VERSION ""

NS_ :

BS_:

BU_: ABS vDSU_FD_C vFD_C ECS RCU ICSC ESC RWS TPMS GW_RGW EPB FCU_C SAS EBB CGW_CCU MDPS RWA VPC_C BDC_C SFA

BO_ 2683321087 SFA_Mon_300ms: 24 SFA
 SG_ SFA_History_DTC : 89|24@1+ (1,0) [0|0] "" Vector__XXX
 SG_ SFA_DTC_Status : 113|1@1+ (1,0) [0|1] "" Vector__XXX
 SG_ SFA_DTC : 65|24@1+ (1,0) [0|0] "" Vector__XXX
 SG_ Align_DiffAg : 49|16@1- (0.1,0) [0|0] "Deg" Vector__XXX
 SG_ ECU1_PrvCANSts : 1|1@1+ (1,0) [0|1] "" Vector__XXX
 SG_ SFA_IMCStatus : 0|1@1+ (1,0) [0|1] "" Vector__XXX
 SG_ SFA1_Yawrate : 17|16@1+ (0.005,-163.84) [-163.84|163.83] "Deg/s" Vector__XXX
 SG_ SFA1_OLPStatus : 16|1@1+ (1,0) [0|1] "" Vector__XXX
 SG_ SFA1_OHPStatus : 15|1@1+ (1,0) [0|1] "" Vector__XXX
 SG_ SFA1_MotorCur : 129|16@1- (0.1,0) [-200|200] "A" Vector__XXX
 SG_ SFA1_LatG : 33|16@1+ (0.000127465,-4.17677312) [-4.17677312|4.1765] "g" Vector__XXX
 SG_ SFA1_IGNStatus : 14|1@1+ (1,0) [0|1] "" Vector__XXX
 SG_ SFA1_BatteryVoltage : 2|12@1+ (0.01,0) [0|40.95] "V" Vector__XXX

BO_ 2683325183 RWA_Mon_300ms: 24 RWA
 SG_ RWA_IMCStatus : 0|1@1+ (1,0) [0|1] "" Vector__XXX
 SG_ RWA_History_DTC : 54|24@1+ (1,0) [0|0] "" Vector__XXX
 SG_ RWA_DTC_Status : 78|1@1+ (1,0) [0|1] "" Vector__XXX
 SG_ RWA_DTC : 30|24@1+ (1,0) [0|0] "" Vector__XXX
 SG_ RWA1_IGNStatus : 13|1@1+ (1,0) [0|1] "" Vector__XXX
 SG_ RWA1_BatteryVoltage : 1|12@1+ (0.01,0) [0|41] "V" Vector__XXX
 SG_ RWA1_AbsoulteAng : 14|16@1- (0.1,0) [0|0] "Deg" Vector__XXX

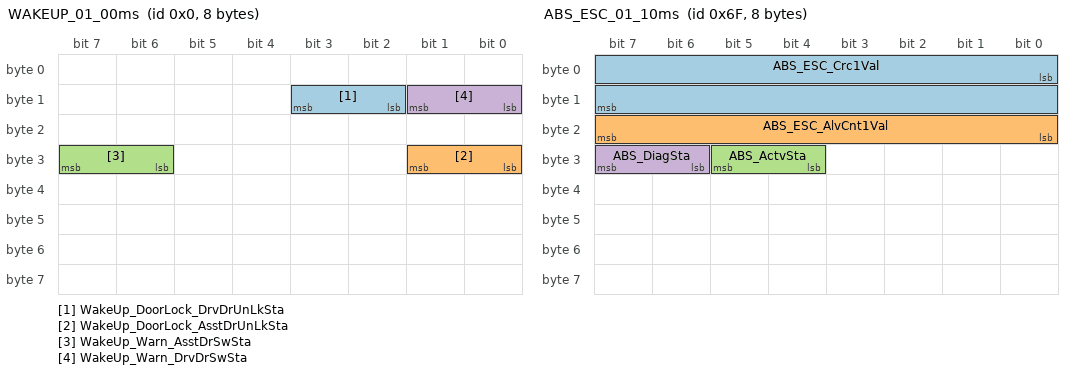
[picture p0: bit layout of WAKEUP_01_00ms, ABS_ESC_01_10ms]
BO_ 0 WAKEUP_01_00ms: 8 CGW_CCU
 SG_ WakeUp_DoorLock_DrvDrUnLkSta : 10|2@1+ (1,0) [0|0] ""  GW_RGW,RWA,SFA
 SG_ WakeUp_DoorLock_AsstDrUnLkSta : 24|2@1+ (1,0) [0|0] ""  GW_RGW,RWA,SFA
 SG_ WakeUp_Warn_AsstDrSwSta : 30|2@1+ (1,0) [0|0] ""  GW_RGW,RWA,SFA
 SG_ WakeUp_Warn_DrvDrSwSta : 8|2@1+ (1,0) [0|0] ""  GW_RGW,RWA,SFA

BO_ 548 ALDC_01_100ms: 32 CGW_CCU
 SG_ ALDC_Crc1Val : 0|16@1+ (1,0) [0|0] ""  RWA,SFA
 SG_ ALDC_AlvCnt1Val : 16|8@1+ (1,0) [0|0] ""  RWA,SFA
 SG_ ALDC_SysOpSta : 28|2@1+ (1,0) [0|0] ""  RWA,SFA
 SG_ ALDC_SysFltSta : 42|2@1+ (1,0) [0|0] ""  RWA,SFA

BO_ 549 CLU_02_100ms: 16 CGW_CCU
 SG_ CLU_Crc2Val : 0|16@1+ (1,0) [0|0] ""  BDC_C,ESC,GW_RGW,ICSC,MDPS,RCU,SFA,VPC_C
 SG_ CLU_DrvngModSwSta : 104|4@1+ (1,0) [0|0] ""  ECS,ESC,GW_RGW,ICSC,MDPS,RCU,SFA,VPC_C
 SG_ CLU_AlvCnt2Val : 16|8@1+ (1,0) [0|0] ""  BDC_C,ESC,GW_RGW,ICSC,MDPS,RCU,SFA,VPC_C

BO_ 517 ICSC_02_100ms: 24 ICSC
 SG_ ICSC_Crc2Val : 0|16@1+ (1,0) [0|0] ""  CGW_CCU,ECS,ESC,GW_RGW,RCU,RWS,SFA,VPC_C
 SG_ ICSC_AlvCnt2Val : 16|8@1+ (1,0) [0|0] ""  CGW_CCU,ECS,ESC,GW_RGW,RCU,RWS,SFA,VPC_C
 SG_ DMIC_MdpsModSta : 56|4@1+ (1,0) [0|0] ""  GW_RGW,MDPS,SFA

BO_ 520 HOD_FD_01_100ms: 16 CGW_CCU
 SG_ HOD_FD_Crc1Val : 0|16@1+ (1,0) [0|0] ""  GW_RGW,SFA
 SG_ HOD_FD_AlvCnt1Val : 16|8@1+ (1,0) [0|0] ""  GW_RGW,SFA
 SG_ HOD_Dir_Status : 80|3@1+ (1,0) [0|0] ""  GW_RGW,SFA
 SG_ HOD_Option : 88|2@1+ (1,0) [0|0] ""  GW_RGW,SFA

BO_ 53 VCU_01_10ms: 32 CGW_CCU
 SG_ VCU_Crc1Val : 0|16@1+ (1,0) [0|0] ""  BDC_C,ESC,MDPS,RWA,RWS,SFA
 SG_ VCU_AlvCnt1Val : 16|8@1+ (1,0) [0|0] ""  BDC_C,ESC,MDPS,RWA,RWS,SFA
 SG_ VCU_EvDrvRdySta : 28|2@1+ (1,0) [0|3] ""  BDC_C,ECS,EPB,ESC,MDPS,RWA,RWS,SFA
 SG_ VCU_GearPosSta : 32|4@1+ (1,0) [0|15] ""  BDC_C,ECS,EPB,ESC,MDPS,RWA,RWS,SFA
 SG_ VCU_AccPedDepVal : 40|8@1+ (0.3921568627,0) [0|100] "%"  ECS,EPB,ESC,MDPS,RWA,RWS,SFA

BO_ 64 TCU_01_10ms: 32 CGW_CCU
 SG_ TCU_Crc1Val : 0|16@1+ (1,0) [0|0] ""  BDC_C,MDPS,RWS,SFA
 SG_ TCU_AlvCnt1Val : 16|8@1+ (1,0) [0|0] ""  BDC_C,MDPS,RWS,SFA
 SG_ TCU_CurrGearSta : 64|4@1+ (1,0) [0|0] ""  MDPS,SFA

BO_ 74 IMU_01_10ms: 32 CGW_CCU
 SG_ IMU_Crc1Val : 0|16@1+ (1,0) [0|0] ""  ECS,ESC,FCU_C,GW_RGW,ICSC,MDPS,RCU,RWS,SFA,VPC_C
 SG_ IMU_AlvCnt1Val : 16|8@1+ (1,0) [0|0] ""  ECS,ESC,FCU_C,GW_RGW,ICSC,MDPS,RCU,RWS,SFA,VPC_C
 SG_ IMU_YawSigSta : 24|4@1+ (1,0) [0|0] ""  ESC,FCU_C,GW_RGW,MDPS,RCU,RWS,SFA,VPC_C
 SG_ IMU_LatAccelSigSta : 28|4@1+ (1,0) [0|0] ""  ECS,ESC,FCU_C,GW_RGW,MDPS,RCU,RWS,SFA,VPC_C
 SG_ IMU_AcuRstSta : 44|4@1+ (1,0) [0|0] ""  ECS,ESC,GW_RGW,MDPS,RCU,SFA
 SG_ IMU_YawRtVal : 64|16@1+ (0.005,-163.84) [0|0] "˚/s"  ESC,FCU_C,GW_RGW,ICSC,MDPS,RCU,RWS,SFA,VPC_C
 SG_ IMU_LatAccelVal : 80|16@1+ (0.000127465,-4.17677312) [0|0] "g"  ECS,ESC,FCU_C,GW_RGW,ICSC,MDPS,RCU,RWS,SFA,VPC_C

BO_ 101 IEB_01_10ms: 32 ESC
 SG_ IEB_BrkActvSta : 56|2@1+ (1,0) [0|0] ""  CGW_CCU,EPB,GW_RGW,MDPS,RCU,SFA

BO_ 96 ESC_01_10ms: 32 ESC
 SG_ ESC_Crc1Val : 0|16@1+ (1,0) [0|0] ""  CGW_CCU,FCU_C,MDPS,RCU,RWS,SFA,VPC_C
 SG_ ESC_CylPrsrVal : 128|12@1+ (0.1,0) [0|0] "Bar"  CGW_CCU,ECS,EPB,ICSC,MDPS,RCU,RWS,SFA,VPC_C
 SG_ ESC_VsmActvSta : 152|2@1+ (1,0) [0|0] ""  CGW_CCU,MDPS,RCU,SFA
 SG_ ESC_VsmDfctvSta : 154|2@1+ (1,0) [0|0] ""  MDPS,RCU,SFA
 SG_ ESC_VsmCtrlModSta : 156|3@1+ (1,0) [0|0] ""  MDPS,RCU,SFA
 SG_ ESC_AlvCnt1Val : 16|8@1+ (1,0) [0|0] ""  CGW_CCU,FCU_C,MDPS,RCU,RWS,SFA,VPC_C
 SG_ ESC_StrTqReq : 160|12@1+ (0.01,-20.48) [0|0] "Nm"  MDPS,RCU,SFA
 SG_ TCS_Sta : 64|4@1+ (1,0) [0|0] ""  CGW_CCU,EPB,FCU_C,ICSC,MDPS,RCU,RWS,SFA,VPC_C
 SG_ ESC_Sta : 72|4@1+ (1,0) [0|0] ""  CGW_CCU,ECS,EPB,FCU_C,ICSC,MDPS,RCU,RWS,SFA,VPC_C

BO_ 111 ABS_ESC_01_10ms: 8 ESC
 SG_ ABS_ESC_Crc1Val : 0|16@1+ (1,0) [0|0] ""  CGW_CCU,FCU_C,MDPS,RCU,RWS,SFA,VPC_C
 SG_ ABS_ESC_AlvCnt1Val : 16|8@1+ (1,0) [0|0] ""  CGW_CCU,FCU_C,MDPS,RCU,RWS,SFA,VPC_C
 SG_ ABS_ActvSta : 28|2@1+ (1,0) [0|0] ""  CGW_CCU,ECS,EPB,FCU_C,ICSC,MDPS,RCU,RWS,SFA,VPC_C
 SG_ ABS_DiagSta : 30|2@1+ (1,0) [0|0] ""  CGW_CCU,EPB,MDPS,RCU,SFA,VPC_C

BO_ 597 LDC_01_100ms: 32 CGW_CCU
 SG_ LDC_Crc1Val : 0|16@1+ (1,0) [0|0] ""  RWA,SFA
 SG_ LDC_AlvCnt1Val : 16|8@1+ (1,0) [0|0] ""  RWA,SFA
 SG_ LDC_SysOpSta : 28|2@1+ (1,0) [0|0] ""  RWA,SFA
 SG_ LDC_SysFltSta : 42|2@1+ (1,0) [0|0] ""  RWA,SFA

BO_ 647 CCU_MCU_01_200ms: 8 CGW_CCU
 SG_ CCU_update_enable : 26|2@1- (1,0) [0|0] ""  ESC,GW_RGW,MDPS,RWA,SFA

BO_ 160 WHL_01_10ms: 24 ABS
 SG_ WHL_Crc1Val : 0|16@1+ (1,0) [0|0] ""  BDC_C,CGW_CCU,FCU_C,MDPS,RCU,RWA,RWS,SFA,VPC_C
 SG_ WHL_SpdRRVal : 112|14@1+ (0.03125,0) [0|0] "km^h"  BDC_C,CGW_CCU,ECS,EPB,FCU_C,MDPS,RCU,RWA,RWS,SFA,TPMS,VPC_C
 SG_ WHL_AlvCnt1Val : 16|8@1+ (1,0) [0|0] ""  BDC_C,CGW_CCU,FCU_C,MDPS,RCU,RWA,RWS,SFA,VPC_C
 SG_ WHL_SpdFLVal : 64|14@1+ (0.03125,0) [0|0] "km^h"  BDC_C,CGW_CCU,ECS,EPB,FCU_C,MDPS,RCU,RWA,RWS,SFA,TPMS,VPC_C,vDSU_FD_C
 SG_ WHL_SpdFRVal : 80|14@1+ (0.03125,0) [0|0] "km^h"  BDC_C,CGW_CCU,ECS,EPB,FCU_C,MDPS,RCU,RWA,RWS,SFA,TPMS,VPC_C
 SG_ WHL_SpdRLVal : 96|14@1+ (0.03125,0) [0|0] "km^h"  BDC_C,CGW_CCU,ECS,EPB,FCU_C,MDPS,RCU,RWA,RWS,SFA,TPMS,VPC_C

BO_ 176 ICSC_01_10ms: 32 VPC_C
 SG_ ICSC_Crc1Val : 0|16@1+ (1,0) [0|0] ""  CGW_CCU,ECS,ESC,GW_RGW,RCU,RWS,SFA
 SG_ ICSC_AlvCnt1Val : 16|8@1+ (1,0) [0|0] ""  CGW_CCU,ECS,ESC,GW_RGW,RCU,RWS,SFA
 SG_ ESA_MdpsStrTqReq : 168|12@1+ (0.01,-20.48) [0|0] ""  ECS,ESC,GW_RGW,MDPS,SFA
 SG_ ESA_MdpsActvSta : 180|2@1+ (1,0) [0|0] ""  ECS,ESC,GW_RGW,MDPS,SFA
 SG_ ESA_MdpsDfctvSta : 182|2@1+ (1,0) [0|0] ""  ECS,ESC,GW_RGW,MDPS,SFA
 SG_ SFO_ActvSta : 232|3@1+ (1,0) [0|0] ""  GW_RGW,SFA

BO_ 745 PDC_FD_15_300ms: 32 CGW_CCU
 SG_ PDC_FD_Crc15Val : 0|16@1+ (1,0) [0|0] ""  ABS,EBB,ECS,EPB,ESC,GW_RGW,ICSC,MDPS,RCU,RWA,RWS,SAS,SFA,TPMS
 SG_ PDC_FD_AlvCnt15Val : 16|8@1+ (1,0) [0|0] ""  ABS,EBB,ECS,EPB,ESC,GW_RGW,ICSC,MDPS,RCU,RWA,RWS,SAS,SFA,TPMS
 SG_ PDC_ResetPreWrngForOthers : 42|2@1+ (1,0) [0|0] ""  ABS,EBB,ECS,EPB,ESC,GW_RGW,ICSC,MDPS,RCU,RWA,RWS,SAS,SFA,TPMS
 SG_ PDC_ResetReqForOthers : 46|2@1+ (1,0) [0|0] ""  ABS,EBB,ECS,EPB,ESC,GW_RGW,ICSC,MDPS,RCU,RWA,RWS,SAS,SFA,TPMS

BO_ 203 ADAS_CMD_35_10ms: 24 CGW_CCU
 SG_ ADAS_CMD_Crc35Val : 0|16@1+ (1,0) [0|0] "0"  FCU_C,GW_RGW,MDPS,SFA
 SG_ ADAS_CMD_AlvCnt35Val : 16|8@1+ (1,0) [0|0] "0"  FCU_C,GW_RGW,MDPS,SFA
 SG_ ADAS_ActvACISta : 24|4@1+ (1,0) [0|0] ""  GW_RGW,MDPS,SFA
 SG_ ADAS_ActvACILvl2Sta : 28|4@1+ (1,0) [0|0] ""  ESC,FCU_C,GW_RGW,MDPS,SFA,VPC_C
 SG_ ADAS_StrAnglReqVal : 32|14@1- (0.1,0) [0|0] "Deg"  GW_RGW,MDPS,SFA
 SG_ ADAS_ACIAnglTqRedcGainVal : 48|8@1+ (0.004,0) [0|0] ""  GW_RGW,MDPS,SFA
 SG_ FCA_ESA_ActvSta : 56|2@1+ (1,0) [0|0] ""  GW_RGW,MDPS,SFA
 SG_ FCA_ESA_TqBstGainVal : 64|8@1+ (0.004,0) [0|0] ""  GW_RGW,MDPS,SFA

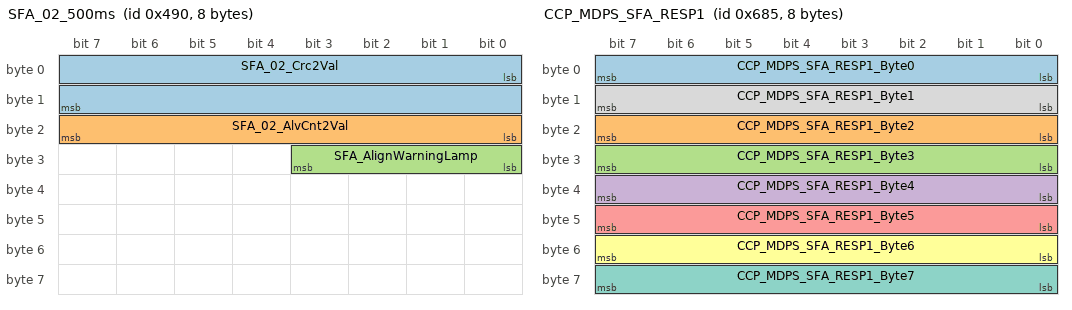
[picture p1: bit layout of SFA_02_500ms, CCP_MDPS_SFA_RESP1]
BO_ 1168 SFA_02_500ms: 8 SFA
 SG_ SFA_02_Crc2Val : 0|16@1+ (1,0) [0|0] "0"  CGW_CCU
 SG_ SFA_02_AlvCnt2Val : 16|8@1+ (1,0) [0|0] "0"  CGW_CCU
 SG_ SFA_AlignWarningLamp : 24|4@1+ (1,0) [0|0] ""  CGW_CCU

BO_ 221 SFA_01_10ms: 32 SFA
 SG_ Rack_Command_Diff : 180|20@1+ (0.001,-524) [0|0] "" Vector__XXX
 SG_ SFA1_RelativeAg : 164|16@1- (0.1,0) [0|0] "Deg" Vector__XXX
 SG_ SFA1_MotorTq : 136|12@1+ (0.1,-204.8) [0|0] "Nm" Vector__XXX
 SG_ SFA1_AbsoluteAg : 148|16@1- (0.1,0) [0|0] "Deg" Vector__XXX
 SG_ SFA_Crc1Val : 0|16@1+ (1,0) [0|0] "0"  CGW_CCU,GW_RGW,RWA,RWS
 SG_ SFA_CenteringStatus : 102|3@1+ (1,0) [0|0] ""  GW_RGW,RWA
 SG_ SbW_CenteringStatus : 105|3@1+ (1,0) [0|0] ""  GW_RGW,RWA
 SG_ SFA_IgnitionStatus : 108|1@1+ (1,0) [0|0] ""  GW_RGW,RWA
 SG_ SFA_OHP_Status : 109|1@1+ (1,0) [0|0] ""  GW_RGW,RWA
 SG_ SFA_SFA1EcuStatus : 110|4@1+ (1,0) [0|0] ""  GW_RGW,RWA
 SG_ SFA_SFA2EcuStatus : 114|4@1+ (1,0) [0|0] ""  GW_RGW,RWA
 SG_ SFA_RWA1EcuStatus : 118|4@1+ (1,0) [0|0] ""  GW_RGW,RWA
 SG_ SFA_RWA2EcuStatus : 122|4@1+ (1,0) [0|0] ""  GW_RGW,RWA
 SG_ SFA_SteerWheelAngSpd : 128|8@1+ (4,0) [0|0] "Deg/s"  GW_RGW,RWA,VPC_C
 SG_ SFA_AlvCnt1Val : 16|8@1+ (1,0) [0|0] "0"  CGW_CCU,GW_RGW,RWA,RWS
 SG_ SFA_SteerWheelTorque : 24|12@1+ (0.02,-40) [0|0] ""  GW_RGW,RWA
 SG_ SFA_SteerWheelAngle : 36|16@1+ (0.02,-655) [0|0] ""  GW_RGW,RWA,VPC_C
 SG_ Reprogram_State_SFA1 : 52|2@1+ (1,0) [0|0] ""  CGW_CCU
 SG_ SFA1_ResetOpSta : 54|2@1+ (1,0) [0|0] "" Vector__XXX
 SG_ SFA_ControlMode : 56|3@1+ (1,0) [0|0] ""  GW_RGW,RWA
 SG_ SFA_EcuRole : 59|2@1+ (1,0) [0|0] ""  GW_RGW,RWA
 SG_ SFA_WarningLamp : 61|3@1+ (1,0) [0|0] ""  GW_RGW,RWA
 SG_ SFA_RackCommand : 64|20@1+ (0.001,-524) [0|0] ""  GW_RGW,RWA
 SG_ SFA_FailoverActvSta : 84|3@1+ (1,0) [0|0] ""  GW_RGW,RWA,RWS,VPC_C
 SG_ SFA_BrakeReqActSta : 87|3@1+ (1,0) [0|0] ""  GW_RGW,RWA
 SG_ SFA_CreepReqActSta : 90|3@1+ (1,0) [0|0] ""  GW_RGW,RWA,VPC_C
 SG_ SbW_EvDrvRdyEnb : 93|3@1+ (1,0) [0|0] ""  GW_RGW,RWA,VPC_C
 SG_ SFA_CluWarningLamp : 96|2@1+ (1,0) [0|0] ""  CGW_CCU,GW_RGW,RWA,RWS
 SG_ SFA_CluWarningSentence : 98|4@1+ (1,0) [0|0] ""  CGW_CCU,GW_RGW,RWA

BO_ 222 RWA_01_10ms: 32 RWA
 SG_ RWA1_RelatIveAg : 176|16@1- (0.1,0) [0|0] "Deg" Vector__XXX
 SG_ RWA1_MotorTorque : 160|12@1+ (0.1,-204.8) [0|0] "Nm" Vector__XXX
 SG_ RWA1_MotorCur : 192|16@1- (0.1,0) [-200|200] "A" Vector__XXX
 SG_ RWA1_AOSAg : 144|16@1- (0.1,0) [0|0] "Deg" Vector__XXX
 SG_ RWA_Crc1Val : 0|16@1+ (1,0) [0|0] "0"  CGW_CCU,ESC,GW_RGW,RWS,SFA
 SG_ RWA_IgnitionStatus : 112|1@1+ (1,0) [0|0] ""  ESC,GW_RGW,SFA
 SG_ RWA_OHP_Status : 113|1@1+ (1,0) [0|0] ""  ESC,GW_RGW,SFA
 SG_ RWA_SFA1EcuStatus : 114|4@1+ (1,0) [0|0] ""  ESC,GW_RGW,SFA
 SG_ RWA_SFA2EcuStatus : 118|4@1+ (1,0) [0|0] ""  ESC,GW_RGW,SFA
 SG_ RWA_RWA1EcuStatus : 122|4@1+ (1,0) [0|0] ""  ESC,GW_RGW,SFA
 SG_ RWA_RWA2EcuStatus : 128|4@1+ (1,0) [0|0] ""  ESC,GW_RGW,SFA
 SG_ RWA_CreepReqActSta : 132|3@1+ (1,0) [0|0] ""  GW_RGW,SFA,VPC_C
 SG_ RWA_PinionAngSpd : 136|8@1+ (4,0) [0|0] "Deg/s"  GW_RGW,SFA
 SG_ RWA_AlvCnt1Val : 16|8@1+ (1,0) [0|0] "0"  CGW_CCU,ESC,GW_RGW,RWS,SFA
 SG_ RWA_RackForce : 24|16@1+ (1,-32767) [0|0] "N"  ESC,GW_RGW,SFA
 SG_ RWA_RackPosition : 40|20@1+ (0.001,-524) [0|0] "mm"  ESC,GW_RGW,SFA
 SG_ Reprogram_State_RWA1 : 60|2@1+ (1,0) [0|0] ""  CGW_CCU
 SG_ RWA1_ResetOpSta : 62|2@1+ (1,0) [0|0] "" Vector__XXX
 SG_ RWA_RackSpeed : 64|20@1+ (0.001,-524) [0|0] "mm/s"  ESC,GW_RGW,SFA
 SG_ RWA_EcuRole : 84|2@1+ (1,0) [0|0] ""  ESC,GW_RGW,SFA
 SG_ RWA_WarningLamp : 86|3@1+ (1,0) [0|0] ""  ESC,GW_RGW,SFA
 SG_ RWA_ControlMode : 89|3@1+ (1,0) [0|0] ""  ESC,GW_RGW,SFA
 SG_ RWA_CenteringStatus : 92|3@1+ (1,0) [0|0] ""  ESC,GW_RGW,SFA
 SG_ RWA_OLP : 95|1@1+ (1,0) [0|0] ""  ESC,GW_RGW,SFA
 SG_ RWA_PinionAngle : 96|16@1- (0.1,0) [0|0] ""  CGW_CCU,ECS,ESC,GW_RGW,RWS,SFA

BO_ 1669 CCP_MDPS_SFA_RESP1: 8 SFA
 SG_ CCP_MDPS_SFA_RESP1_Byte0 : 0|8@1+ (1,0) [0|0] ""  CGW_CCU
 SG_ CCP_MDPS_SFA_RESP1_Byte2 : 16|8@1+ (1,0) [0|0] ""  CGW_CCU
 SG_ CCP_MDPS_SFA_RESP1_Byte3 : 24|8@1+ (1,0) [0|0] ""  CGW_CCU
 SG_ CCP_MDPS_SFA_RESP1_Byte4 : 32|8@1+ (1,0) [0|0] ""  CGW_CCU
 SG_ CCP_MDPS_SFA_RESP1_Byte5 : 40|8@1+ (1,0) [0|0] ""  CGW_CCU
 SG_ CCP_MDPS_SFA_RESP1_Byte6 : 48|8@1+ (1,0) [0|0] ""  CGW_CCU
 SG_ CCP_MDPS_SFA_RESP1_Byte7 : 56|8@1+ (1,0) [0|0] ""  CGW_CCU
 SG_ CCP_MDPS_SFA_RESP1_Byte1 : 8|8@1+ (1,0) [0|0] ""  CGW_CCU

BO_ 238 RWA2_01_10ms: 32 GW_RGW
 SG_ RWA2_Crc1Val : 0|16@1+ (1,0) [0|0] "0"  RWS,SFA
 SG_ RWA_R2_IgnitionStatus : 112|1@1+ (1,0) [0|0] ""  SFA
 SG_ RWA_R2_OHP_Status : 113|1@1+ (1,0) [0|0] ""  SFA
 SG_ RWA_R2_SFA1EcuStatus : 114|4@1+ (1,0) [0|0] ""  SFA
 SG_ RWA_R2_SFA2EcuStatus : 118|4@1+ (1,0) [0|0] ""  SFA
 SG_ RWA_R2_RWA1EcuStatus : 122|4@1+ (1,0) [0|0] ""  SFA
 SG_ RWA_R2_RWA2EcuStatus : 128|4@1+ (1,0) [0|0] ""  SFA
 SG_ RWA_R2_CreepReqActSta : 132|3@1+ (1,0) [0|0] ""  SFA
 SG_ RWA_R2_PinionAngSpd : 136|8@1+ (4,0) [0|0] "Deg/s"  SFA
 SG_ RWA2_AlvCnt1Val : 16|8@1+ (1,0) [0|0] "0"  RWS,SFA
 SG_ RWA_R2_RackForce : 24|16@1+ (1,-32767) [0|0] "N"  SFA
 SG_ RWA_R2_RackPosition : 40|20@1+ (0.001,-524) [0|0] "mm"  SFA
 SG_ RWA_R2_RackSpeed : 64|20@1+ (0.001,-524) [0|0] "mm/s"  SFA
 SG_ RWA_R2_EcuRole : 84|2@1+ (1,0) [0|0] ""  SFA
 SG_ RWA_R2_WarningLamp : 86|3@1+ (1,0) [0|0] ""  SFA
 SG_ RWA_R2_ControlMode : 89|3@1+ (1,0) [0|0] ""  SFA
 SG_ RWA_R2_CenteringStatus : 92|3@1+ (1,0) [0|0] ""  SFA
 SG_ RWA_R2_OLP : 95|1@1+ (1,0) [0|0] ""  SFA
 SG_ RWA_R2_PinionAngle : 96|16@1- (0.1,0) [0|0] ""  RWS,SFA

BO_ 237 SFA2_01_10ms: 32 GW_RGW
 SG_ SFA2_Crc1Val : 0|16@1+ (1,0) [0|0] "0"  RWA,RWS
 SG_ SFA_R2_CenteringStatus : 102|3@1+ (1,0) [0|0] ""  RWA
 SG_ SbW_R2_CenteringStatus : 105|3@1+ (1,0) [0|0] ""  RWA
 SG_ SFA_R2_IgnitionStatus : 108|1@1+ (1,0) [0|0] ""  RWA
 SG_ SFA_R2_OHP_Status : 109|1@1+ (1,0) [0|0] ""  RWA
 SG_ SFA_R2_SFA1EcuStatus : 110|4@1+ (1,0) [0|0] ""  RWA
 SG_ SFA_R2_SFA2EcuStatus : 114|4@1+ (1,0) [0|0] ""  RWA
 SG_ SFA_R2_RWA1EcuStatus : 118|4@1+ (1,0) [0|0] ""  RWA
 SG_ SFA_R2_RWA2EcuStatus : 122|4@1+ (1,0) [0|0] ""  RWA
 SG_ SFA_R2_SteerWheelAngSpd : 128|8@1+ (4,0) [0|0] "Deg/s"  RWA
 SG_ SFA2_AlvCnt1Val : 16|8@1+ (1,0) [0|0] "0"  RWA,RWS
 SG_ SFA_R2_SteerWheelTorque : 24|12@1+ (0.02,-40) [0|0] ""  RWA
 SG_ SFA_R2_SteerWheelAngle : 36|16@1+ (0.02,-655) [0|0] ""  RWA
 SG_ SFA_R2_ControlMode : 56|3@1+ (1,0) [0|0] ""  RWA
 SG_ SFA_R2_EcuRole : 59|2@1+ (1,0) [0|0] ""  RWA
 SG_ SFA_R2_WarningLamp : 61|3@1+ (1,0) [0|0] ""  RWA
 SG_ SFA_R2_RackCommand : 64|20@1+ (0.001,-524) [0|0] ""  RWA
 SG_ SFA_R2_FailoverActvSta : 84|3@1+ (1,0) [0|0] ""  RWA,RWS
 SG_ SFA_R2_BrakeReqActSta : 87|3@1+ (1,0) [0|0] ""  RWA
 SG_ SFA_R2_CreepReqActSta : 90|3@1+ (1,0) [0|0] ""  RWA
 SG_ SbW_R2_EvDrvRdyEnb : 93|3@1+ (1,0) [0|0] ""  RWA
 SG_ SFA_R2_CluWarningLamp : 96|2@1+ (1,0) [0|0] ""  RWA
 SG_ SFA_R2_CluWarningSentence : 98|4@1+ (1,0) [0|0] ""  RWA

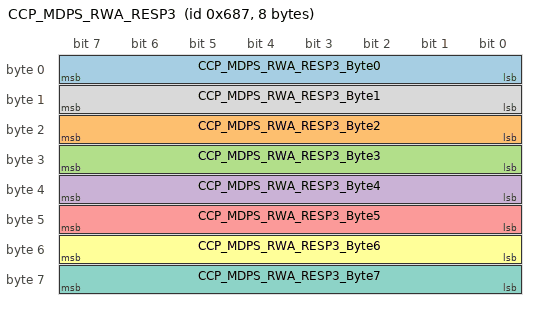
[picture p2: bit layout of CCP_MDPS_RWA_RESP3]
BO_ 1671 CCP_MDPS_RWA_RESP3: 8 GW_RGW
 SG_ CCP_MDPS_RWA_RESP3_Byte0 : 0|8@1+ (1,0) [0|0] ""  CGW_CCU
 SG_ CCP_MDPS_RWA_RESP3_Byte2 : 16|8@1+ (1,0) [0|0] ""  CGW_CCU
 SG_ CCP_MDPS_RWA_RESP3_Byte3 : 24|8@1+ (1,0) [0|0] ""  CGW_CCU
 SG_ CCP_MDPS_RWA_RESP3_Byte4 : 32|8@1+ (1,0) [0|0] ""  CGW_CCU
 SG_ CCP_MDPS_RWA_RESP3_Byte5 : 40|8@1+ (1,0) [0|0] ""  CGW_CCU
 SG_ CCP_MDPS_RWA_RESP3_Byte6 : 48|8@1+ (1,0) [0|0] ""  CGW_CCU
 SG_ CCP_MDPS_RWA_RESP3_Byte7 : 56|8@1+ (1,0) [0|0] ""  CGW_CCU
 SG_ CCP_MDPS_RWA_RESP3_Byte1 : 8|8@1+ (1,0) [0|0] ""  CGW_CCU

BO_ 234 MDPS_01_10ms: 24 SFA
 SG_ MDPS_Crc1Val : 0|16@1+ (1,0) [0|0] ""  CGW_CCU,ESC,ICSC,RCU,RWA,RWS,VPC_C
 SG_ MDPS_LoamModSta : 112|2@1+ (1,0) [0|0] ""  CGW_CCU,RWA
 SG_ MDPS_HDPSpprtSWVer : 114|5@1+ (1,0) [0|0] ""  CGW_CCU,RWA
 SG_ MDPS_ADASAciActvSta : 120|4@1+ (1,0) [0|0] ""  CGW_CCU,ESC,RWA,RWS
 SG_ MDPS_ADASAciPluginSta : 124|2@1+ (1,0) [0|0] ""  RWA
 SG_ MDPS_ADAS_AciFltSig : 126|2@1+ (1,0) [0|0] ""  CGW_CCU,ESC,RWA
 SG_ MDPS_EstStrAnglVal : 128|16@1- (0.1,0) [0|0] "Deg"  CGW_CCU,RWA,RWS
 SG_ MDPS_ADASAciActvSta_Lv2 : 144|4@1+ (1,0) [0|0] ""  CGW_CCU,RWA
 SG_ MDPS_ADAS_AciFltSig_Lv2 : 148|3@1+ (1,0) [0|0] ""  CGW_CCU,RWA
 SG_ MDPS_TpaPlugInSta : 152|2@1+ (1,0) [0|0] ""  RWA,VPC_C
 SG_ MDPS_TpaCanfltSta : 154|2@1+ (1,0) [0|0] ""  RWA,VPC_C
 SG_ MDPS_TpaModeSta : 156|4@1+ (1,0) [0|0] ""  RWA,VPC_C
 SG_ MDPS_AlvCnt1Val : 16|8@1+ (1,0) [0|0] ""  CGW_CCU,ESC,ICSC,RCU,RWA,RWS,VPC_C
 SG_ MDPS_TpaStrAnglVal : 160|16@1- (0.1,0) [0|0] "Deg"  RWA,VPC_C
 SG_ MDPS_WrngLmpSta : 24|3@1+ (1,0) [0|0] ""  CGW_CCU,ESC,ICSC,RCU,RWA,RWS
 SG_ MDPS_Typ : 27|3@1+ (1,0) [0|0] ""  CGW_CCU,ICSC,RWA
 SG_ MDPS_EngIdleRpmReq : 30|2@1+ (1,0) [0|0] ""  CGW_CCU,RWA
 SG_ MDPS_VsmPlgInSta : 32|2@1+ (1,0) [0|0] "flag"  ESC,ICSC,RCU,RWA
 SG_ MDPS_VsmDfctvSta : 34|2@1+ (1,0) [0|0] ""  ESC,ICSC,RCU,RWA
 SG_ MDPS_VsmSigErrSta : 36|2@1+ (1,0) [0|0] ""  ESC,RCU,RWA
 SG_ MDPS_PaPlugInSta : 38|2@1+ (1,0) [0|0] ""  CGW_CCU,ESC,RCU,RWA
 SG_ MDPS_PaModeSta : 40|4@1+ (1,0) [0|0] ""  CGW_CCU,RWA
 SG_ MDPS_PaCanfltSta : 44|2@1+ (1,0) [0|0] ""  CGW_CCU,RWA
 SG_ MDPS_LkaPlgInSta : 46|2@1+ (1,0) [0|0] ""  CGW_CCU,ICSC,RWA
 SG_ MDPS_LkaToiActvSta : 48|2@1+ (1,0) [0|0] ""  CGW_CCU,RWA
 SG_ MDPS_LkaToiUnblSta : 50|2@1+ (1,0) [0|0] ""  CGW_CCU,RWA
 SG_ MDPS_LkaToiFltSta : 52|2@1+ (1,0) [0|0] ""  CGW_CCU,RWA
 SG_ MDPS_LkaFailSta : 54|2@1+ (1,0) [0|0] ""  CGW_CCU,RWA
 SG_ MDPS_ResetOpSta : 59|2@1+ (1,0) [0|0] "" Vector__XXX
 SG_ MDPS_CurrModVal : 61|3@1+ (1,0) [0|0] ""  CGW_CCU,RWA
 SG_ MDPS_OutTqVal : 64|12@1+ (0.1,-204.8) [0|0] "Nm"  CGW_CCU,ESC,ICSC,RCU,RWA
 SG_ MDPS_VsmActResp : 76|2@1+ (1,0) [0|0] ""  ESC,RCU,RWA
 SG_ Reprogram_State_MDPS : 78|2@1+ (1,0) [0|0] ""  CGW_CCU
 SG_ MDPS_StrTqSnsrVal : 80|13@1+ (0.005,-20.48) [0|0] "Nm"  CGW_CCU,ESC,ICSC,RCU,RWA,VPC_C
 SG_ MDPS_PaStrAnglVal : 96|16@1- (0.1,0) [0|0] "Deg"  CGW_CCU,RWA

BO_TX_BU_ 517 : ICSC,VPC_C;
BO_TX_BU_ 111 : ESC,ABS;
BO_TX_BU_ 160 : ABS,ESC;
BO_TX_BU_ 176 : VPC_C,ICSC;
BO_TX_BU_ 1669 : SFA,GW_RGW,MDPS;
BO_TX_BU_ 1671 : GW_RGW,RWA,MDPS;
BO_TX_BU_ 234 : SFA,MDPS;

CM_ SG_ 2683321087 SFA_History_DTC "SBW DTC Number (C 생략후 4자리 표기. Ex. C1101.17 -> 510117)
C : 01, 1 : 01 -> 0101 = C, 다수의 DTC 존재시 순차적으로 하나씩 Tx)";
CM_ SG_ 2683321087 SFA_DTC_Status "DTC Status";
CM_ SG_ 2683321087 SFA_DTC "SBW DTC Number (C 생략후 4자리 표기. Ex. C1101.17 -> 510117,
C : 01, 1 : 01 -> 0101 = C, 다수의 DTC 존재시 순차적으로 하나씩 Tx)";
CM_ SG_ 2683321087 Align_DiffAg "SFA RWA Align angle difference (SFA 절대각 - RWA 절대각)";
CM_ SG_ 2683321087 ECU1_PrvCANSts "#1 Private CAN status";
CM_ SG_ 2683321087 SFA_IMCStatus "SFA IMC status";
CM_ SG_ 2683321087 SFA1_Yawrate "SFA internal yaw rate value";
CM_ SG_ 2683321087 SFA1_OLPStatus "SFA1 OLP status";
CM_ SG_ 2683321087 SFA1_OHPStatus "SFA1 OHP status";
CM_ SG_ 2683321087 SFA1_MotorCur "SFA1_MotorCurrent (MotOutTq*MotAgSpdFild/BattU)";
CM_ SG_ 2683321087 SFA1_LatG "SFA internal Lateral acceleration";
CM_ SG_ 2683321087 SFA1_IGNStatus "SFA#1 IGN status";
CM_ SG_ 2683321087 SFA1_BatteryVoltage "SFA#1 Battery voltage";
CM_ SG_ 2683325183 RWA_History_DTC "SBW DTC Number (C 생략후 4자리 표기. Ex. C1101.17 -> 510117)
C : 01, 1 : 01 -> 0101 = C, 다수의 DTC 존재시 순차적으로 하나씩 Tx)";
CM_ SG_ 2683325183 RWA_DTC_Status "DTC Status";
CM_ SG_ 2683325183 RWA_DTC "SBW DTC Number (C 생략후 4자리 표기. Ex. C1101.17 -> 510117,
C : 01, 1 : 01 -> 0101 = C, 다수의 DTC 존재시 순차적으로 하나씩 Tx)";
CM_ SG_ 2683325183 RWA1_IGNStatus "RWA#1 IGN status";
CM_ SG_ 2683325183 RWA1_BatteryVoltage "RWA#1 Battery voltage";
CM_ BO_ 0 "[EC] On Event and On Change";
CM_ SG_ 0 WakeUp_DoorLock_DrvDrUnLkSta "For Wakeup : DoorLock_DriverDoorUnLockStatus ##2G## -  - C_DrvUnlockState,CF_Gway_DrvUnlockState";
CM_ SG_ 0 WakeUp_DoorLock_AsstDrUnLkSta "For Wakeup : DoorLock_AssistDoorUnLockStatus ##2G## -  - C_AstUnlockState,DoorLock_AsstDrUnLkSta";
CM_ SG_ 0 WakeUp_Warn_AsstDrSwSta "For Wakeup : Warn_AssistDoorSwitchStatus ##2G## -  - C_AstDrSw,CF_Gway_AstDrSw,Warn_AsstDrSwSta";
CM_ SG_ 0 WakeUp_Warn_DrvDrSwSta "For Wakeup : DoorLock_DriverDoorSwitchStatus ##2G## -  - C_DrvDrSw,CF_Gway_DrvDrSw,Warn_DrvDrSwSta";
CM_ BO_ 548 "[P] Periodic";
CM_ SG_ 548 ALDC_Crc1Val "ALDC_CyclicRedundancyCheck1Value";
CM_ SG_ 548 ALDC_AlvCnt1Val "ALDC_AliveCounter1Value";
CM_ SG_ 548 ALDC_SysOpSta "ALDC_SystemOperatingStatus";
CM_ SG_ 548 ALDC_SysFltSta "ALDC_SystemFaultStatus";
CM_ BO_ 549 "[P] Periodic";
CM_ SG_ 549 CLU_Crc2Val "CLU_CyclicRedundancyCheck2Value";
CM_ SG_ 549 CLU_DrvngModSwSta "CLU_DrivingModeSwitchStatus";
CM_ SG_ 549 CLU_AlvCnt2Val "CLU_AliveCounter2Value";
CM_ BO_ 517 "[P] Periodic";
CM_ SG_ 517 ICSC_Crc2Val "ICSC_CyclicRedundancyCheck2Value";
CM_ SG_ 517 ICSC_AlvCnt2Val "ICSC_AliveCounter2Value";
CM_ SG_ 517 DMIC_MdpsModSta "DMIC_MdpsModeStatus ##2G##ICSC - IVSS11 - MODE_MDPS";
CM_ BO_ 520 "[P] Periodic";
CM_ SG_ 520 HOD_FD_Crc1Val "HOD_FD_CyclicRedundancyCheck1Value";
CM_ SG_ 520 HOD_FD_AlvCnt1Val "HOD_FD_AliveCounter1Value";
CM_ SG_ 520 HOD_Dir_Status "hands on-off status";
CM_ SG_ 520 HOD_Option "HOD_Option";
CM_ BO_ 53 "[P] Periodic";
CM_ SG_ 53 VCU_Crc1Val "VCU_CyclicRedundancyCheck1Value";
CM_ SG_ 53 VCU_AlvCnt1Val "VCU_AliveCounter1Value";
CM_ SG_ 53 VCU_EvDrvRdySta "VCU_EvDriveReadyStatus ##2G##VCU - VCU1 - CF_Vcu_EvRdy";
CM_ SG_ 53 VCU_GearPosSta "VCU_GearPositionStatus ##2G##VCU - VCU1 - CF_Vcu_GarSelDisp";
CM_ SG_ 53 VCU_AccPedDepVal "VCU_AcceleratorPedalDepthValue ##2G##VCU - VCU1 - CR_Vcu_AccPedDep_Pc";
CM_ BO_ 64 "[P] Periodic";
CM_ SG_ 64 TCU_Crc1Val "TCU_CyclicRedundancyCheck1Value";
CM_ SG_ 64 TCU_AlvCnt1Val "TCU_AliveCounter1Value";
CM_ SG_ 64 TCU_CurrGearSta "TCU_CurrentGearStatus";
CM_ BO_ 74 "[P] Periodic";
CM_ SG_ 74 IMU_Crc1Val "IMU_CyclicRedundancyCheck1Value";
CM_ SG_ 74 IMU_AlvCnt1Val "IMU_AliveCounter1Value";
CM_ SG_ 74 IMU_YawSigSta "IMU_YawSignalStatus ##2G##YRS - YRS11 - CF_Yrs_YrStat";
CM_ SG_ 74 IMU_LatAccelSigSta "IMU_LateralAccelerationSignalStatus ##2G##YRS - YRS11 - CF_Yrs_LatAcStat";
CM_ SG_ 74 IMU_AcuRstSta "IMU_AcuResetStatus ##2G##YRS - YRS12 - CF_IMU_ResetStat";
CM_ SG_ 74 IMU_YawRtVal "IMU_YawRateValue ##2G##YRS - YRS11 - CR_Yrs_Yr";
CM_ SG_ 74 IMU_LatAccelVal "IMU_LateralAccelerationValue ##2G##YRS - YRS11 - CR_Yrs_LatAc";
CM_ BO_ 101 "[P] Periodic";
CM_ SG_ 101 IEB_BrkActvSta "IEB_BrakeActiveStatus ##2G##ESC - AHB1 - CF_Esc_BrakeAct";
CM_ BO_ 96 "[P] Periodic";
CM_ SG_ 96 ESC_Crc1Val "ESC_CyclicRedundancyCheck1Value";
CM_ SG_ 96 ESC_CylPrsrVal "ESC_CylinderPressureValue ##2G##ESC - ESP12 - CYL_PRES";
CM_ SG_ 96 ESC_VsmActvSta "ESC_VsmActiveStatus ##2G##ESC - VSM11 - CF_Esc_Act";
CM_ SG_ 96 ESC_VsmDfctvSta "ESC_VsmDefectiveStatus ##2G##ESC - VSM11 - CF_Esc_Def";
CM_ SG_ 96 ESC_VsmCtrlModSta "ESC_VsmControlModeStatus ##2G##ESC - VSM11 - CF_Esc_CtrMode";
CM_ SG_ 96 ESC_AlvCnt1Val "ESC_AliveCounter1Value";
CM_ SG_ 96 ESC_StrTqReq "ESC_SteeringTorqueReqeust ##2G##ESC - TCS15 - CR_Esc_StrTqReq";
CM_ SG_ 96 TCS_Sta "Status of TCS Function";
CM_ SG_ 96 ESC_Sta "Status of ESC Function";
CM_ BO_ 111 "[P] Periodic";
CM_ SG_ 111 ABS_ESC_Crc1Val "ABS_ESC_CyclicRedundancyCheck1Value";
CM_ SG_ 111 ABS_ESC_AlvCnt1Val "ABS_ESC_AliveCounter1Value";
CM_ SG_ 111 ABS_ActvSta "ABS_ActiveStatus ##2G##ESC - TCS11 - ABS_ACT";
CM_ SG_ 111 ABS_DiagSta "ABS_DiagnosticStatus ##2G##ESC - TCS11 - ABS_DIAG";
CM_ BO_ 597 "[P] Periodic";
CM_ SG_ 597 LDC_Crc1Val "LDC_CyclicRedundancyCheck1Value";
CM_ SG_ 597 LDC_AlvCnt1Val "LDC_AliveCounter1Value";
CM_ SG_ 597 LDC_SysOpSta "LDC_SystemOperatingStatus";
CM_ SG_ 597 LDC_SysFltSta "LDC_SystemFaultStatus";
CM_ BO_ 647 "[PE] Periodic and On Event";
CM_ BO_ 160 "[P] Periodic";
CM_ SG_ 160 WHL_Crc1Val "WHL_CyclicRedundancyCheck1Value";
CM_ SG_ 160 WHL_SpdRRVal "WHL_SpeedRearRightValue ##2G##ESC - WHL_SPD11 - WHL_SPD_RR";
CM_ SG_ 160 WHL_AlvCnt1Val "WHL_AliveCounter1Value";
CM_ SG_ 160 WHL_SpdFLVal "WHL_SpeedFrontLeftValue ##2G##ESC - WHL_SPD11 - WHL_SPD_FL";
CM_ SG_ 160 WHL_SpdFRVal "WHL_SpeedFrontRightValue ##2G##ESC - WHL_SPD11 - WHL_SPD_FR";
CM_ SG_ 160 WHL_SpdRLVal "WHL_SpeedRearLeftValue ##2G##ESC - WHL_SPD11 - WHL_SPD_RL";
CM_ BO_ 176 "[P] Periodic";
CM_ SG_ 176 ICSC_Crc1Val "ICSC_CyclicRedundancyCheck1Value";
CM_ SG_ 176 ICSC_AlvCnt1Val "ICSC_AliveCounter1Value";
CM_ SG_ 176 ESA_MdpsStrTqReq "ESA_MdpsSteeringTorqueRequest";
CM_ SG_ 176 ESA_MdpsActvSta "ESA_MdpsActivationStatus";
CM_ SG_ 176 ESA_MdpsDfctvSta "ESA_MdpsDefectiveStatus";
CM_ SG_ 176 SFO_ActvSta "SFO Status (Active, Inactive)";
CM_ BO_ 745 "[PE] Periodic and On Event";
CM_ SG_ 745 PDC_FD_Crc15Val "PDC_FD_CyclicRedundancyCheck15Value";
CM_ SG_ 745 PDC_FD_AlvCnt15Val "PDC_FD_AliveCounter15Value";
CM_ SG_ 745 PDC_ResetPreWrngForOthers "This is a warning signal for reset.  This signal is used for preparing sideeffect of reset by Receivers";
CM_ SG_ 745 PDC_ResetReqForOthers "This is a request signal for SW reset except for Gateway";
CM_ BO_ 203 "[P] Periodic";
CM_ SG_ 203 ADAS_CMD_Crc35Val "ADAS_CMD_CyclicRedundancyCheck35Value";
CM_ SG_ 203 ADAS_CMD_AlvCnt35Val "ADAS_CMD_AliveCounter35Value";
CM_ SG_ 203 ADAS_ActvACISta "ADAS Active AngleControlInterface State";
CM_ SG_ 203 ADAS_ActvACILvl2Sta "ADAS Active AngleControlInterface Level 2 State";
CM_ SG_ 203 ADAS_StrAnglReqVal "ADAS Steering Angle Request Value";
CM_ SG_ 203 ADAS_ACIAnglTqRedcGainVal "ADAS AngleControlInterface Angle Torque Reduction Gain Value";
CM_ SG_ 203 FCA_ESA_ActvSta "FCA_ESA Active State";
CM_ SG_ 203 FCA_ESA_TqBstGainVal "FCA_ESA Torque Boost Gain Value";
CM_ BO_ 1168 "[PE] Periodic and On Event";
CM_ SG_ 1168 SFA_02_Crc2Val "SFA_02_CyclicRedundancyCheck2Value";
CM_ SG_ 1168 SFA_02_AlvCnt2Val "SFA_02_AliveCounter2Value";
CM_ SG_ 1168 SFA_AlignWarningLamp "SbW Alignment Status";
CM_ BO_ 221 "[P] Periodic";
CM_ SG_ 221 Rack_Command_Diff "SFA Rack command - RWA Rack position";
CM_ SG_ 221 SFA1_RelativeAg "SFA relative Angle";
CM_ SG_ 221 SFA1_MotorTq "SFA motor Torque";
CM_ SG_ 221 SFA1_AbsoluteAg "SFA Absoulte Angle";
CM_ SG_ 221 SFA_Crc1Val "SFA_CyclicRedundancyCheck1Value";
CM_ SG_ 221 SFA_CenteringStatus "SFA Centering ang Alignment Status";
CM_ SG_ 221 SbW_CenteringStatus "Steer by Wire System Centering ang Alignment Status";
CM_ SG_ 221 SFA_IgnitionStatus "SFA IGN Status";
CM_ SG_ 221 SFA_OHP_Status "SFA OHP Status";
CM_ SG_ 221 SFA_SFA1EcuStatus "SFA1 ECU Status (Active, Passive…)";
CM_ SG_ 221 SFA_SFA2EcuStatus "SFA2 ECU Status (Active, Passive…)";
CM_ SG_ 221 SFA_RWA1EcuStatus "RWA1 ECU Status (Active, Passive…)";
CM_ SG_ 221 SFA_RWA2EcuStatus "RWA2 ECU Status (Active, Passive…)";
CM_ SG_ 221 SFA_SteerWheelAngSpd "Steering Wheel Angle Speed Value";
CM_ SG_ 221 SFA_AlvCnt1Val "SFA_AliveCounter1Value";
CM_ SG_ 221 SFA_SteerWheelTorque "SFA Steering Wheel Torque Feedback";
CM_ SG_ 221 SFA_SteerWheelAngle "SFA Steering Wheel Angle Feedback";
CM_ SG_ 221 Reprogram_State_SFA1 "0x0: normal operation 0x1: reprogramming 0x2: reserved 0x3: Error Indicator";
CM_ SG_ 221 SFA1_ResetOpSta "This signal describes reset operation status of SFA1 controller.";
CM_ SG_ 221 SFA_ControlMode "SFA Internal Steering Control Mode (Standby, Normal…)";
CM_ SG_ 221 SFA_EcuRole "SFA ECU Role (Master, Slave)";
CM_ SG_ 221 SFA_WarningLamp "SFA Internal Warning Lamp Flag";
CM_ SG_ 221 SFA_RackCommand "SFA Target Rack Position Command";
CM_ SG_ 221 SFA_FailoverActvSta "SbW Failover Control Request (Active, Inactive)";
CM_ SG_ 221 SFA_BrakeReqActSta "SbW Fail-situation Brake Control Request (Active, Inactive)";
CM_ SG_ 221 SFA_CreepReqActSta "SbW Fail-situation Accel Control Request (Active, Inactive)";
CM_ SG_ 221 SbW_EvDrvRdyEnb "SbW Fail-situaion Shift Control Request (Active, Inactive)";
CM_ SG_ 221 SFA_CluWarningLamp "SbW Warning Lamp Flag";
CM_ SG_ 221 SFA_CluWarningSentence "SbW Warning Sentence";
CM_ BO_ 222 "[P] Periodic";
CM_ SG_ 222 RWA1_RelatIveAg "RWA relatIve Angle";
CM_ SG_ 222 RWA1_MotorTorque "RWA MOTOR TORQUE";
CM_ SG_ 222 RWA1_MotorCur "RWA1_MotorCurrent (MotOutTq*MotAgSpdFild/BattU)";
CM_ SG_ 222 RWA1_AOSAg "RWA AOS Angle (40deg)";
CM_ SG_ 222 RWA_Crc1Val "RWA_CyclicRedundancyCheck1Value";
CM_ SG_ 222 RWA_IgnitionStatus "RWA IGN Status";
CM_ SG_ 222 RWA_OHP_Status "RWA OHP status";
CM_ SG_ 222 RWA_SFA1EcuStatus "SFA1 ECU Status (Active, Passive…)";
CM_ SG_ 222 RWA_SFA2EcuStatus "SFA2 ECU Status (Active, Passive…)";
CM_ SG_ 222 RWA_RWA1EcuStatus "RWA1 ECU Status (Active, Passive…)";
CM_ SG_ 222 RWA_RWA2EcuStatus "RWA2 ECU Status (Active, Passive…)";
CM_ SG_ 222 RWA_CreepReqActSta "SbW Fail-situation Accel Control Request (Active, Inactive)";
CM_ SG_ 222 RWA_PinionAngSpd "RWA Pinion Angle Speed Value";
CM_ SG_ 222 RWA_AlvCnt1Val "RWA_AliveCounter1Value";
CM_ SG_ 222 RWA_RackForce "RWA Rack Force Feedback";
CM_ SG_ 222 RWA_RackPosition "RWA Rack Position Feedback";
CM_ SG_ 222 Reprogram_State_RWA1 "0x0: normal operation 0x1: reprogramming 0x2: reserved 0x3: Error Indicator";
CM_ SG_ 222 RWA1_ResetOpSta "This signal describes reset operation status of RWA1 controller.";
CM_ SG_ 222 RWA_RackSpeed "RWA Rack Speed Feedback";
CM_ SG_ 222 RWA_EcuRole "RWA ECU Role (Master, Slave)";
CM_ SG_ 222 RWA_WarningLamp "RWA Internal Warning Lamp Flag";
CM_ SG_ 222 RWA_ControlMode "RWA Internal Steering Control Mode (Standby, Normal…)";
CM_ SG_ 222 RWA_CenteringStatus "RWA Centering and Alignment Status";
CM_ SG_ 222 RWA_OLP "RWA OLP";
CM_ SG_ 222 RWA_PinionAngle "RWA Pinion Angle";
CM_ BO_ 1669 "[EW] On Event and On Write";
CM_ BO_ 238 "[P] Periodic";
CM_ SG_ 238 RWA2_Crc1Val "RWA2_CyclicRedundancyCheck1Value";
CM_ SG_ 238 RWA_R2_IgnitionStatus "RWA IGN Status";
CM_ SG_ 238 RWA_R2_OHP_Status "RWA OHP status";
CM_ SG_ 238 RWA_R2_SFA1EcuStatus "SFA1 ECU Status (Active, Passive…)";
CM_ SG_ 238 RWA_R2_SFA2EcuStatus "SFA2 ECU Status (Active, Passive…)";
CM_ SG_ 238 RWA_R2_RWA1EcuStatus "RWA1 ECU Status (Active, Passive…)";
CM_ SG_ 238 RWA_R2_RWA2EcuStatus "RWA2 ECU Status (Active, Passive…)";
CM_ SG_ 238 RWA_R2_CreepReqActSta "SbW Fail-situation Accel Control Request (Active, Inactive)";
CM_ SG_ 238 RWA_R2_PinionAngSpd "RWA Pinion Angle Speed Value";
CM_ SG_ 238 RWA2_AlvCnt1Val "RWA2_AliveCounter1Value";
CM_ SG_ 238 RWA_R2_RackForce "RWA Rack Force Feedback";
CM_ SG_ 238 RWA_R2_RackPosition "RWA Rack Position Feedback";
CM_ SG_ 238 RWA_R2_RackSpeed "RWA Rack Speed Feedback";
CM_ SG_ 238 RWA_R2_EcuRole "RWA ECU Role (Master, Slave)";
CM_ SG_ 238 RWA_R2_WarningLamp "RWA Internal Warning Lamp Flag";
CM_ SG_ 238 RWA_R2_ControlMode "RWA Internal Steering Control Mode (Standby, Normal…)";
CM_ SG_ 238 RWA_R2_CenteringStatus "RWA Centering and Alignment Status";
CM_ SG_ 238 RWA_R2_OLP "RWA OLP";
CM_ SG_ 238 RWA_R2_PinionAngle "RWA Pinion Angle";
CM_ BO_ 237 "[P] Periodic";
CM_ SG_ 237 SFA2_Crc1Val "SFA2_CyclicRedundancyCheck1Value";
CM_ SG_ 237 SFA_R2_CenteringStatus "SFA Centering ang Alignment Status";
CM_ SG_ 237 SbW_R2_CenteringStatus "Steer by Wire System Centering ang Alignment Status";
CM_ SG_ 237 SFA_R2_IgnitionStatus "SFA IGN Status";
CM_ SG_ 237 SFA_R2_OHP_Status "SFA OHP Status";
CM_ SG_ 237 SFA_R2_SFA1EcuStatus "SFA1 ECU Status (Active, Passive…)";
CM_ SG_ 237 SFA_R2_SFA2EcuStatus "SFA2 ECU Status (Active, Passive…)";
CM_ SG_ 237 SFA_R2_RWA1EcuStatus "RWA ECU Status (Active, Passive…)";
CM_ SG_ 237 SFA_R2_RWA2EcuStatus "RWA2 ECU Status (Active, Passive…)";
CM_ SG_ 237 SFA_R2_SteerWheelAngSpd "Steering Wheel Angle Speed Value";
CM_ SG_ 237 SFA2_AlvCnt1Val "SFA2_AliveCounter1Value";
CM_ SG_ 237 SFA_R2_SteerWheelTorque "SFA Steering Wheel Torque Feedback";
CM_ SG_ 237 SFA_R2_SteerWheelAngle "SFA Steering Wheel Angle Feedback";
CM_ SG_ 237 SFA_R2_ControlMode "SFA Internal Steering Control Mode (Standby, Normal…)";
CM_ SG_ 237 SFA_R2_EcuRole "SFA ECU Role (Master, Slave)";
CM_ SG_ 237 SFA_R2_WarningLamp "SFA Internal Warning Lamp Flag";
CM_ SG_ 237 SFA_R2_RackCommand "SFA Target Rack Position Command";
CM_ SG_ 237 SFA_R2_FailoverActvSta "SbW Failover Control Request (Active, Inactive)";
CM_ SG_ 237 SFA_R2_BrakeReqActSta "SbW Fail-situation Brake Control Request (Active, Inactive)";
CM_ SG_ 237 SFA_R2_CreepReqActSta "SbW Fail-situation Accel Control Request (Active, Inactive)";
CM_ SG_ 237 SbW_R2_EvDrvRdyEnb "SbW Fail-situaion Shift Control Request (Active, Inactive)";
CM_ SG_ 237 SFA_R2_CluWarningLamp "SbW Warning Lamp Flag";
CM_ SG_ 237 SFA_R2_CluWarningSentence "SbW Warning Sentence";
CM_ BO_ 1671 "[EW] On Event and On Write";
CM_ BO_ 234 "[P] Periodic";
CM_ SG_ 234 MDPS_Crc1Val "MDPS_CyclicRedundancyCheck1Value ##2G##MDPS - MDPS11 - CF_Mdps_Chksum";
CM_ SG_ 234 MDPS_LoamModSta "MDPS_LoamModeStatus ##2G##MDPS - MDPS11 - CF_Mdps_Loam_Flag";
CM_ SG_ 234 MDPS_HDPSpprtSWVer "HDP-MDPS Control Requirement Spec Version";
CM_ SG_ 234 MDPS_ADASAciActvSta "States for angle control";
CM_ SG_ 234 MDPS_ADASAciPluginSta "ADASAci(HDP) function Plug-in state";
CM_ SG_ 234 MDPS_ADAS_AciFltSig "MDPS fault Status for HDP";
CM_ SG_ 234 MDPS_EstStrAnglVal "MDPS_EstStrAnglVal";
CM_ SG_ 234 MDPS_ADASAciActvSta_Lv2 "States for angle control (LV2)";
CM_ SG_ 234 MDPS_ADAS_AciFltSig_Lv2 "MDPS Fault Status for LV2 Angle Control Function";
CM_ SG_ 234 MDPS_TpaPlugInSta "MDPS_TpaPlugInStatus ##2G##MDPS - MDPS11 - CF_Mdps_TPA_FUNC";
CM_ SG_ 234 MDPS_TpaCanfltSta "MDPS_TpaCanFaultStatus ##2G##MDPS - MDPS11 - CF_MDPS_TPACanfailflag";
CM_ SG_ 234 MDPS_TpaModeSta "MDPS_TpaModeStatus ##2G##MDPS - MDPS11 - CF_Mdps_Stat";
CM_ SG_ 234 MDPS_AlvCnt1Val "MDPS_AliveCounter1Value ##2G##MDPS - MDPS11 - CF_Mdps_AliveCnt";
CM_ SG_ 234 MDPS_TpaStrAnglVal "MDPS_TpaSteeringAngleValue ##2G##MDPS - MDPS11 - CR_Mdps_StrAng";
CM_ SG_ 234 MDPS_WrngLmpSta "MDPS_WarningLampStatus ##2G##MDPS - MDPS11 - CF_Mdps_WLmp";
CM_ SG_ 234 MDPS_Typ "MDPS_Type ##2G##MDPS - MDPS11 - CF_Mdps_Type";
CM_ SG_ 234 MDPS_EngIdleRpmReq "MDPS_EngineIdleRpmRequest ##2G##MDPS - MDPS11 - CF_Mdps_ALTRequest";
CM_ SG_ 234 MDPS_VsmPlgInSta "MDPS_VsmPluginStatus ##2G##MDPS - MDPS11 - CF_Mdps_VSM_FUNC";
CM_ SG_ 234 MDPS_VsmDfctvSta "MDPS_VsmDefectiveStatus ##2G##MDPS - MDPS12 - CF_Mdps_Def";
CM_ SG_ 234 MDPS_VsmSigErrSta "MDPS_VsmSignalErrorStatus ##2G##MDPS - MDPS12 - CF_Mdps_SErr";
CM_ SG_ 234 MDPS_PaPlugInSta "MDPS_PaPlugInStatus ##2G##MDPS - MDPS11 - CF_Mdps_PA_FUNC";
CM_ SG_ 234 MDPS_PaModeSta "MDPS_PaModeStatus ##2G##MDPS - MDPS11 - CF_Mdps_Stat";
CM_ SG_ 234 MDPS_PaCanfltSta "MDPS_PaCanFaultStatus ##2G##MDPS - MDPS11 - CF_MDPS_PACanfailflag";
CM_ SG_ 234 MDPS_LkaPlgInSta "MDPS_LkaPlug-inStatus ##2G##MDPS - MDPS11 - CF_Mdps_LKA_FUNC";
CM_ SG_ 234 MDPS_LkaToiActvSta "MDPS_LkaToiActiveStatus ##2G##MDPS - MDPS12 - CF_Mdps_ToiActive";
CM_ SG_ 234 MDPS_LkaToiUnblSta "MDPS_LkaToiUnavailableStatus ##2G##MDPS - MDPS12 - CF_Mdps_ToiUnavail";
CM_ SG_ 234 MDPS_LkaToiFltSta "MDPS_LkaToiFaultStatus ##2G##MDPS - MDPS12 - CF_Mdps_ToiFlt";
CM_ SG_ 234 MDPS_LkaFailSta "MDPS_LkaFailStatus ##2G##MDPS - MDPS12 - CF_Mdps_FailStat";
CM_ SG_ 234 MDPS_ResetOpSta "0x0 Normal 0x1 Reset Complete 0x2 Reset Fail 0x3 Reserved";
CM_ SG_ 234 MDPS_CurrModVal "MDPS_CurrentModeStatus ##2G##MDPS - MDPS11 - CF_Mdps_CurrMode";
CM_ SG_ 234 MDPS_OutTqVal "MDPS_OutputTorqueValue ##2G##MDPS - MDPS12 - CR_Mdps_OutTq";
CM_ SG_ 234 MDPS_VsmActResp "Information of VSM Tqrque Intervention Act Response";
CM_ SG_ 234 Reprogram_State_MDPS "0x0: normal operation 0x1: reprogramming 0x2: reserved 0x3: Error Indicator";
CM_ SG_ 234 MDPS_StrTqSnsrVal "MDPS_SteeringTorqueSensorValue ##2G##MDPS - MDPS11 - CR_Mdps_DrvTq,MDPS12-CR_Mdps_StrTq,CR_Mdps_StrColTq";
CM_ SG_ 234 MDPS_PaStrAnglVal "MDPS_PaSteeringAngleValue ##2G##MDPS - MDPS11 - CR_Mdps_StrAng";
BA_DEF_ BO_  "CANFD_BRS" ENUM  "0","1";
BA_DEF_ BO_  "GenMsgEVName" STRING ;
BA_DEF_ BU_  "NmAsrNodeIdentifier" HEX 0 255;
BA_DEF_ BU_  "NmAsrCanMsgReducedTime" INT 0 1000;
BA_DEF_  "NmAsrWaitBusSleepTime" INT 0 100000;
BA_DEF_  "NmAsrTimeoutTime" INT 0 100000;
BA_DEF_  "NmAsrRepeatMessageTime" INT 0 100000;
BA_DEF_  "NmAsrMessageCount" INT 0 255;
BA_DEF_  "NmAsrCanMsgCycleTime" INT 0 100;
BA_DEF_  "NmAsrBaseAddress" HEX 0 536870911;
BA_DEF_ BO_  "NmAsrMessage" ENUM  "No","Yes";
BA_DEF_ BO_  "DiagState" ENUM  "No","Yes";
BA_DEF_ BO_  "DiagResponse" ENUM  "No","Yes";
BA_DEF_ BO_  "DiagRequest" ENUM  "No","Yes";
BA_DEF_ BO_  "TpMessage" ENUM  "No","Yes";
BA_DEF_ BO_  "UsrMsgIDSforwardDeviation" INT 0 100;
BA_DEF_ BO_  "UsrMsgIDSbackwardDeviation" INT 50 1000;
BA_DEF_  "BusType" STRING ;
BA_DEF_  "DBName" STRING ;
BA_DEF_  "Baudrate" INT 50000 1000000;
BA_DEF_  "BRS" INT 0 1;
BA_DEF_  "GenEnvVarEndingDsp" STRING ;
BA_DEF_  "GenEnvVarEndingSnd" STRING ;
BA_DEF_  "GenEnvVarPrefix" STRING ;
BA_DEF_  "GenNWMApBusSleep" STRING ;
BA_DEF_  "GenNWMApCanNormal" STRING ;
BA_DEF_  "GenNWMApCanOff" STRING ;
BA_DEF_  "GenNWMApCanOn" STRING ;
BA_DEF_  "GenNWMApCanSleep" STRING ;
BA_DEF_  "GenNWMApCanWakeUp" STRING ;
BA_DEF_  "GenNWMGotoMode_Awake" STRING ;
BA_DEF_  "GenNWMGotoMode_BusSleep" STRING ;
BA_DEF_  "GenNWMSleepTime" INT 1375 1650;
BA_DEF_  "GenNWMTalkNM" STRING ;
BA_DEF_  "Manufacturer" STRING ;
BA_DEF_  "NmBaseAddress" HEX 0 2047;
BA_DEF_  "NmMessageCount" INT 0 128;
BA_DEF_  "NmType" STRING ;
BA_DEF_  "SamplePointMax" INT 50 85;
BA_DEF_  "SamplePointMin" INT 55 85;
BA_DEF_  "SyncJumpWidthMax" INT 1 8;
BA_DEF_  "SyncJumpWidthMin" INT 1 4;
BA_DEF_  "VersionDay" INT 1 31;
BA_DEF_  "VersionMonth" INT 1 12;
BA_DEF_  "VersionNumber" INT 0 999999;
BA_DEF_  "VersionNumberInternal" INT 0 9999;
BA_DEF_  "VersionWeek" INT 1 53;
BA_DEF_  "VersionYear" INT 0 9999;
BA_DEF_ BU_  "NmStationAddress" HEX 0 127;
BA_DEF_ BU_  "NmNode" ENUM  "No","Yes";
BA_DEF_ BU_  "GenNodSleepTime" INT 1375 1650;
BA_DEF_ BU_  "ILUsed" ENUM  "No","Yes";
BA_DEF_ BU_  "NmCAN" INT 1 2;
BA_DEF_ BU_  "NodeLayerModules" STRING ;
BA_DEF_ BU_  "NWM_Knoten" ENUM  "No","Yes";
BA_DEF_ BO_  "GenMsgCycleTime" INT 0 2000;
BA_DEF_ BO_  "GenMsgStartDelayTime" INT 0 2000;
BA_DEF_ BO_  "GenMsgSendType" ENUM  "Cyclic","NoMsgSendType";
BA_DEF_ BO_  "GenMsgCycleTimeFast" INT 0 500;
BA_DEF_ BO_  "GenMsgDelayTime" INT 0 20;
BA_DEF_ BO_  "GenMsgILSupport" ENUM  "No","Yes";
BA_DEF_ BO_  "GenMsgNrOfRepetition" INT 0 3;
BA_DEF_ BO_  "TpTxIndex" INT 0 65535;
BA_DEF_ BO_  "VFrameFormat" ENUM  "StandardCAN","ExtendedCAN","reserved","reserved","reserved","reserved","reserved","reserved","reserved","reserved","reserved","reserved","reserved","reserved","StandardCAN_FD","ExtendedCAN_FD";
BA_DEF_ SG_  "UserSigValidity" ENUM  "B+","ACC","IG","IG1","IG2","IG3","IG1 or IG2","IG1 or IG3","Undef";
BA_DEF_ SG_  "UsrSigPurpose" ENUM  "Undef","FN","DIAG","DIAG(Req)","DIAG(Res)","DIAG(Func)","DEV","CCP","NM","TP";
BA_DEF_ SG_  "GenSigStartValue" INT 0 1215752192;
BA_DEF_ SG_  "NetworkRequest" ENUM  "Yes","No";
BA_DEF_ SG_  "NetworkRequestHoldingTime" INT 0 65535;
BA_DEF_ SG_  "Description" STRING ;
BA_DEF_ SG_  "Version" STRING ;
BA_DEF_ SG_  "GenSigEnvVarType" ENUM  "Int","Float","Undef";
BA_DEF_ SG_  "GenSigSendType" ENUM  "Cyclic","OnWrite","OnWriteWithRepetition","OnChange","OnChangeWithRepetition","IfActive","IfActiveWithRepetition","NoSigSendType","OnChangeAndIfActive","OnChangeAndIfActiveWithRepetition";
BA_DEF_ SG_  "GwSigLatencyTime" INT 0 65536;
BA_DEF_ SG_  "GwSigMissingSourceType" ENUM  "Undef","OldValue","DefaultValue","InitialValue";
BA_DEF_ SG_  "NWM-WakeupAllowed" ENUM  "<n.a.>";
BA_DEF_ SG_  "RoutingFactor" INT 1 1215752192;
BA_DEF_  "Datarate" INT 2000000 8000000;
BA_DEF_REL_ BU_SG_REL_  "GenSigTimeoutTime" INT 0 7000;
BA_DEF_DEF_  "CANFD_BRS" "1";
BA_DEF_DEF_  "GenMsgEVName" "@Signame";
BA_DEF_DEF_  "NmAsrNodeIdentifier" 0;
BA_DEF_DEF_  "NmAsrCanMsgReducedTime" 1000;
BA_DEF_DEF_  "NmAsrWaitBusSleepTime" 1500;
BA_DEF_DEF_  "NmAsrTimeoutTime" 1000;
BA_DEF_DEF_  "NmAsrRepeatMessageTime" 1200;
BA_DEF_DEF_  "NmAsrMessageCount" 255;
BA_DEF_DEF_  "NmAsrCanMsgCycleTime" 100;
BA_DEF_DEF_  "NmAsrBaseAddress" 402391040;
BA_DEF_DEF_  "NmAsrMessage" "No";
BA_DEF_DEF_  "DiagState" "No";
BA_DEF_DEF_  "DiagResponse" "No";
BA_DEF_DEF_  "DiagRequest" "No";
BA_DEF_DEF_  "TpMessage" "No";
BA_DEF_DEF_  "UsrMsgIDSforwardDeviation" 10;
BA_DEF_DEF_  "UsrMsgIDSbackwardDeviation" 100;
BA_DEF_DEF_  "BusType" "CAN FD";
BA_DEF_DEF_  "DBName" "";
BA_DEF_DEF_  "Baudrate" 500000;
BA_DEF_DEF_  "BRS" 1;
BA_DEF_DEF_  "GenEnvVarEndingDsp" "Dsp_";
BA_DEF_DEF_  "GenEnvVarEndingSnd" "_";
BA_DEF_DEF_  "GenEnvVarPrefix" "Env";
BA_DEF_DEF_  "GenNWMApBusSleep" "AppNmCanBusSleep()";
BA_DEF_DEF_  "GenNWMApCanNormal" "AppNmCanNormal()";
BA_DEF_DEF_  "GenNWMApCanOff" "ApplCanOffline()";
BA_DEF_DEF_  "GenNWMApCanOn" "ApplCanOnline()";
BA_DEF_DEF_  "GenNWMApCanSleep" "ApplNmCanSleep()";
BA_DEF_DEF_  "GenNWMApCanWakeUp" "ApplCanWakeUp()";
BA_DEF_DEF_  "GenNWMGotoMode_Awake" "GotoMode_Awake()";
BA_DEF_DEF_  "GenNWMGotoMode_BusSleep" "GotoMode_BusSleep()";
BA_DEF_DEF_  "GenNWMSleepTime" 1500;
BA_DEF_DEF_  "GenNWMTalkNM" "TalkNM()";
BA_DEF_DEF_  "Manufacturer" "HMC";
BA_DEF_DEF_  "NmBaseAddress" 1280;
BA_DEF_DEF_  "NmMessageCount" 128;
BA_DEF_DEF_  "NmType" "AsrNm";
BA_DEF_DEF_  "SamplePointMax" 80;
BA_DEF_DEF_  "SamplePointMin" 80;
BA_DEF_DEF_  "SyncJumpWidthMax" 3;
BA_DEF_DEF_  "SyncJumpWidthMin" 2;
BA_DEF_DEF_  "VersionDay" 1;
BA_DEF_DEF_  "VersionMonth" 1;
BA_DEF_DEF_  "VersionNumber" 0;
BA_DEF_DEF_  "VersionNumberInternal" 0;
BA_DEF_DEF_  "VersionWeek" 1;
BA_DEF_DEF_  "VersionYear" 0;
BA_DEF_DEF_  "NmStationAddress" 0;
BA_DEF_DEF_  "NmNode" "No";
BA_DEF_DEF_  "GenNodSleepTime" 1500;
BA_DEF_DEF_  "ILUsed" "Yes";
BA_DEF_DEF_  "NmCAN" 1;
BA_DEF_DEF_  "NodeLayerModules" "AsrNM33.DLL,CANoeILNLVector.DLL";
BA_DEF_DEF_  "NWM_Knoten" "Yes";
BA_DEF_DEF_  "GenMsgCycleTime" 200;
BA_DEF_DEF_  "GenMsgStartDelayTime" 0;
BA_DEF_DEF_  "GenMsgSendType" "NoMsgSendType";
BA_DEF_DEF_  "GenMsgCycleTimeFast" 40;
BA_DEF_DEF_  "GenMsgDelayTime" 20;
BA_DEF_DEF_  "GenMsgILSupport" "Yes";
BA_DEF_DEF_  "GenMsgNrOfRepetition" 3;
BA_DEF_DEF_  "TpTxIndex" 0;
BA_DEF_DEF_  "VFrameFormat" "StandardCAN";
BA_DEF_DEF_  "UserSigValidity" "IG";
BA_DEF_DEF_  "UsrSigPurpose" "FN";
BA_DEF_DEF_  "GenSigStartValue" 0;
BA_DEF_DEF_  "NetworkRequest" "No";
BA_DEF_DEF_  "NetworkRequestHoldingTime" 0;
BA_DEF_DEF_  "Description" "";
BA_DEF_DEF_  "Version" "";
BA_DEF_DEF_  "GenSigEnvVarType" "Undef";
BA_DEF_DEF_  "GenSigSendType" "NoSigSendType";
BA_DEF_DEF_  "GwSigLatencyTime" 40;
BA_DEF_DEF_  "GwSigMissingSourceType" "Undef";
BA_DEF_DEF_  "NWM-WakeupAllowed" "<n.a.>";
BA_DEF_DEF_  "RoutingFactor" 1;
BA_DEF_DEF_  "Datarate" 2000000;
BA_DEF_DEF_REL_ "GenSigTimeoutTime" 500;
BA_ "VersionYear" 1;
BA_ "VersionNumber" 240501;
BA_ "DBName" "FD_C";
BA_ "NmStationAddress" BU_ ECS 119;
BA_ "NmNode" BU_ ECS 1;
BA_ "NmAsrNodeIdentifier" BU_ ECS 119;
BA_ "NmStationAddress" BU_ RCU 81;
BA_ "NmNode" BU_ RCU 1;
BA_ "NmAsrNodeIdentifier" BU_ RCU 81;
BA_ "NmStationAddress" BU_ ESC 117;
BA_ "NmNode" BU_ ESC 1;
BA_ "NmAsrNodeIdentifier" BU_ ESC 117;
BA_ "NmStationAddress" BU_ RWS 121;
BA_ "NmNode" BU_ RWS 1;
BA_ "NmAsrNodeIdentifier" BU_ RWS 121;
BA_ "NmStationAddress" BU_ GW_RGW 63;
BA_ "NmNode" BU_ GW_RGW 1;
BA_ "NmAsrNodeIdentifier" BU_ GW_RGW 63;
BA_ "NmStationAddress" BU_ EBB 98;
BA_ "NmNode" BU_ EBB 1;
BA_ "NmAsrNodeIdentifier" BU_ EBB 98;
BA_ "NmStationAddress" BU_ CGW_CCU 112;
BA_ "NmNode" BU_ CGW_CCU 1;
BA_ "NmAsrNodeIdentifier" BU_ CGW_CCU 112;
BA_ "NmStationAddress" BU_ MDPS 118;
BA_ "NmNode" BU_ MDPS 1;
BA_ "NmAsrNodeIdentifier" BU_ MDPS 118;
BA_ "NmStationAddress" BU_ RWA 74;
BA_ "NmNode" BU_ RWA 1;
BA_ "NmAsrNodeIdentifier" BU_ RWA 74;
BA_ "NmStationAddress" BU_ SFA 58;
BA_ "NmNode" BU_ SFA 1;
BA_ "NmAsrNodeIdentifier" BU_ SFA 58;
BA_ "GenMsgCycleTime" BO_ 2683321087 300;
BA_ "VFrameFormat" BO_ 2683321087 15;
BA_ "GenMsgCycleTime" BO_ 2683325183 300;
BA_ "VFrameFormat" BO_ 2683325183 15;
BA_ "GenMsgCycleTime" BO_ 0 0;
BA_ "GenMsgSendType" BO_ 548 0;
BA_ "GenMsgCycleTimeFast" BO_ 548 0;
BA_ "GenMsgNrOfRepetition" BO_ 548 0;
BA_ "VFrameFormat" BO_ 548 14;
BA_ "GenMsgSendType" BO_ 549 0;
BA_ "GenMsgCycleTime" BO_ 549 100;
BA_ "GenMsgCycleTimeFast" BO_ 549 0;
BA_ "GenMsgNrOfRepetition" BO_ 549 0;
BA_ "VFrameFormat" BO_ 549 14;
BA_ "GenMsgSendType" BO_ 517 0;
BA_ "GenMsgCycleTime" BO_ 517 100;
BA_ "GenMsgCycleTimeFast" BO_ 517 0;
BA_ "GenMsgNrOfRepetition" BO_ 517 0;
BA_ "VFrameFormat" BO_ 517 14;
BA_ "GenMsgSendType" BO_ 520 0;
BA_ "GenMsgCycleTimeFast" BO_ 520 0;
BA_ "GenMsgNrOfRepetition" BO_ 520 0;
BA_ "VFrameFormat" BO_ 520 14;
BA_ "GenMsgSendType" BO_ 53 0;
BA_ "GenMsgCycleTime" BO_ 53 20;
BA_ "GenMsgCycleTimeFast" BO_ 53 0;
BA_ "GenMsgNrOfRepetition" BO_ 53 0;
BA_ "GenMsgDelayTime" BO_ 53 0;
BA_ "VFrameFormat" BO_ 53 14;
BA_ "GenMsgSendType" BO_ 64 0;
BA_ "GenMsgCycleTime" BO_ 64 20;
BA_ "GenMsgCycleTimeFast" BO_ 64 0;
BA_ "GenMsgNrOfRepetition" BO_ 64 0;
BA_ "GenMsgDelayTime" BO_ 64 0;
BA_ "VFrameFormat" BO_ 64 14;
BA_ "GenMsgSendType" BO_ 74 0;
BA_ "GenMsgCycleTime" BO_ 74 10;
BA_ "GenMsgCycleTimeFast" BO_ 74 0;
BA_ "GenMsgNrOfRepetition" BO_ 74 0;
BA_ "GenMsgDelayTime" BO_ 74 0;
BA_ "VFrameFormat" BO_ 74 14;
BA_ "GenMsgSendType" BO_ 101 0;
BA_ "GenMsgCycleTime" BO_ 101 10;
BA_ "GenMsgCycleTimeFast" BO_ 101 0;
BA_ "GenMsgNrOfRepetition" BO_ 101 0;
BA_ "GenMsgDelayTime" BO_ 101 0;
BA_ "VFrameFormat" BO_ 101 14;
BA_ "GenMsgSendType" BO_ 96 0;
BA_ "GenMsgCycleTime" BO_ 96 10;
BA_ "GenMsgCycleTimeFast" BO_ 96 0;
BA_ "GenMsgNrOfRepetition" BO_ 96 0;
BA_ "GenMsgDelayTime" BO_ 96 0;
BA_ "VFrameFormat" BO_ 96 14;
BA_ "GenMsgSendType" BO_ 111 0;
BA_ "GenMsgCycleTime" BO_ 111 10;
BA_ "GenMsgCycleTimeFast" BO_ 111 0;
BA_ "GenMsgNrOfRepetition" BO_ 111 0;
BA_ "GenMsgDelayTime" BO_ 111 0;
BA_ "VFrameFormat" BO_ 111 14;
BA_ "GenMsgSendType" BO_ 597 0;
BA_ "GenMsgCycleTimeFast" BO_ 597 0;
BA_ "GenMsgNrOfRepetition" BO_ 597 0;
BA_ "VFrameFormat" BO_ 597 14;
BA_ "GenMsgSendType" BO_ 647 0;
BA_ "VFrameFormat" BO_ 647 14;
BA_ "GenMsgSendType" BO_ 160 0;
BA_ "GenMsgCycleTime" BO_ 160 10;
BA_ "GenMsgCycleTimeFast" BO_ 160 0;
BA_ "GenMsgNrOfRepetition" BO_ 160 0;
BA_ "GenMsgDelayTime" BO_ 160 0;
BA_ "VFrameFormat" BO_ 160 14;
BA_ "GenMsgSendType" BO_ 176 0;
BA_ "GenMsgCycleTime" BO_ 176 10;
BA_ "GenMsgCycleTimeFast" BO_ 176 0;
BA_ "GenMsgNrOfRepetition" BO_ 176 0;
BA_ "GenMsgDelayTime" BO_ 176 0;
BA_ "VFrameFormat" BO_ 176 14;
BA_ "GenMsgSendType" BO_ 745 0;
BA_ "GenMsgCycleTime" BO_ 745 300;
BA_ "VFrameFormat" BO_ 745 14;
BA_ "GenMsgSendType" BO_ 203 0;
BA_ "GenMsgCycleTime" BO_ 203 10;
BA_ "GenMsgCycleTimeFast" BO_ 203 0;
BA_ "GenMsgNrOfRepetition" BO_ 203 0;
BA_ "GenMsgDelayTime" BO_ 203 0;
BA_ "VFrameFormat" BO_ 203 14;
BA_ "GenMsgSendType" BO_ 1168 0;
BA_ "GenMsgCycleTime" BO_ 1168 500;
BA_ "VFrameFormat" BO_ 1168 14;
BA_ "GenMsgSendType" BO_ 221 0;
BA_ "GenMsgCycleTime" BO_ 221 10;
BA_ "GenMsgCycleTimeFast" BO_ 221 0;
BA_ "GenMsgNrOfRepetition" BO_ 221 0;
BA_ "GenMsgDelayTime" BO_ 221 0;
BA_ "VFrameFormat" BO_ 221 14;
BA_ "GenMsgSendType" BO_ 222 0;
BA_ "GenMsgCycleTime" BO_ 222 10;
BA_ "GenMsgCycleTimeFast" BO_ 222 0;
BA_ "GenMsgNrOfRepetition" BO_ 222 0;
BA_ "GenMsgDelayTime" BO_ 222 0;
BA_ "VFrameFormat" BO_ 222 14;
BA_ "GenMsgCycleTime" BO_ 1669 0;
BA_ "GenMsgILSupport" BO_ 1669 0;
BA_ "TpMessage" BO_ 1669 1;
BA_ "GenMsgNrOfRepetition" BO_ 1669 0;
BA_ "GenMsgDelayTime" BO_ 1669 10;
BA_ "VFrameFormat" BO_ 1669 14;
BA_ "GenMsgSendType" BO_ 238 0;
BA_ "GenMsgCycleTime" BO_ 238 10;
BA_ "GenMsgCycleTimeFast" BO_ 238 0;
BA_ "GenMsgNrOfRepetition" BO_ 238 0;
BA_ "GenMsgDelayTime" BO_ 238 0;
BA_ "VFrameFormat" BO_ 238 14;
BA_ "GenMsgSendType" BO_ 237 0;
BA_ "GenMsgCycleTime" BO_ 237 10;
BA_ "GenMsgCycleTimeFast" BO_ 237 0;
BA_ "GenMsgNrOfRepetition" BO_ 237 0;
BA_ "GenMsgDelayTime" BO_ 237 0;
BA_ "VFrameFormat" BO_ 237 14;
BA_ "GenMsgCycleTime" BO_ 1671 0;
BA_ "GenMsgILSupport" BO_ 1671 0;
BA_ "TpMessage" BO_ 1671 1;
BA_ "GenMsgNrOfRepetition" BO_ 1671 0;
BA_ "GenMsgDelayTime" BO_ 1671 10;
BA_ "VFrameFormat" BO_ 1671 14;
BA_ "GenMsgSendType" BO_ 234 0;
BA_ "GenMsgCycleTime" BO_ 234 10;
BA_ "GenMsgCycleTimeFast" BO_ 234 0;
BA_ "GenMsgNrOfRepetition" BO_ 234 0;
BA_ "GenMsgDelayTime" BO_ 234 0;
BA_ "VFrameFormat" BO_ 234 14;
BA_ "GenSigStartValue" SG_ 2683321087 SFA1_Yawrate 32768;
BA_ "GenSigStartValue" SG_ 2683321087 SFA1_LatG 32768;
BA_ "GenSigSendType" SG_ 0 WakeUp_DoorLock_DrvDrUnLkSta 4;
BA_ "GenSigStartValue" SG_ 0 WakeUp_DoorLock_DrvDrUnLkSta 2;
BA_ "UserSigValidity" SG_ 0 WakeUp_DoorLock_DrvDrUnLkSta 0;
BA_ "NetworkRequest" SG_ 0 WakeUp_DoorLock_DrvDrUnLkSta 0;
BA_ "NetworkRequestHoldingTime" SG_ 0 WakeUp_DoorLock_DrvDrUnLkSta 5000;
BA_ "Version" SG_ 0 WakeUp_DoorLock_DrvDrUnLkSta "22.03.04";
BA_ "GenSigSendType" SG_ 0 WakeUp_DoorLock_AsstDrUnLkSta 4;
BA_ "GenSigStartValue" SG_ 0 WakeUp_DoorLock_AsstDrUnLkSta 2;
BA_ "UserSigValidity" SG_ 0 WakeUp_DoorLock_AsstDrUnLkSta 0;
BA_ "NetworkRequest" SG_ 0 WakeUp_DoorLock_AsstDrUnLkSta 0;
BA_ "NetworkRequestHoldingTime" SG_ 0 WakeUp_DoorLock_AsstDrUnLkSta 5000;
BA_ "Version" SG_ 0 WakeUp_DoorLock_AsstDrUnLkSta "22.03.04";
BA_ "GenSigSendType" SG_ 0 WakeUp_Warn_AsstDrSwSta 4;
BA_ "GenSigStartValue" SG_ 0 WakeUp_Warn_AsstDrSwSta 2;
BA_ "UserSigValidity" SG_ 0 WakeUp_Warn_AsstDrSwSta 0;
BA_ "NetworkRequest" SG_ 0 WakeUp_Warn_AsstDrSwSta 0;
BA_ "NetworkRequestHoldingTime" SG_ 0 WakeUp_Warn_AsstDrSwSta 5000;
BA_ "Version" SG_ 0 WakeUp_Warn_AsstDrSwSta "22.03.04";
BA_ "GenSigSendType" SG_ 0 WakeUp_Warn_DrvDrSwSta 4;
BA_ "GenSigStartValue" SG_ 0 WakeUp_Warn_DrvDrSwSta 2;
BA_ "UserSigValidity" SG_ 0 WakeUp_Warn_DrvDrSwSta 0;
BA_ "NetworkRequest" SG_ 0 WakeUp_Warn_DrvDrSwSta 0;
BA_ "NetworkRequestHoldingTime" SG_ 0 WakeUp_Warn_DrvDrSwSta 5000;
BA_ "Version" SG_ 0 WakeUp_Warn_DrvDrSwSta "22.03.04";
BA_ "Description" SG_ 548 ALDC_Crc1Val "The data area for CRC calculation is based on the data length (DLC) of the message DB.

The CRC shall be calculated over the entire data block (excluding the CRC bytes) including the user data, alive counter and Data ID



- CRC Polynomial (0x1021) , Ini";
BA_ "GenSigStartValue" SG_ 548 ALDC_Crc1Val 65535;
BA_ "UserSigValidity" SG_ 548 ALDC_Crc1Val 3;
BA_ "RoutingFactor" SG_ 548 ALDC_Crc1Val 2;
BA_ "Version" SG_ 548 ALDC_Crc1Val "21.09.03";
BA_ "Description" SG_ 548 ALDC_AlvCnt1Val "For the first transmission request for a data element the counter shall be initialized with 0 and shall be incremented by 1 for every subsequent send request. 

When the counter reaches the maximum value(0xFF), then it shall restart with 0 for the next s";
BA_ "UserSigValidity" SG_ 548 ALDC_AlvCnt1Val 3;
BA_ "RoutingFactor" SG_ 548 ALDC_AlvCnt1Val 2;
BA_ "Version" SG_ 548 ALDC_AlvCnt1Val "21.09.03";
BA_ "Description" SG_ 548 ALDC_SysOpSta "ALDC operating status";
BA_ "UserSigValidity" SG_ 548 ALDC_SysOpSta 7;
BA_ "RoutingFactor" SG_ 548 ALDC_SysOpSta 2;
BA_ "Version" SG_ 548 ALDC_SysOpSta "21.05.05";
BA_ "Description" SG_ 548 ALDC_SysFltSta "ALDC Fault status";
BA_ "UserSigValidity" SG_ 548 ALDC_SysFltSta 7;
BA_ "RoutingFactor" SG_ 548 ALDC_SysFltSta 2;
BA_ "Version" SG_ 548 ALDC_SysFltSta "21.05.05";
BA_ "Description" SG_ 549 CLU_Crc2Val "The data area for CRC calculation is based on the data length (DLC) of the message DB.

The CRC shall be calculated over the entire data block (excluding the CRC bytes) including the user data, alive counter and Data ID



- CRC Polynomial (0x1021) , Ini";
BA_ "GenSigStartValue" SG_ 549 CLU_Crc2Val 65535;
BA_ "UserSigValidity" SG_ 549 CLU_Crc2Val 3;
BA_ "RoutingFactor" SG_ 549 CLU_Crc2Val 2;
BA_ "Version" SG_ 549 CLU_Crc2Val "21.09.03";
BA_ "Description" SG_ 549 CLU_DrvngModSwSta "This signal occurs when drive mode switch is selected either 'Normal' or 'Eco' or 'Sport' or 'Sport+' or 'Smart' or 'Custom' or 'N-mode'.";
BA_ "UserSigValidity" SG_ 549 CLU_DrvngModSwSta 3;
BA_ "RoutingFactor" SG_ 549 CLU_DrvngModSwSta 2;
BA_ "Version" SG_ 549 CLU_DrvngModSwSta "20.04.02";
BA_ "Description" SG_ 549 CLU_AlvCnt2Val "For the first transmission request for a data element the counter shall be initialized with 0 and shall be incremented by 1 for every subsequent send request. 

When the counter reaches the maximum value(0xFF), then it shall restart with 0 for the next s";
BA_ "UserSigValidity" SG_ 549 CLU_AlvCnt2Val 3;
BA_ "RoutingFactor" SG_ 549 CLU_AlvCnt2Val 2;
BA_ "Version" SG_ 549 CLU_AlvCnt2Val "21.09.03";
BA_ "Description" SG_ 517 ICSC_Crc2Val "The data area for CRC calculation is based on the data length (DLC) of the message DB.

The CRC shall be calculated over the entire data block (excluding the CRC bytes) including the user data, alive counter and Data ID



- CRC Polynomial (0x1021) , Ini";
BA_ "GenSigStartValue" SG_ 517 ICSC_Crc2Val 65535;
BA_ "UserSigValidity" SG_ 517 ICSC_Crc2Val 3;
BA_ "RoutingFactor" SG_ 517 ICSC_Crc2Val 2;
BA_ "Version" SG_ 517 ICSC_Crc2Val "21.09.03";
BA_ "Description" SG_ 517 ICSC_AlvCnt2Val "For the first transmission request for a data element the counter shall be initialized with 0 and shall be incremented by 1 for every subsequent send request. 

When the counter reaches the maximum value(0xFF), then it shall restart with 0 for the next s";
BA_ "UserSigValidity" SG_ 517 ICSC_AlvCnt2Val 3;
BA_ "RoutingFactor" SG_ 517 ICSC_AlvCnt2Val 2;
BA_ "Version" SG_ 517 ICSC_AlvCnt2Val "21.09.03";
BA_ "Description" SG_ 517 DMIC_MdpsModSta "This Signal is the request on mode transition for Controlling the Driving Mode.";
BA_ "UserSigValidity" SG_ 517 DMIC_MdpsModSta 3;
BA_ "RoutingFactor" SG_ 517 DMIC_MdpsModSta 2;
BA_ "Version" SG_ 517 DMIC_MdpsModSta "22.01.06";
BA_ "Description" SG_ 520 HOD_FD_Crc1Val "The data area for CRC calculation is based on the data length (DLC) of the message DB.

The CRC shall be calculated over the entire data block (excluding the CRC bytes) including the user data, alive counter and Data ID



- CRC Polynomial (0x1021) , Ini";
BA_ "GenSigStartValue" SG_ 520 HOD_FD_Crc1Val 65535;
BA_ "UserSigValidity" SG_ 520 HOD_FD_Crc1Val 3;
BA_ "Version" SG_ 520 HOD_FD_Crc1Val "22.10.20";
BA_ "Description" SG_ 520 HOD_FD_AlvCnt1Val "For the first transmission request for a data element the counter shall be initialized with 0 and shall be incremented by 1 for every subsequent send request. 

When the counter reaches the maximum value(0xFF), then it shall restart with 0 for the next s";
BA_ "UserSigValidity" SG_ 520 HOD_FD_AlvCnt1Val 3;
BA_ "Version" SG_ 520 HOD_FD_AlvCnt1Val "22.10.20";
BA_ "Description" SG_ 520 HOD_Dir_Status "This signal indicates the status of hands on/off";
BA_ "GenSigStartValue" SG_ 520 HOD_Dir_Status 7;
BA_ "UserSigValidity" SG_ 520 HOD_Dir_Status 0;
BA_ "Version" SG_ 520 HOD_Dir_Status "21.07.05";
BA_ "Description" SG_ 520 HOD_Option "This signal is a checkable signal that the HOD is applied.

This signal should be fixed 0x1.";
BA_ "UserSigValidity" SG_ 520 HOD_Option 0;
BA_ "Version" SG_ 520 HOD_Option "21.07.05";
BA_ "Description" SG_ 53 VCU_Crc1Val "The data area for CRC calculation is based on the data length (DLC) of the message DB.

The CRC shall be calculated over the entire data block (excluding the CRC bytes) including the user data, alive counter and Data ID



- CRC Polynomial (0x1021) , Ini";
BA_ "GenSigStartValue" SG_ 53 VCU_Crc1Val 65535;
BA_ "UserSigValidity" SG_ 53 VCU_Crc1Val 7;
BA_ "RoutingFactor" SG_ 53 VCU_Crc1Val 5;
BA_ "Version" SG_ 53 VCU_Crc1Val "21.09.03";
BA_ "Description" SG_ 53 VCU_AlvCnt1Val "For the first transmission request for a data element the counter shall be initialized with 0 and shall be incremented by 1 for every subsequent send request. 

When the counter reaches the maximum value(0xFF), then it shall restart with 0 for the next s";
BA_ "UserSigValidity" SG_ 53 VCU_AlvCnt1Val 7;
BA_ "RoutingFactor" SG_ 53 VCU_AlvCnt1Val 5;
BA_ "Version" SG_ 53 VCU_AlvCnt1Val "21.09.03";
BA_ "Description" SG_ 53 VCU_EvDrvRdySta "EV Ready";
BA_ "UserSigValidity" SG_ 53 VCU_EvDrvRdySta 7;
BA_ "RoutingFactor" SG_ 53 VCU_EvDrvRdySta 5;
BA_ "Version" SG_ 53 VCU_EvDrvRdySta "20.04.05";
BA_ "Description" SG_ 53 VCU_GearPosSta "Gear Position Status";
BA_ "GenSigStartValue" SG_ 53 VCU_GearPosSta 9;
BA_ "UserSigValidity" SG_ 53 VCU_GearPosSta 7;
BA_ "RoutingFactor" SG_ 53 VCU_GearPosSta 5;
BA_ "Version" SG_ 53 VCU_GearPosSta "21.05.01";
BA_ "Description" SG_ 53 VCU_AccPedDepVal "Accelerator Pedal Depth Value";
BA_ "UserSigValidity" SG_ 53 VCU_AccPedDepVal 7;
BA_ "RoutingFactor" SG_ 53 VCU_AccPedDepVal 5;
BA_ "Version" SG_ 53 VCU_AccPedDepVal "20.04.05";
BA_ "Description" SG_ 64 TCU_Crc1Val "The data area for CRC calculation is based on the data length (DLC) of the message DB.

The CRC shall be calculated over the entire data block (excluding the CRC bytes) including the user data, alive counter and Data ID

 

- CRC Polynomial (0x1021) , In";
BA_ "GenSigStartValue" SG_ 64 TCU_Crc1Val 65535;
BA_ "UserSigValidity" SG_ 64 TCU_Crc1Val 3;
BA_ "RoutingFactor" SG_ 64 TCU_Crc1Val 5;
BA_ "Version" SG_ 64 TCU_Crc1Val "18.11.08";
BA_ "Description" SG_ 64 TCU_AlvCnt1Val "For the first transmission request for a data element the counter shall be initialized with 0 and shall be incremented by 1 for every subsequent send request. 

When the counter reaches the maximum value(0xFF), then it shall restart with 0 for the next s";
BA_ "UserSigValidity" SG_ 64 TCU_AlvCnt1Val 3;
BA_ "RoutingFactor" SG_ 64 TCU_AlvCnt1Val 5;
BA_ "Version" SG_ 64 TCU_AlvCnt1Val "18.11.08";
BA_ "Description" SG_ 64 TCU_CurrGearSta "CUR_GR indicates the gear speed which is currently engaged in the gearbox.";
BA_ "UserSigValidity" SG_ 64 TCU_CurrGearSta 3;
BA_ "RoutingFactor" SG_ 64 TCU_CurrGearSta 5;
BA_ "Version" SG_ 64 TCU_CurrGearSta "17.11.00";
BA_ "Description" SG_ 74 IMU_Crc1Val "The data area for CRC calculation is based on the data length (DLC) of the message DB.

The CRC shall be calculated over the entire data block (excluding the CRC bytes) including the user data, alive counter and Data ID



- CRC Polynomial (0x1021) , Ini";
BA_ "GenSigStartValue" SG_ 74 IMU_Crc1Val 65535;
BA_ "UserSigValidity" SG_ 74 IMU_Crc1Val 3;
BA_ "RoutingFactor" SG_ 74 IMU_Crc1Val 5;
BA_ "Version" SG_ 74 IMU_Crc1Val "21.09.03";
BA_ "Description" SG_ 74 IMU_AlvCnt1Val "For the first transmission request for a data element the counter shall be initialized with 0 and shall be incremented by 1 for every subsequent send request. 

When the counter reaches the maximum value(0xFF), then it shall restart with 0 for the next s";
BA_ "UserSigValidity" SG_ 74 IMU_AlvCnt1Val 3;
BA_ "RoutingFactor" SG_ 74 IMU_AlvCnt1Val 5;
BA_ "Version" SG_ 74 IMU_AlvCnt1Val "21.09.03";
BA_ "Description" SG_ 74 IMU_YawSigSta "This signal indicates failure status of yaw rate signal and yaw rate sensing element.



0000B : No failure 



xxx1B : IMU_Yawrate_failure



xx1xB : Initialization is running



x1xxB : Reserved



1xxxB : Reserved



This signal represents the physica";
BA_ "GenSigStartValue" SG_ 74 IMU_YawSigSta 2;
BA_ "UserSigValidity" SG_ 74 IMU_YawSigSta 3;
BA_ "RoutingFactor" SG_ 74 IMU_YawSigSta 5;
BA_ "Version" SG_ 74 IMU_YawSigSta "20.03.05";
BA_ "Description" SG_ 74 IMU_LatAccelSigSta "This signal indicates failure status of lateral acceleration signal and sensing element.



0000B : No failure



xxx1B : IMU_Lateral acceleration failure



xx1xB : Initialization is running



x1xxB : Reserved



1xxxB : Reserved



This signal represe";
BA_ "GenSigStartValue" SG_ 74 IMU_LatAccelSigSta 2;
BA_ "UserSigValidity" SG_ 74 IMU_LatAccelSigSta 3;
BA_ "RoutingFactor" SG_ 74 IMU_LatAccelSigSta 5;
BA_ "Version" SG_ 74 IMU_LatAccelSigSta "20.03.05";
BA_ "Description" SG_ 74 IMU_AcuRstSta "This signal indicates the status of IMU.



0000B : Normal mode 



xxx1B : IMU Reset mode



xx1xB : Reserved



x1xxB : Reserved



1xxxB : Reserved



If ACU reset is required, ACU will send IMU RESET bit(XXX1B) up to 30 times and perform a reset. If ";
BA_ "UserSigValidity" SG_ 74 IMU_AcuRstSta 3;
BA_ "RoutingFactor" SG_ 74 IMU_AcuRstSta 5;
BA_ "Version" SG_ 74 IMU_AcuRstSta "20.03.05";
BA_ "Description" SG_ 74 IMU_YawRtVal "This signal indicates Information regarding yaw rate.



physical range : -163.84..163.83 ˚/s = 0000H..FFFEh



Conversion : (PH) = ((HEX)-8000H)*0.005[˚/s/digit]



                            = (HEX)*0.005[˚/s/digit] - 163.84[˚/s]



              ";
BA_ "GenSigStartValue" SG_ 74 IMU_YawRtVal 32768;
BA_ "UserSigValidity" SG_ 74 IMU_YawRtVal 3;
BA_ "RoutingFactor" SG_ 74 IMU_YawRtVal 5;
BA_ "Version" SG_ 74 IMU_YawRtVal "20.03.05";
BA_ "Description" SG_ 74 IMU_LatAccelVal "This signal indicates Information regarding lateral acceleration.



physical range : -4.1768g..4.1765g = 0000H..FFFEh



Conversion : (PH) = ((HEX)-8000H)*0.000127465[g/digit]



                            = (HEX)*0.000127465[g/digit] - 4.17677312[g]

";
BA_ "GenSigStartValue" SG_ 74 IMU_LatAccelVal 32768;
BA_ "UserSigValidity" SG_ 74 IMU_LatAccelVal 3;
BA_ "RoutingFactor" SG_ 74 IMU_LatAccelVal 5;
BA_ "Version" SG_ 74 IMU_LatAccelVal "20.03.05";
BA_ "Description" SG_ 101 IEB_BrkActvSta "This signal indicates that a brake switch is activated or not. When the brake switch is activated(pressed) its value is 02H otherwise its value is 01H.

If the ECU does not support this signal the value is 00H.



이 신호는 EV, FCEV 에서만 사용될 수 있음";
BA_ "UserSigValidity" SG_ 101 IEB_BrkActvSta 3;
BA_ "RoutingFactor" SG_ 101 IEB_BrkActvSta 5;
BA_ "Version" SG_ 101 IEB_BrkActvSta "19.05.05";
BA_ "Description" SG_ 96 ESC_Crc1Val "The data area for CRC calculation is based on the data length (DLC) of the message DB.

The CRC shall be calculated over the entire data block (excluding the CRC bytes) including the user data, alive counter and Data ID



- CRC Polynomial (0x1021) , Ini";
BA_ "GenSigStartValue" SG_ 96 ESC_Crc1Val 65535;
BA_ "UserSigValidity" SG_ 96 ESC_Crc1Val 3;
BA_ "RoutingFactor" SG_ 96 ESC_Crc1Val 5;
BA_ "Version" SG_ 96 ESC_Crc1Val "21.09.03";
BA_ "Description" SG_ 96 ESC_CylPrsrVal "This signal indicates pressure of brake master cylinder and provides information how deeply  a driver is pressing brake pedal.";
BA_ "UserSigValidity" SG_ 96 ESC_CylPrsrVal 3;
BA_ "RoutingFactor" SG_ 96 ESC_CylPrsrVal 5;
BA_ "Version" SG_ 96 ESC_CylPrsrVal "17.12.00";
BA_ "Description" SG_ 96 ESC_VsmActvSta "ESC controller provides an information on VSM (ESC+MDPS) Active signal. It indicates VSM control is

active or inactive.";
BA_ "UserSigValidity" SG_ 96 ESC_VsmActvSta 3;
BA_ "RoutingFactor" SG_ 96 ESC_VsmActvSta 5;
BA_ "Version" SG_ 96 ESC_VsmActvSta "17.12.00";
BA_ "Description" SG_ 96 ESC_VsmDfctvSta "Information regarding the VSM “defective” Indication";
BA_ "UserSigValidity" SG_ 96 ESC_VsmDfctvSta 3;
BA_ "RoutingFactor" SG_ 96 ESC_VsmDfctvSta 5;
BA_ "Version" SG_ 96 ESC_VsmDfctvSta "17.12.00";
BA_ "Description" SG_ 96 ESC_VsmCtrlModSta "Classify mode1 , mode2 and mode3 of torque overlay. 

- Mode1 is sensor value overlay mode.

- Mode2 is output torque overlay mode. 

- Mode3 is for an alternative mode for Mobis VSM system";
BA_ "UserSigValidity" SG_ 96 ESC_VsmCtrlModSta 3;
BA_ "RoutingFactor" SG_ 96 ESC_VsmCtrlModSta 5;
BA_ "Version" SG_ 96 ESC_VsmCtrlModSta "17.12.00";
BA_ "Description" SG_ 96 ESC_AlvCnt1Val "For the first transmission request for a data element the counter shall be initialized with 0 and shall be incremented by 1 for every subsequent send request. 

When the counter reaches the maximum value(0xFF), then it shall restart with 0 for the next s";
BA_ "UserSigValidity" SG_ 96 ESC_AlvCnt1Val 3;
BA_ "RoutingFactor" SG_ 96 ESC_AlvCnt1Val 5;
BA_ "Version" SG_ 96 ESC_AlvCnt1Val "21.09.03";
BA_ "Description" SG_ 96 ESC_StrTqReq "Requested additional Assist torque of MDPS gets from ESC to make vehicle more stable.



Relationship between signals:

ESC_StrTrqReq = 0 Nm  ( DST inactive )

-> ESC_DstAct = 0, ESC_DstCtrMode = 0

ESC_StrTrqReq < 0 Nm  or  ESC_StrTrqReq > 0 Nm  (active";
BA_ "GenSigStartValue" SG_ 96 ESC_StrTqReq 2048;
BA_ "UserSigValidity" SG_ 96 ESC_StrTqReq 3;
BA_ "RoutingFactor" SG_ 96 ESC_StrTqReq 5;
BA_ "Version" SG_ 96 ESC_StrTqReq "17.12.00";
BA_ "Description" SG_ 96 TCS_Sta "Information regarding the status of TCS function.



If the function has not been coded(fixed) yet, this signal will be transmitted as 0xE.



If the vehicle has been applied only ABS(without ESC), this signal will be fixed as 0x0.";
BA_ "UserSigValidity" SG_ 96 TCS_Sta 3;
BA_ "RoutingFactor" SG_ 96 TCS_Sta 5;
BA_ "Version" SG_ 96 TCS_Sta "18.12.01";
BA_ "Description" SG_ 96 ESC_Sta "Information regarding the status of ESC function.



If the function has not been coded(fixed) yet, this signal will be transmitted as 0xE.



If the vehicle has been applied only ABS(without ESC), this signal will be fixed as 0x0.";
BA_ "UserSigValidity" SG_ 96 ESC_Sta 3;
BA_ "RoutingFactor" SG_ 96 ESC_Sta 5;
BA_ "Version" SG_ 96 ESC_Sta "18.12.01";
BA_ "Description" SG_ 111 ABS_ESC_Crc1Val "The data area for CRC calculation is based on the data length (DLC) of the message DB.

The CRC shall be calculated over the entire data block (excluding the CRC bytes) including the user data, alive counter and Data ID



- CRC Polynomial (0x1021) , Ini";
BA_ "GenSigStartValue" SG_ 111 ABS_ESC_Crc1Val 65535;
BA_ "UserSigValidity" SG_ 111 ABS_ESC_Crc1Val 3;
BA_ "RoutingFactor" SG_ 111 ABS_ESC_Crc1Val 5;
BA_ "Version" SG_ 111 ABS_ESC_Crc1Val "21.09.03";
BA_ "Description" SG_ 111 ABS_ESC_AlvCnt1Val "For the first transmission request for a data element the counter shall be initialized with 0 and shall be incremented by 1 for every subsequent send request. 

When the counter reaches the maximum value(0xFF), then it shall restart with 0 for the next s";
BA_ "UserSigValidity" SG_ 111 ABS_ESC_AlvCnt1Val 3;
BA_ "RoutingFactor" SG_ 111 ABS_ESC_AlvCnt1Val 5;
BA_ "Version" SG_ 111 ABS_ESC_AlvCnt1Val "21.09.03";
BA_ "Description" SG_ 111 ABS_ActvSta "ABS controller provides an information on ABS Active signal.



ABS_ACT signal is 1 during the ABS control and if it is not ABS control phase this value is 0.";
BA_ "UserSigValidity" SG_ 111 ABS_ActvSta 3;
BA_ "RoutingFactor" SG_ 111 ABS_ActvSta 5;
BA_ "Version" SG_ 111 ABS_ActvSta "19.07.02";
BA_ "Description" SG_ 111 ABS_DiagSta "Information regarding the ABS/TCS/ESC “diagnostic mode” indication.";
BA_ "UserSigValidity" SG_ 111 ABS_DiagSta 3;
BA_ "RoutingFactor" SG_ 111 ABS_DiagSta 5;
BA_ "Version" SG_ 111 ABS_DiagSta "19.07.02";
BA_ "Description" SG_ 597 LDC_Crc1Val "The data area for CRC calculation is based on the data length (DLC) of the message DB.

The CRC shall be calculated over the entire data block (excluding the CRC bytes) including the user data, alive counter and Data ID

 

- CRC Polynomial (0x1021) , In";
BA_ "GenSigStartValue" SG_ 597 LDC_Crc1Val 65535;
BA_ "UserSigValidity" SG_ 597 LDC_Crc1Val 7;
BA_ "RoutingFactor" SG_ 597 LDC_Crc1Val 2;
BA_ "Version" SG_ 597 LDC_Crc1Val "18.11.08";
BA_ "Description" SG_ 597 LDC_AlvCnt1Val "For the first transmission request for a data element the counter shall be initialized with 0 and shall be incremented by 1 for every subsequent send request. 

When the counter reaches the maximum value(0xFF), then it shall restart with 0 for the next s";
BA_ "UserSigValidity" SG_ 597 LDC_AlvCnt1Val 7;
BA_ "RoutingFactor" SG_ 597 LDC_AlvCnt1Val 2;
BA_ "Version" SG_ 597 LDC_AlvCnt1Val "18.11.08";
BA_ "Description" SG_ 597 LDC_SysOpSta "LDC operating status";
BA_ "UserSigValidity" SG_ 597 LDC_SysOpSta 7;
BA_ "RoutingFactor" SG_ 597 LDC_SysOpSta 2;
BA_ "Version" SG_ 597 LDC_SysOpSta "18.08.05";
BA_ "Description" SG_ 597 LDC_SysFltSta "LDC Fault status";
BA_ "UserSigValidity" SG_ 597 LDC_SysFltSta 7;
BA_ "RoutingFactor" SG_ 597 LDC_SysFltSta 2;
BA_ "Version" SG_ 597 LDC_SysFltSta "18.08.05";
BA_ "Description" SG_ 647 CCU_update_enable "Signal to check update availability";
BA_ "GenSigSendType" SG_ 647 CCU_update_enable 4;
BA_ "GenSigStartValue" SG_ 647 CCU_update_enable 3;
BA_ "UserSigValidity" SG_ 647 CCU_update_enable 0;
BA_ "Version" SG_ 647 CCU_update_enable "24.04.06";
BA_ "Description" SG_ 160 WHL_Crc1Val "The data area for CRC calculation is based on the data length (DLC) of the message DB.

The CRC shall be calculated over the entire data block (excluding the CRC bytes) including the user data, alive counter and Data ID



- CRC Polynomial (0x1021) , Ini";
BA_ "GenSigStartValue" SG_ 160 WHL_Crc1Val 65535;
BA_ "UserSigValidity" SG_ 160 WHL_Crc1Val 3;
BA_ "RoutingFactor" SG_ 160 WHL_Crc1Val 5;
BA_ "Version" SG_ 160 WHL_Crc1Val "21.09.03";
BA_ "Description" SG_ 160 WHL_SpdRRVal "This signal provides the wheel velocity of each wheel and have 14 bits length and a resolution of 0.03125 km^h.(This resolution is higher than that of signal in TCS5).

In case of failure of one wheel speed sensor, the value 3FFFH is used as error identi";
BA_ "UserSigValidity" SG_ 160 WHL_SpdRRVal 3;
BA_ "RoutingFactor" SG_ 160 WHL_SpdRRVal 5;
BA_ "Version" SG_ 160 WHL_SpdRRVal "17.12.00";
BA_ "Description" SG_ 160 WHL_AlvCnt1Val "For the first transmission request for a data element the counter shall be initialized with 0 and shall be incremented by 1 for every subsequent send request. 

When the counter reaches the maximum value(0xFF), then it shall restart with 0 for the next s";
BA_ "UserSigValidity" SG_ 160 WHL_AlvCnt1Val 3;
BA_ "RoutingFactor" SG_ 160 WHL_AlvCnt1Val 5;
BA_ "Version" SG_ 160 WHL_AlvCnt1Val "21.09.03";
BA_ "Description" SG_ 160 WHL_SpdFLVal "This signal provides the wheel velocity of each wheel and have 14 bits length and a resolution of 0.03125 km^h.(This resolution is higher than that of signal in TCS5).

In case of failure of one wheel speed sensor, the value 3FFFH is used as error identi";
BA_ "UserSigValidity" SG_ 160 WHL_SpdFLVal 3;
BA_ "RoutingFactor" SG_ 160 WHL_SpdFLVal 5;
BA_ "Version" SG_ 160 WHL_SpdFLVal "17.12.00";
BA_ "Description" SG_ 160 WHL_SpdFRVal "This signal provides the wheel velocity of each wheel and have 14 bits length and a resolution of 0.03125 km^h.(This resolution is higher than that of signal in TCS5).

In case of failure of one wheel speed sensor, the value 3FFFH is used as error identi";
BA_ "UserSigValidity" SG_ 160 WHL_SpdFRVal 3;
BA_ "RoutingFactor" SG_ 160 WHL_SpdFRVal 5;
BA_ "Version" SG_ 160 WHL_SpdFRVal "17.12.00";
BA_ "Description" SG_ 160 WHL_SpdRLVal "This signal provides the wheel velocity of each wheel and have 14 bits length and a resolution of 0.03125 km^h.(This resolution is higher than that of signal in TCS5).

In case of failure of one wheel speed sensor, the value 3FFFH is used as error identi";
BA_ "UserSigValidity" SG_ 160 WHL_SpdRLVal 3;
BA_ "RoutingFactor" SG_ 160 WHL_SpdRLVal 5;
BA_ "Version" SG_ 160 WHL_SpdRLVal "17.12.00";
BA_ "Description" SG_ 176 ICSC_Crc1Val "The data area for CRC calculation is based on the data length (DLC) of the message DB.

The CRC shall be calculated over the entire data block (excluding the CRC bytes) including the user data, alive counter and Data ID



- CRC Polynomial (0x1021) , Ini";
BA_ "GenSigStartValue" SG_ 176 ICSC_Crc1Val 65535;
BA_ "UserSigValidity" SG_ 176 ICSC_Crc1Val 3;
BA_ "RoutingFactor" SG_ 176 ICSC_Crc1Val 5;
BA_ "Version" SG_ 176 ICSC_Crc1Val "21.09.03";
BA_ "Description" SG_ 176 ICSC_AlvCnt1Val "For the first transmission request for a data element the counter shall be initialized with 0 and shall be incremented by 1 for every subsequent send request. 

When the counter reaches the maximum value(0xFF), then it shall restart with 0 for the next s";
BA_ "UserSigValidity" SG_ 176 ICSC_AlvCnt1Val 3;
BA_ "RoutingFactor" SG_ 176 ICSC_AlvCnt1Val 5;
BA_ "Version" SG_ 176 ICSC_AlvCnt1Val "21.09.03";
BA_ "Description" SG_ 176 ESA_MdpsStrTqReq "ESA steering torque request to MDPS";
BA_ "GenSigStartValue" SG_ 176 ESA_MdpsStrTqReq 2048;
BA_ "UserSigValidity" SG_ 176 ESA_MdpsStrTqReq 3;
BA_ "RoutingFactor" SG_ 176 ESA_MdpsStrTqReq 5;
BA_ "Version" SG_ 176 ESA_MdpsStrTqReq "19.09.04";
BA_ "Description" SG_ 176 ESA_MdpsActvSta "ESA Activation Flag";
BA_ "UserSigValidity" SG_ 176 ESA_MdpsActvSta 3;
BA_ "RoutingFactor" SG_ 176 ESA_MdpsActvSta 5;
BA_ "Version" SG_ 176 ESA_MdpsActvSta "19.09.04";
BA_ "Description" SG_ 176 ESA_MdpsDfctvSta "Information regarding the ESA defective indication";
BA_ "UserSigValidity" SG_ 176 ESA_MdpsDfctvSta 3;
BA_ "RoutingFactor" SG_ 176 ESA_MdpsDfctvSta 5;
BA_ "Version" SG_ 176 ESA_MdpsDfctvSta "19.09.04";
BA_ "Description" SG_ 176 SFO_ActvSta "SFO Active Status";
BA_ "UserSigValidity" SG_ 176 SFO_ActvSta 3;
BA_ "RoutingFactor" SG_ 176 SFO_ActvSta 5;
BA_ "Version" SG_ 176 SFO_ActvSta "23.10.03";
BA_ "Description" SG_ 745 PDC_FD_Crc15Val "The data area for CRC calculation is based on the data length (DLC) of the message DB.

The CRC shall be calculated over the entire data block (excluding the CRC bytes) including the user data, alive counter and Data ID



- CRC Polynomial (0x1021) , Ini";
BA_ "GenSigSendType" SG_ 745 PDC_FD_Crc15Val 4;
BA_ "GenSigStartValue" SG_ 745 PDC_FD_Crc15Val 65535;
BA_ "UserSigValidity" SG_ 745 PDC_FD_Crc15Val 3;
BA_ "Version" SG_ 745 PDC_FD_Crc15Val "24.04.08";
BA_ "Description" SG_ 745 PDC_FD_AlvCnt15Val "For the first transmission request for a data element the counter shall be initialized with 0 and shall be incremented by 1 for every subsequent send request. 

When the counter reaches the maximum value(0xFF), then it shall restart with 0 for the next s";
BA_ "GenSigSendType" SG_ 745 PDC_FD_AlvCnt15Val 4;
BA_ "UserSigValidity" SG_ 745 PDC_FD_AlvCnt15Val 3;
BA_ "Version" SG_ 745 PDC_FD_AlvCnt15Val "24.04.08";
BA_ "Description" SG_ 745 PDC_ResetPreWrngForOthers "This is a warning signal for reset.  This signal is used for preparing sideeffect of reset by Receivers";
BA_ "GenSigSendType" SG_ 745 PDC_ResetPreWrngForOthers 4;
BA_ "UserSigValidity" SG_ 745 PDC_ResetPreWrngForOthers 0;
BA_ "Version" SG_ 745 PDC_ResetPreWrngForOthers "24.05.05";
BA_ "Description" SG_ 745 PDC_ResetReqForOthers "This is a request signal for SW reset except for Gateway";
BA_ "GenSigSendType" SG_ 745 PDC_ResetReqForOthers 4;
BA_ "UserSigValidity" SG_ 745 PDC_ResetReqForOthers 0;
BA_ "Version" SG_ 745 PDC_ResetReqForOthers "24.05.05";
BA_ "Description" SG_ 203 ADAS_CMD_Crc35Val "The data area for CRC calculation is based on the data length (DLC) of the message DB.

The CRC shall be calculated over the entire data block (excluding the CRC bytes) including the user data, alive counter and Data ID



- CRC Polynomial (0x1021) , Ini";
BA_ "GenSigStartValue" SG_ 203 ADAS_CMD_Crc35Val 65535;
BA_ "UserSigValidity" SG_ 203 ADAS_CMD_Crc35Val 3;
BA_ "RoutingFactor" SG_ 203 ADAS_CMD_Crc35Val 5;
BA_ "Version" SG_ 203 ADAS_CMD_Crc35Val "21.11.03";
BA_ "Description" SG_ 203 ADAS_CMD_AlvCnt35Val "For the first transmission request for a data element the counter shall be initialized with 0 and shall be incremented by 1 for every subsequent send request. 

When the counter reaches the maximum value(0xFF), then it shall restart with 0 for the next s";
BA_ "UserSigValidity" SG_ 203 ADAS_CMD_AlvCnt35Val 3;
BA_ "RoutingFactor" SG_ 203 ADAS_CMD_AlvCnt35Val 5;
BA_ "Version" SG_ 203 ADAS_CMD_AlvCnt35Val "21.11.03";
BA_ "Description" SG_ 203 ADAS_ActvACISta "State for angle control";
BA_ "UserSigValidity" SG_ 203 ADAS_ActvACISta 3;
BA_ "RoutingFactor" SG_ 203 ADAS_ActvACISta 5;
BA_ "Version" SG_ 203 ADAS_ActvACISta "21.11.04";
BA_ "Description" SG_ 203 ADAS_ActvACILvl2Sta "State for Level 2 angle control";
BA_ "UserSigValidity" SG_ 203 ADAS_ActvACILvl2Sta 3;
BA_ "RoutingFactor" SG_ 203 ADAS_ActvACILvl2Sta 5;
BA_ "Version" SG_ 203 ADAS_ActvACILvl2Sta "21.11.04";
BA_ "Description" SG_ 203 ADAS_StrAnglReqVal "Request angle control value";
BA_ "UserSigValidity" SG_ 203 ADAS_StrAnglReqVal 3;
BA_ "RoutingFactor" SG_ 203 ADAS_StrAnglReqVal 5;
BA_ "Version" SG_ 203 ADAS_StrAnglReqVal "21.11.04";
BA_ "Description" SG_ 203 ADAS_ACIAnglTqRedcGainVal "Angle Torque Reduction Gain";
BA_ "UserSigValidity" SG_ 203 ADAS_ACIAnglTqRedcGainVal 3;
BA_ "RoutingFactor" SG_ 203 ADAS_ACIAnglTqRedcGainVal 5;
BA_ "Version" SG_ 203 ADAS_ACIAnglTqRedcGainVal "21.11.04";
BA_ "Description" SG_ 203 FCA_ESA_ActvSta "State for FCA w/ESA";
BA_ "UserSigValidity" SG_ 203 FCA_ESA_ActvSta 3;
BA_ "RoutingFactor" SG_ 203 FCA_ESA_ActvSta 5;
BA_ "Version" SG_ 203 FCA_ESA_ActvSta "21.11.04";
BA_ "Description" SG_ 203 FCA_ESA_TqBstGainVal "FCA w/ESA Torque boost Gain";
BA_ "UserSigValidity" SG_ 203 FCA_ESA_TqBstGainVal 3;
BA_ "RoutingFactor" SG_ 203 FCA_ESA_TqBstGainVal 5;
BA_ "Version" SG_ 203 FCA_ESA_TqBstGainVal "21.11.04";
BA_ "Description" SG_ 1168 SFA_02_Crc2Val "The data area for CRC calculation is based on the data length (DLC) of the message DB.

The CRC shall be calculated over the entire data block (excluding the CRC bytes) including the user data, alive counter and Data ID



- CRC Polynomial (0x1021) , Ini";
BA_ "GenSigSendType" SG_ 1168 SFA_02_Crc2Val 4;
BA_ "GenSigStartValue" SG_ 1168 SFA_02_Crc2Val 65535;
BA_ "UserSigValidity" SG_ 1168 SFA_02_Crc2Val 3;
BA_ "Version" SG_ 1168 SFA_02_Crc2Val "23.05.02";
BA_ "Description" SG_ 1168 SFA_02_AlvCnt2Val "For the first transmission request for a data element the counter shall be initialized with 0 and shall be incremented by 1 for every subsequent send request. 

When the counter reaches the maximum value(0xFF), then it shall restart with 0 for the next s";
BA_ "GenSigSendType" SG_ 1168 SFA_02_AlvCnt2Val 4;
BA_ "UserSigValidity" SG_ 1168 SFA_02_AlvCnt2Val 3;
BA_ "Version" SG_ 1168 SFA_02_AlvCnt2Val "23.05.02";
BA_ "GenSigSendType" SG_ 1168 SFA_AlignWarningLamp 4;
BA_ "UserSigValidity" SG_ 1168 SFA_AlignWarningLamp 0;
BA_ "Version" SG_ 1168 SFA_AlignWarningLamp "24.04.06";
BA_ "GenSigStartValue" SG_ 221 Rack_Command_Diff 524000;
BA_ "GenSigStartValue" SG_ 221 SFA1_MotorTq 2048;
BA_ "GenSigStartValue" SG_ 221 SFA1_AbsoluteAg 32767;
BA_ "Description" SG_ 221 SFA_Crc1Val "The data area for CRC calculation is based on the data length (DLC) of the message DB.

The CRC shall be calculated over the entire data block (excluding the CRC bytes) including the user data, alive counter and Data ID



- CRC Polynomial (0x1021) , Ini";
BA_ "GenSigStartValue" SG_ 221 SFA_Crc1Val 65535;
BA_ "UserSigValidity" SG_ 221 SFA_Crc1Val 3;
BA_ "RoutingFactor" SG_ 221 SFA_Crc1Val 5;
BA_ "Version" SG_ 221 SFA_Crc1Val "23.10.03";
BA_ "Description" SG_ 221 SFA_CenteringStatus "SFA Centering Status";
BA_ "UserSigValidity" SG_ 221 SFA_CenteringStatus 0;
BA_ "RoutingFactor" SG_ 221 SFA_CenteringStatus 5;
BA_ "Version" SG_ 221 SFA_CenteringStatus "23.10.03";
BA_ "Description" SG_ 221 SbW_CenteringStatus "SbW Centering Status";
BA_ "UserSigValidity" SG_ 221 SbW_CenteringStatus 0;
BA_ "RoutingFactor" SG_ 221 SbW_CenteringStatus 5;
BA_ "Version" SG_ 221 SbW_CenteringStatus "23.10.03";
BA_ "Description" SG_ 221 SFA_IgnitionStatus "SFA IgnitionS tatus";
BA_ "UserSigValidity" SG_ 221 SFA_IgnitionStatus 0;
BA_ "RoutingFactor" SG_ 221 SFA_IgnitionStatus 5;
BA_ "Version" SG_ 221 SFA_IgnitionStatus "23.10.03";
BA_ "Description" SG_ 221 SFA_OHP_Status "SFA OHP Status";
BA_ "UserSigValidity" SG_ 221 SFA_OHP_Status 0;
BA_ "RoutingFactor" SG_ 221 SFA_OHP_Status 5;
BA_ "Version" SG_ 221 SFA_OHP_Status "23.10.03";
BA_ "Description" SG_ 221 SFA_SFA1EcuStatus "SFA1 Ecu Status";
BA_ "UserSigValidity" SG_ 221 SFA_SFA1EcuStatus 0;
BA_ "RoutingFactor" SG_ 221 SFA_SFA1EcuStatus 5;
BA_ "Version" SG_ 221 SFA_SFA1EcuStatus "24.01.06";
BA_ "Description" SG_ 221 SFA_SFA2EcuStatus "SFA2 Ecu Status";
BA_ "UserSigValidity" SG_ 221 SFA_SFA2EcuStatus 0;
BA_ "RoutingFactor" SG_ 221 SFA_SFA2EcuStatus 5;
BA_ "Version" SG_ 221 SFA_SFA2EcuStatus "24.01.06";
BA_ "Description" SG_ 221 SFA_RWA1EcuStatus "RWA1 Ecu Status";
BA_ "UserSigValidity" SG_ 221 SFA_RWA1EcuStatus 0;
BA_ "RoutingFactor" SG_ 221 SFA_RWA1EcuStatus 5;
BA_ "Version" SG_ 221 SFA_RWA1EcuStatus "24.01.06";
BA_ "Description" SG_ 221 SFA_RWA2EcuStatus "RWA2 Ecu Status";
BA_ "UserSigValidity" SG_ 221 SFA_RWA2EcuStatus 0;
BA_ "RoutingFactor" SG_ 221 SFA_RWA2EcuStatus 5;
BA_ "Version" SG_ 221 SFA_RWA2EcuStatus "24.01.06";
BA_ "Description" SG_ 221 SFA_SteerWheelAngSpd "Information regarding the steering wheel rotation speed 

(PH) = (HEX) * 4 (0 ≤ HEX < 254)";
BA_ "GenSigStartValue" SG_ 221 SFA_SteerWheelAngSpd 255;
BA_ "UserSigValidity" SG_ 221 SFA_SteerWheelAngSpd 0;
BA_ "RoutingFactor" SG_ 221 SFA_SteerWheelAngSpd 5;
BA_ "Version" SG_ 221 SFA_SteerWheelAngSpd "24.05.03";
BA_ "Description" SG_ 221 SFA_AlvCnt1Val "For the first transmission request for a data element the counter shall be initialized with 0 and shall be incremented by 1 for every subsequent send request. 

When the counter reaches the maximum value(0xFF), then it shall restart with 0 for the next s";
BA_ "UserSigValidity" SG_ 221 SFA_AlvCnt1Val 3;
BA_ "RoutingFactor" SG_ 221 SFA_AlvCnt1Val 5;
BA_ "Version" SG_ 221 SFA_AlvCnt1Val "23.10.03";
BA_ "Description" SG_ 221 SFA_SteerWheelTorque "SFA Steering Wheel Torque, 0xFFE:Error, phy range : -20~20";
BA_ "UserSigValidity" SG_ 221 SFA_SteerWheelTorque 0;
BA_ "RoutingFactor" SG_ 221 SFA_SteerWheelTorque 5;
BA_ "Version" SG_ 221 SFA_SteerWheelTorque "23.10.03";
BA_ "Description" SG_ 221 SFA_SteerWheelAngle "SFA Steering Wheel Angle, 0xFFFE:Error, phy range : -655~655";
BA_ "UserSigValidity" SG_ 221 SFA_SteerWheelAngle 0;
BA_ "RoutingFactor" SG_ 221 SFA_SteerWheelAngle 5;
BA_ "Version" SG_ 221 SFA_SteerWheelAngle "23.10.03";
BA_ "Description" SG_ 221 Reprogram_State_SFA1 "Information regarding the reprogram state";
BA_ "GenSigStartValue" SG_ 221 Reprogram_State_SFA1 3;
BA_ "UserSigValidity" SG_ 221 Reprogram_State_SFA1 0;
BA_ "RoutingFactor" SG_ 221 Reprogram_State_SFA1 5;
BA_ "Version" SG_ 221 Reprogram_State_SFA1 "24.04.06";
BA_ "Description" SG_ 221 SFA1_ResetOpSta "Controller reset operation status";
BA_ "UserSigValidity" SG_ 221 SFA1_ResetOpSta 0;
BA_ "RoutingFactor" SG_ 221 SFA1_ResetOpSta 5;
BA_ "Version" SG_ 221 SFA1_ResetOpSta "24.05.03";
BA_ "Description" SG_ 221 SFA_ControlMode "SFA Control Mode stauts";
BA_ "UserSigValidity" SG_ 221 SFA_ControlMode 0;
BA_ "RoutingFactor" SG_ 221 SFA_ControlMode 5;
BA_ "Version" SG_ 221 SFA_ControlMode "24.01.06";
BA_ "Description" SG_ 221 SFA_EcuRole "SFA Ecu Role";
BA_ "UserSigValidity" SG_ 221 SFA_EcuRole 0;
BA_ "RoutingFactor" SG_ 221 SFA_EcuRole 5;
BA_ "Version" SG_ 221 SFA_EcuRole "23.10.03";
BA_ "Description" SG_ 221 SFA_WarningLamp "SFA_Warning Lamp status";
BA_ "UserSigValidity" SG_ 221 SFA_WarningLamp 0;
BA_ "RoutingFactor" SG_ 221 SFA_WarningLamp 5;
BA_ "Version" SG_ 221 SFA_WarningLamp "23.10.03";
BA_ "Description" SG_ 221 SFA_RackCommand "SFA Target Rack Position Command, 0x7FFE:Error, phy range : -484~484";
BA_ "UserSigValidity" SG_ 221 SFA_RackCommand 0;
BA_ "RoutingFactor" SG_ 221 SFA_RackCommand 5;
BA_ "Version" SG_ 221 SFA_RackCommand "23.10.03";
BA_ "Description" SG_ 221 SFA_FailoverActvSta "SFA Failover Active Status";
BA_ "UserSigValidity" SG_ 221 SFA_FailoverActvSta 0;
BA_ "RoutingFactor" SG_ 221 SFA_FailoverActvSta 5;
BA_ "Version" SG_ 221 SFA_FailoverActvSta "23.10.03";
BA_ "Description" SG_ 221 SFA_BrakeReqActSta "SFA Brake Request Active Status";
BA_ "UserSigValidity" SG_ 221 SFA_BrakeReqActSta 0;
BA_ "RoutingFactor" SG_ 221 SFA_BrakeReqActSta 5;
BA_ "Version" SG_ 221 SFA_BrakeReqActSta "23.10.03";
BA_ "Description" SG_ 221 SFA_CreepReqActSta "SFA Creep Request Active Status";
BA_ "UserSigValidity" SG_ 221 SFA_CreepReqActSta 0;
BA_ "RoutingFactor" SG_ 221 SFA_CreepReqActSta 5;
BA_ "Version" SG_ 221 SFA_CreepReqActSta "23.10.10";
BA_ "Description" SG_ 221 SbW_EvDrvRdyEnb "SFA Shift Lock Requst Active Status";
BA_ "UserSigValidity" SG_ 221 SbW_EvDrvRdyEnb 0;
BA_ "RoutingFactor" SG_ 221 SbW_EvDrvRdyEnb 5;
BA_ "Version" SG_ 221 SbW_EvDrvRdyEnb "24.04.01";
BA_ "Description" SG_ 221 SFA_CluWarningLamp "SFA Cluster Warning Lamp status";
BA_ "UserSigValidity" SG_ 221 SFA_CluWarningLamp 3;
BA_ "RoutingFactor" SG_ 221 SFA_CluWarningLamp 5;
BA_ "Version" SG_ 221 SFA_CluWarningLamp "23.10.03";
BA_ "Description" SG_ 221 SFA_CluWarningSentence "SFA-CLU Warning Sentence";
BA_ "UserSigValidity" SG_ 221 SFA_CluWarningSentence 3;
BA_ "RoutingFactor" SG_ 221 SFA_CluWarningSentence 5;
BA_ "Version" SG_ 221 SFA_CluWarningSentence "24.04.06";
BA_ "GenSigStartValue" SG_ 222 RWA1_MotorTorque 2048;
BA_ "Description" SG_ 222 RWA_Crc1Val "The data area for CRC calculation is based on the data length (DLC) of the message DB.

The CRC shall be calculated over the entire data block (excluding the CRC bytes) including the user data, alive counter and Data ID



- CRC Polynomial (0x1021) , Ini";
BA_ "GenSigStartValue" SG_ 222 RWA_Crc1Val 65535;
BA_ "UserSigValidity" SG_ 222 RWA_Crc1Val 3;
BA_ "RoutingFactor" SG_ 222 RWA_Crc1Val 5;
BA_ "Version" SG_ 222 RWA_Crc1Val "23.10.03";
BA_ "Description" SG_ 222 RWA_IgnitionStatus "RWA IGN Status";
BA_ "UserSigValidity" SG_ 222 RWA_IgnitionStatus 0;
BA_ "RoutingFactor" SG_ 222 RWA_IgnitionStatus 5;
BA_ "Version" SG_ 222 RWA_IgnitionStatus "23.10.03";
BA_ "Description" SG_ 222 RWA_OHP_Status "RWA OHP status";
BA_ "UserSigValidity" SG_ 222 RWA_OHP_Status 0;
BA_ "RoutingFactor" SG_ 222 RWA_OHP_Status 5;
BA_ "Version" SG_ 222 RWA_OHP_Status "23.10.03";
BA_ "Description" SG_ 222 RWA_SFA1EcuStatus "SFA1 ECU Status";
BA_ "UserSigValidity" SG_ 222 RWA_SFA1EcuStatus 0;
BA_ "RoutingFactor" SG_ 222 RWA_SFA1EcuStatus 5;
BA_ "Version" SG_ 222 RWA_SFA1EcuStatus "24.01.06";
BA_ "Description" SG_ 222 RWA_SFA2EcuStatus "SFA2 Ecu Status";
BA_ "UserSigValidity" SG_ 222 RWA_SFA2EcuStatus 0;
BA_ "RoutingFactor" SG_ 222 RWA_SFA2EcuStatus 5;
BA_ "Version" SG_ 222 RWA_SFA2EcuStatus "24.01.06";
BA_ "Description" SG_ 222 RWA_RWA1EcuStatus "RWA1 Ecu Status";
BA_ "UserSigValidity" SG_ 222 RWA_RWA1EcuStatus 0;
BA_ "RoutingFactor" SG_ 222 RWA_RWA1EcuStatus 5;
BA_ "Version" SG_ 222 RWA_RWA1EcuStatus "24.01.06";
BA_ "Description" SG_ 222 RWA_RWA2EcuStatus "RWA2 ECU Status";
BA_ "UserSigValidity" SG_ 222 RWA_RWA2EcuStatus 0;
BA_ "RoutingFactor" SG_ 222 RWA_RWA2EcuStatus 5;
BA_ "Version" SG_ 222 RWA_RWA2EcuStatus "24.01.06";
BA_ "Description" SG_ 222 RWA_CreepReqActSta "RWA Creep Request Active Status";
BA_ "UserSigValidity" SG_ 222 RWA_CreepReqActSta 0;
BA_ "RoutingFactor" SG_ 222 RWA_CreepReqActSta 5;
BA_ "Version" SG_ 222 RWA_CreepReqActSta "24.05.03";
BA_ "Description" SG_ 222 RWA_PinionAngSpd "Information regarding the pinion rotation speed 

(PH) = (HEX) * 4 (0 ≤ HEX < 254)";
BA_ "GenSigStartValue" SG_ 222 RWA_PinionAngSpd 255;
BA_ "UserSigValidity" SG_ 222 RWA_PinionAngSpd 0;
BA_ "RoutingFactor" SG_ 222 RWA_PinionAngSpd 5;
BA_ "Version" SG_ 222 RWA_PinionAngSpd "24.04.03";
BA_ "Description" SG_ 222 RWA_AlvCnt1Val "For the first transmission request for a data element the counter shall be initialized with 0 and shall be incremented by 1 for every subsequent send request. 

When the counter reaches the maximum value(0xFF), then it shall restart with 0 for the next s";
BA_ "UserSigValidity" SG_ 222 RWA_AlvCnt1Val 3;
BA_ "RoutingFactor" SG_ 222 RWA_AlvCnt1Val 5;
BA_ "Version" SG_ 222 RWA_AlvCnt1Val "23.10.03";
BA_ "Description" SG_ 222 RWA_RackForce "RWA Rack Force, 0xFFFE : error, phy range : -32700 ~ 32700";
BA_ "UserSigValidity" SG_ 222 RWA_RackForce 0;
BA_ "RoutingFactor" SG_ 222 RWA_RackForce 5;
BA_ "Version" SG_ 222 RWA_RackForce "23.10.03";
BA_ "Description" SG_ 222 RWA_RackPosition "RWA Rack Position, 0xFFFFE : error, phy range : -480 ~ 480";
BA_ "UserSigValidity" SG_ 222 RWA_RackPosition 0;
BA_ "RoutingFactor" SG_ 222 RWA_RackPosition 5;
BA_ "Version" SG_ 222 RWA_RackPosition "23.10.03";
BA_ "Description" SG_ 222 Reprogram_State_RWA1 "Information regarding the reprogram state";
BA_ "GenSigStartValue" SG_ 222 Reprogram_State_RWA1 3;
BA_ "UserSigValidity" SG_ 222 Reprogram_State_RWA1 0;
BA_ "RoutingFactor" SG_ 222 Reprogram_State_RWA1 5;
BA_ "Version" SG_ 222 Reprogram_State_RWA1 "24.04.06";
BA_ "Description" SG_ 222 RWA1_ResetOpSta "Controller reset operation status";
BA_ "UserSigValidity" SG_ 222 RWA1_ResetOpSta 0;
BA_ "RoutingFactor" SG_ 222 RWA1_ResetOpSta 5;
BA_ "Version" SG_ 222 RWA1_ResetOpSta "24.05.03";
BA_ "Description" SG_ 222 RWA_RackSpeed "RWA Rack Speed, 0xFFFFE : error, phy range :  -480 ~ 480";
BA_ "UserSigValidity" SG_ 222 RWA_RackSpeed 0;
BA_ "RoutingFactor" SG_ 222 RWA_RackSpeed 5;
BA_ "Version" SG_ 222 RWA_RackSpeed "23.10.03";
BA_ "Description" SG_ 222 RWA_EcuRole "RWA ECU Role";
BA_ "UserSigValidity" SG_ 222 RWA_EcuRole 0;
BA_ "RoutingFactor" SG_ 222 RWA_EcuRole 5;
BA_ "Version" SG_ 222 RWA_EcuRole "23.10.03";
BA_ "Description" SG_ 222 RWA_WarningLamp "RWA Internal Warning Lamp Flag";
BA_ "UserSigValidity" SG_ 222 RWA_WarningLamp 0;
BA_ "RoutingFactor" SG_ 222 RWA_WarningLamp 5;
BA_ "Version" SG_ 222 RWA_WarningLamp "23.10.03";
BA_ "Description" SG_ 222 RWA_ControlMode "RWA Internal Steering Control Mode (Standby, Normal…)";
BA_ "UserSigValidity" SG_ 222 RWA_ControlMode 0;
BA_ "RoutingFactor" SG_ 222 RWA_ControlMode 5;
BA_ "Version" SG_ 222 RWA_ControlMode "24.01.06";
BA_ "Description" SG_ 222 RWA_CenteringStatus "RWA Centering and Alignment Status";
BA_ "UserSigValidity" SG_ 222 RWA_CenteringStatus 0;
BA_ "RoutingFactor" SG_ 222 RWA_CenteringStatus 5;
BA_ "Version" SG_ 222 RWA_CenteringStatus "23.10.03";
BA_ "Description" SG_ 222 RWA_OLP "RWA OLP Status";
BA_ "UserSigValidity" SG_ 222 RWA_OLP 0;
BA_ "RoutingFactor" SG_ 222 RWA_OLP 5;
BA_ "Version" SG_ 222 RWA_OLP "23.10.03";
BA_ "Description" SG_ 222 RWA_PinionAngle "RWA Pinion Angle, 0x7FFF : error";
BA_ "UserSigValidity" SG_ 222 RWA_PinionAngle 0;
BA_ "RoutingFactor" SG_ 222 RWA_PinionAngle 5;
BA_ "Version" SG_ 222 RWA_PinionAngle "24.01.06";
BA_ "UsrSigPurpose" SG_ 1669 CCP_MDPS_SFA_RESP1_Byte0 7;
BA_ "GenSigSendType" SG_ 1669 CCP_MDPS_SFA_RESP1_Byte0 2;
BA_ "UserSigValidity" SG_ 1669 CCP_MDPS_SFA_RESP1_Byte0 0;
BA_ "NetworkRequest" SG_ 1669 CCP_MDPS_SFA_RESP1_Byte0 0;
BA_ "NetworkRequestHoldingTime" SG_ 1669 CCP_MDPS_SFA_RESP1_Byte0 5000;
BA_ "Version" SG_ 1669 CCP_MDPS_SFA_RESP1_Byte0 "23.04.01";
BA_ "UsrSigPurpose" SG_ 1669 CCP_MDPS_SFA_RESP1_Byte2 7;
BA_ "GenSigSendType" SG_ 1669 CCP_MDPS_SFA_RESP1_Byte2 2;
BA_ "UserSigValidity" SG_ 1669 CCP_MDPS_SFA_RESP1_Byte2 0;
BA_ "NetworkRequest" SG_ 1669 CCP_MDPS_SFA_RESP1_Byte2 0;
BA_ "NetworkRequestHoldingTime" SG_ 1669 CCP_MDPS_SFA_RESP1_Byte2 5000;
BA_ "Version" SG_ 1669 CCP_MDPS_SFA_RESP1_Byte2 "23.04.01";
BA_ "UsrSigPurpose" SG_ 1669 CCP_MDPS_SFA_RESP1_Byte3 7;
BA_ "GenSigSendType" SG_ 1669 CCP_MDPS_SFA_RESP1_Byte3 2;
BA_ "UserSigValidity" SG_ 1669 CCP_MDPS_SFA_RESP1_Byte3 0;
BA_ "NetworkRequest" SG_ 1669 CCP_MDPS_SFA_RESP1_Byte3 0;
BA_ "NetworkRequestHoldingTime" SG_ 1669 CCP_MDPS_SFA_RESP1_Byte3 5000;
BA_ "Version" SG_ 1669 CCP_MDPS_SFA_RESP1_Byte3 "23.04.01";
BA_ "UsrSigPurpose" SG_ 1669 CCP_MDPS_SFA_RESP1_Byte4 7;
BA_ "GenSigSendType" SG_ 1669 CCP_MDPS_SFA_RESP1_Byte4 2;
BA_ "UserSigValidity" SG_ 1669 CCP_MDPS_SFA_RESP1_Byte4 0;
BA_ "NetworkRequest" SG_ 1669 CCP_MDPS_SFA_RESP1_Byte4 0;
BA_ "NetworkRequestHoldingTime" SG_ 1669 CCP_MDPS_SFA_RESP1_Byte4 5000;
BA_ "Version" SG_ 1669 CCP_MDPS_SFA_RESP1_Byte4 "23.04.01";
BA_ "UsrSigPurpose" SG_ 1669 CCP_MDPS_SFA_RESP1_Byte5 7;
BA_ "GenSigSendType" SG_ 1669 CCP_MDPS_SFA_RESP1_Byte5 2;
BA_ "UserSigValidity" SG_ 1669 CCP_MDPS_SFA_RESP1_Byte5 0;
BA_ "NetworkRequest" SG_ 1669 CCP_MDPS_SFA_RESP1_Byte5 0;
BA_ "NetworkRequestHoldingTime" SG_ 1669 CCP_MDPS_SFA_RESP1_Byte5 5000;
BA_ "Version" SG_ 1669 CCP_MDPS_SFA_RESP1_Byte5 "23.04.01";
BA_ "UsrSigPurpose" SG_ 1669 CCP_MDPS_SFA_RESP1_Byte6 7;
BA_ "GenSigSendType" SG_ 1669 CCP_MDPS_SFA_RESP1_Byte6 2;
BA_ "UserSigValidity" SG_ 1669 CCP_MDPS_SFA_RESP1_Byte6 0;
BA_ "NetworkRequest" SG_ 1669 CCP_MDPS_SFA_RESP1_Byte6 0;
BA_ "NetworkRequestHoldingTime" SG_ 1669 CCP_MDPS_SFA_RESP1_Byte6 5000;
BA_ "Version" SG_ 1669 CCP_MDPS_SFA_RESP1_Byte6 "23.04.01";
BA_ "UsrSigPurpose" SG_ 1669 CCP_MDPS_SFA_RESP1_Byte7 7;
BA_ "GenSigSendType" SG_ 1669 CCP_MDPS_SFA_RESP1_Byte7 2;
BA_ "UserSigValidity" SG_ 1669 CCP_MDPS_SFA_RESP1_Byte7 0;
BA_ "NetworkRequest" SG_ 1669 CCP_MDPS_SFA_RESP1_Byte7 0;
BA_ "NetworkRequestHoldingTime" SG_ 1669 CCP_MDPS_SFA_RESP1_Byte7 5000;
BA_ "Version" SG_ 1669 CCP_MDPS_SFA_RESP1_Byte7 "23.04.01";
BA_ "UsrSigPurpose" SG_ 1669 CCP_MDPS_SFA_RESP1_Byte1 7;
BA_ "GenSigSendType" SG_ 1669 CCP_MDPS_SFA_RESP1_Byte1 2;
BA_ "UserSigValidity" SG_ 1669 CCP_MDPS_SFA_RESP1_Byte1 0;
BA_ "NetworkRequest" SG_ 1669 CCP_MDPS_SFA_RESP1_Byte1 0;
BA_ "NetworkRequestHoldingTime" SG_ 1669 CCP_MDPS_SFA_RESP1_Byte1 5000;
BA_ "Version" SG_ 1669 CCP_MDPS_SFA_RESP1_Byte1 "23.04.01";
BA_ "Description" SG_ 238 RWA2_Crc1Val "The data area for CRC calculation is based on the data length (DLC) of the message DB.

The CRC shall be calculated over the entire data block (excluding the CRC bytes) including the user data, alive counter and Data ID



- CRC Polynomial (0x1021) , Ini";
BA_ "GenSigStartValue" SG_ 238 RWA2_Crc1Val 65535;
BA_ "UserSigValidity" SG_ 238 RWA2_Crc1Val 3;
BA_ "RoutingFactor" SG_ 238 RWA2_Crc1Val 5;
BA_ "Version" SG_ 238 RWA2_Crc1Val "23.10.03";
BA_ "Description" SG_ 238 RWA_R2_IgnitionStatus "RWA2 IGN Status";
BA_ "UserSigValidity" SG_ 238 RWA_R2_IgnitionStatus 0;
BA_ "RoutingFactor" SG_ 238 RWA_R2_IgnitionStatus 5;
BA_ "Version" SG_ 238 RWA_R2_IgnitionStatus "23.10.03";
BA_ "Description" SG_ 238 RWA_R2_OHP_Status "RWA2 OHP status";
BA_ "UserSigValidity" SG_ 238 RWA_R2_OHP_Status 0;
BA_ "RoutingFactor" SG_ 238 RWA_R2_OHP_Status 5;
BA_ "Version" SG_ 238 RWA_R2_OHP_Status "23.10.03";
BA_ "Description" SG_ 238 RWA_R2_SFA1EcuStatus "SFA1 ECU Status";
BA_ "UserSigValidity" SG_ 238 RWA_R2_SFA1EcuStatus 0;
BA_ "RoutingFactor" SG_ 238 RWA_R2_SFA1EcuStatus 5;
BA_ "Version" SG_ 238 RWA_R2_SFA1EcuStatus "24.01.06";
BA_ "Description" SG_ 238 RWA_R2_SFA2EcuStatus "SFA2 ECU Status";
BA_ "UserSigValidity" SG_ 238 RWA_R2_SFA2EcuStatus 0;
BA_ "RoutingFactor" SG_ 238 RWA_R2_SFA2EcuStatus 5;
BA_ "Version" SG_ 238 RWA_R2_SFA2EcuStatus "24.01.06";
BA_ "Description" SG_ 238 RWA_R2_RWA1EcuStatus "RWA1 ECU Status";
BA_ "UserSigValidity" SG_ 238 RWA_R2_RWA1EcuStatus 0;
BA_ "RoutingFactor" SG_ 238 RWA_R2_RWA1EcuStatus 5;
BA_ "Version" SG_ 238 RWA_R2_RWA1EcuStatus "24.01.06";
BA_ "Description" SG_ 238 RWA_R2_RWA2EcuStatus "RWA2 ECU Status";
BA_ "UserSigValidity" SG_ 238 RWA_R2_RWA2EcuStatus 0;
BA_ "RoutingFactor" SG_ 238 RWA_R2_RWA2EcuStatus 5;
BA_ "Version" SG_ 238 RWA_R2_RWA2EcuStatus "24.01.06";
BA_ "Description" SG_ 238 RWA_R2_CreepReqActSta "RWA2 Creep Request Active Status";
BA_ "UserSigValidity" SG_ 238 RWA_R2_CreepReqActSta 0;
BA_ "RoutingFactor" SG_ 238 RWA_R2_CreepReqActSta 5;
BA_ "Version" SG_ 238 RWA_R2_CreepReqActSta "24.05.03";
BA_ "Description" SG_ 238 RWA_R2_PinionAngSpd "Information regarding the pinion rotation speed 

(PH) = (HEX) * 4 (0 ≤ HEX < 254)";
BA_ "GenSigStartValue" SG_ 238 RWA_R2_PinionAngSpd 255;
BA_ "UserSigValidity" SG_ 238 RWA_R2_PinionAngSpd 0;
BA_ "RoutingFactor" SG_ 238 RWA_R2_PinionAngSpd 5;
BA_ "Version" SG_ 238 RWA_R2_PinionAngSpd "24.04.03";
BA_ "Description" SG_ 238 RWA2_AlvCnt1Val "For the first transmission request for a data element the counter shall be initialized with 0 and shall be incremented by 1 for every subsequent send request. 

When the counter reaches the maximum value(0xFF), then it shall restart with 0 for the next s";
BA_ "UserSigValidity" SG_ 238 RWA2_AlvCnt1Val 3;
BA_ "RoutingFactor" SG_ 238 RWA2_AlvCnt1Val 5;
BA_ "Version" SG_ 238 RWA2_AlvCnt1Val "23.10.03";
BA_ "Description" SG_ 238 RWA_R2_RackForce "RWA2 Rack Force, 0xFFFE : error, phy range : -32700 ~ 32700";
BA_ "UserSigValidity" SG_ 238 RWA_R2_RackForce 0;
BA_ "RoutingFactor" SG_ 238 RWA_R2_RackForce 5;
BA_ "Version" SG_ 238 RWA_R2_RackForce "23.10.03";
BA_ "Description" SG_ 238 RWA_R2_RackPosition "RWA2 Rack Position, 0xFFFFE : error, phy range : -480 ~ 480";
BA_ "UserSigValidity" SG_ 238 RWA_R2_RackPosition 0;
BA_ "RoutingFactor" SG_ 238 RWA_R2_RackPosition 5;
BA_ "Version" SG_ 238 RWA_R2_RackPosition "23.10.03";
BA_ "Description" SG_ 238 RWA_R2_RackSpeed "RWA2 Rack Speed, 0xFFFFE : error, phy range :  -480 ~ 480";
BA_ "UserSigValidity" SG_ 238 RWA_R2_RackSpeed 0;
BA_ "RoutingFactor" SG_ 238 RWA_R2_RackSpeed 5;
BA_ "Version" SG_ 238 RWA_R2_RackSpeed "23.10.03";
BA_ "Description" SG_ 238 RWA_R2_EcuRole "RWA2 ECU Role";
BA_ "UserSigValidity" SG_ 238 RWA_R2_EcuRole 0;
BA_ "RoutingFactor" SG_ 238 RWA_R2_EcuRole 5;
BA_ "Version" SG_ 238 RWA_R2_EcuRole "23.10.03";
BA_ "Description" SG_ 238 RWA_R2_WarningLamp "RWA2 Internal Warning Lamp Flag";
BA_ "UserSigValidity" SG_ 238 RWA_R2_WarningLamp 0;
BA_ "RoutingFactor" SG_ 238 RWA_R2_WarningLamp 5;
BA_ "Version" SG_ 238 RWA_R2_WarningLamp "23.10.03";
BA_ "Description" SG_ 238 RWA_R2_ControlMode "RWA2 Internal Steering Control Mode (Standby, Normal…)";
BA_ "UserSigValidity" SG_ 238 RWA_R2_ControlMode 0;
BA_ "RoutingFactor" SG_ 238 RWA_R2_ControlMode 5;
BA_ "Version" SG_ 238 RWA_R2_ControlMode "24.01.06";
BA_ "Description" SG_ 238 RWA_R2_CenteringStatus "RWA2 Centering and Alignment Status";
BA_ "UserSigValidity" SG_ 238 RWA_R2_CenteringStatus 0;
BA_ "RoutingFactor" SG_ 238 RWA_R2_CenteringStatus 5;
BA_ "Version" SG_ 238 RWA_R2_CenteringStatus "23.10.03";
BA_ "Description" SG_ 238 RWA_R2_OLP "RWA2 OLP Status";
BA_ "UserSigValidity" SG_ 238 RWA_R2_OLP 0;
BA_ "RoutingFactor" SG_ 238 RWA_R2_OLP 5;
BA_ "Version" SG_ 238 RWA_R2_OLP "23.10.03";
BA_ "Description" SG_ 238 RWA_R2_PinionAngle "RWA2 Pinion Angle, 0x7FFF : error";
BA_ "UserSigValidity" SG_ 238 RWA_R2_PinionAngle 0;
BA_ "RoutingFactor" SG_ 238 RWA_R2_PinionAngle 5;
BA_ "Version" SG_ 238 RWA_R2_PinionAngle "24.01.06";
BA_ "Description" SG_ 237 SFA2_Crc1Val "The data area for CRC calculation is based on the data length (DLC) of the message DB.

The CRC shall be calculated over the entire data block (excluding the CRC bytes) including the user data, alive counter and Data ID



- CRC Polynomial (0x1021) , Ini";
BA_ "GenSigStartValue" SG_ 237 SFA2_Crc1Val 65535;
BA_ "UserSigValidity" SG_ 237 SFA2_Crc1Val 3;
BA_ "RoutingFactor" SG_ 237 SFA2_Crc1Val 5;
BA_ "Version" SG_ 237 SFA2_Crc1Val "23.10.03";
BA_ "Description" SG_ 237 SFA_R2_CenteringStatus "SFA2 Centering Status";
BA_ "UserSigValidity" SG_ 237 SFA_R2_CenteringStatus 0;
BA_ "RoutingFactor" SG_ 237 SFA_R2_CenteringStatus 5;
BA_ "Version" SG_ 237 SFA_R2_CenteringStatus "23.10.03";
BA_ "Description" SG_ 237 SbW_R2_CenteringStatus "SbW Centering Status";
BA_ "UserSigValidity" SG_ 237 SbW_R2_CenteringStatus 0;
BA_ "RoutingFactor" SG_ 237 SbW_R2_CenteringStatus 5;
BA_ "Version" SG_ 237 SbW_R2_CenteringStatus "23.10.03";
BA_ "Description" SG_ 237 SFA_R2_IgnitionStatus "SFA2 IgnitionS tatus";
BA_ "UserSigValidity" SG_ 237 SFA_R2_IgnitionStatus 0;
BA_ "RoutingFactor" SG_ 237 SFA_R2_IgnitionStatus 5;
BA_ "Version" SG_ 237 SFA_R2_IgnitionStatus "23.10.03";
BA_ "Description" SG_ 237 SFA_R2_OHP_Status "SFA2 OHP Status";
BA_ "UserSigValidity" SG_ 237 SFA_R2_OHP_Status 0;
BA_ "RoutingFactor" SG_ 237 SFA_R2_OHP_Status 5;
BA_ "Version" SG_ 237 SFA_R2_OHP_Status "23.10.03";
BA_ "Description" SG_ 237 SFA_R2_SFA1EcuStatus "SFA1 Ecu Status";
BA_ "UserSigValidity" SG_ 237 SFA_R2_SFA1EcuStatus 0;
BA_ "RoutingFactor" SG_ 237 SFA_R2_SFA1EcuStatus 5;
BA_ "Version" SG_ 237 SFA_R2_SFA1EcuStatus "24.01.06";
BA_ "Description" SG_ 237 SFA_R2_SFA2EcuStatus "SFA2 Ecu Status";
BA_ "UserSigValidity" SG_ 237 SFA_R2_SFA2EcuStatus 0;
BA_ "RoutingFactor" SG_ 237 SFA_R2_SFA2EcuStatus 5;
BA_ "Version" SG_ 237 SFA_R2_SFA2EcuStatus "24.01.06";
BA_ "Description" SG_ 237 SFA_R2_RWA1EcuStatus "RWA Ecu Status";
BA_ "UserSigValidity" SG_ 237 SFA_R2_RWA1EcuStatus 0;
BA_ "RoutingFactor" SG_ 237 SFA_R2_RWA1EcuStatus 5;
BA_ "Version" SG_ 237 SFA_R2_RWA1EcuStatus "24.01.06";
BA_ "Description" SG_ 237 SFA_R2_RWA2EcuStatus "RWA2 Ecu Status";
BA_ "UserSigValidity" SG_ 237 SFA_R2_RWA2EcuStatus 0;
BA_ "RoutingFactor" SG_ 237 SFA_R2_RWA2EcuStatus 5;
BA_ "Version" SG_ 237 SFA_R2_RWA2EcuStatus "24.01.06";
BA_ "Description" SG_ 237 SFA_R2_SteerWheelAngSpd "Information regarding the steering wheel rotation speed 

(PH) = (HEX) * 4 (0 ≤ HEX < 254)";
BA_ "GenSigStartValue" SG_ 237 SFA_R2_SteerWheelAngSpd 255;
BA_ "UserSigValidity" SG_ 237 SFA_R2_SteerWheelAngSpd 0;
BA_ "RoutingFactor" SG_ 237 SFA_R2_SteerWheelAngSpd 5;
BA_ "Version" SG_ 237 SFA_R2_SteerWheelAngSpd "24.05.03";
BA_ "Description" SG_ 237 SFA2_AlvCnt1Val "For the first transmission request for a data element the counter shall be initialized with 0 and shall be incremented by 1 for every subsequent send request. 

When the counter reaches the maximum value(0xFF), then it shall restart with 0 for the next s";
BA_ "UserSigValidity" SG_ 237 SFA2_AlvCnt1Val 3;
BA_ "RoutingFactor" SG_ 237 SFA2_AlvCnt1Val 5;
BA_ "Version" SG_ 237 SFA2_AlvCnt1Val "23.10.03";
BA_ "Description" SG_ 237 SFA_R2_SteerWheelTorque "SFA2 Steering Wheel Torque, 0xFFE:Error, phy range : -20~20";
BA_ "UserSigValidity" SG_ 237 SFA_R2_SteerWheelTorque 0;
BA_ "RoutingFactor" SG_ 237 SFA_R2_SteerWheelTorque 5;
BA_ "Version" SG_ 237 SFA_R2_SteerWheelTorque "23.10.03";
BA_ "Description" SG_ 237 SFA_R2_SteerWheelAngle "SFA2 Steering Wheel Angle, 0xFFFE:Error, phy range : -655~655";
BA_ "UserSigValidity" SG_ 237 SFA_R2_SteerWheelAngle 0;
BA_ "RoutingFactor" SG_ 237 SFA_R2_SteerWheelAngle 5;
BA_ "Version" SG_ 237 SFA_R2_SteerWheelAngle "23.10.03";
BA_ "Description" SG_ 237 SFA_R2_ControlMode "SFA2 Control Mode stauts";
BA_ "UserSigValidity" SG_ 237 SFA_R2_ControlMode 0;
BA_ "RoutingFactor" SG_ 237 SFA_R2_ControlMode 5;
BA_ "Version" SG_ 237 SFA_R2_ControlMode "24.01.06";
BA_ "Description" SG_ 237 SFA_R2_EcuRole "SFA2 Ecu Role";
BA_ "UserSigValidity" SG_ 237 SFA_R2_EcuRole 0;
BA_ "RoutingFactor" SG_ 237 SFA_R2_EcuRole 5;
BA_ "Version" SG_ 237 SFA_R2_EcuRole "23.10.03";
BA_ "Description" SG_ 237 SFA_R2_WarningLamp "SFA2_Warning Lamp status";
BA_ "UserSigValidity" SG_ 237 SFA_R2_WarningLamp 0;
BA_ "RoutingFactor" SG_ 237 SFA_R2_WarningLamp 5;
BA_ "Version" SG_ 237 SFA_R2_WarningLamp "23.10.03";
BA_ "Description" SG_ 237 SFA_R2_RackCommand "SFA2 Target Rack Position Command, 0x7FFE:Error, phy range : -484~484";
BA_ "UserSigValidity" SG_ 237 SFA_R2_RackCommand 0;
BA_ "RoutingFactor" SG_ 237 SFA_R2_RackCommand 5;
BA_ "Version" SG_ 237 SFA_R2_RackCommand "23.10.03";
BA_ "Description" SG_ 237 SFA_R2_FailoverActvSta "SFA2 Failover Active Status";
BA_ "UserSigValidity" SG_ 237 SFA_R2_FailoverActvSta 0;
BA_ "RoutingFactor" SG_ 237 SFA_R2_FailoverActvSta 5;
BA_ "Version" SG_ 237 SFA_R2_FailoverActvSta "23.10.03";
BA_ "Description" SG_ 237 SFA_R2_BrakeReqActSta "SFA2 Brake Request Active Status";
BA_ "UserSigValidity" SG_ 237 SFA_R2_BrakeReqActSta 0;
BA_ "RoutingFactor" SG_ 237 SFA_R2_BrakeReqActSta 5;
BA_ "Version" SG_ 237 SFA_R2_BrakeReqActSta "23.10.03";
BA_ "Description" SG_ 237 SFA_R2_CreepReqActSta "SFA2 Creep Request Active Status";
BA_ "UserSigValidity" SG_ 237 SFA_R2_CreepReqActSta 0;
BA_ "RoutingFactor" SG_ 237 SFA_R2_CreepReqActSta 5;
BA_ "Version" SG_ 237 SFA_R2_CreepReqActSta "23.10.10";
BA_ "Description" SG_ 237 SbW_R2_EvDrvRdyEnb "SFA2 Shift Lock Requst Active Status";
BA_ "UserSigValidity" SG_ 237 SbW_R2_EvDrvRdyEnb 0;
BA_ "RoutingFactor" SG_ 237 SbW_R2_EvDrvRdyEnb 5;
BA_ "Version" SG_ 237 SbW_R2_EvDrvRdyEnb "24.04.01";
BA_ "Description" SG_ 237 SFA_R2_CluWarningLamp "SFA2 Cluster Warning Lamp status";
BA_ "UserSigValidity" SG_ 237 SFA_R2_CluWarningLamp 3;
BA_ "RoutingFactor" SG_ 237 SFA_R2_CluWarningLamp 5;
BA_ "Version" SG_ 237 SFA_R2_CluWarningLamp "23.10.03";
BA_ "Description" SG_ 237 SFA_R2_CluWarningSentence "SFA2-Cluster Warning Sentence";
BA_ "UserSigValidity" SG_ 237 SFA_R2_CluWarningSentence 3;
BA_ "RoutingFactor" SG_ 237 SFA_R2_CluWarningSentence 5;
BA_ "Version" SG_ 237 SFA_R2_CluWarningSentence "24.04.06";
BA_ "UsrSigPurpose" SG_ 1671 CCP_MDPS_RWA_RESP3_Byte0 7;
BA_ "GenSigSendType" SG_ 1671 CCP_MDPS_RWA_RESP3_Byte0 2;
BA_ "UserSigValidity" SG_ 1671 CCP_MDPS_RWA_RESP3_Byte0 0;
BA_ "NetworkRequest" SG_ 1671 CCP_MDPS_RWA_RESP3_Byte0 0;
BA_ "NetworkRequestHoldingTime" SG_ 1671 CCP_MDPS_RWA_RESP3_Byte0 5000;
BA_ "Version" SG_ 1671 CCP_MDPS_RWA_RESP3_Byte0 "23.04.01";
BA_ "UsrSigPurpose" SG_ 1671 CCP_MDPS_RWA_RESP3_Byte2 7;
BA_ "GenSigSendType" SG_ 1671 CCP_MDPS_RWA_RESP3_Byte2 2;
BA_ "UserSigValidity" SG_ 1671 CCP_MDPS_RWA_RESP3_Byte2 0;
BA_ "NetworkRequest" SG_ 1671 CCP_MDPS_RWA_RESP3_Byte2 0;
BA_ "NetworkRequestHoldingTime" SG_ 1671 CCP_MDPS_RWA_RESP3_Byte2 5000;
BA_ "Version" SG_ 1671 CCP_MDPS_RWA_RESP3_Byte2 "23.04.01";
BA_ "UsrSigPurpose" SG_ 1671 CCP_MDPS_RWA_RESP3_Byte3 7;
BA_ "GenSigSendType" SG_ 1671 CCP_MDPS_RWA_RESP3_Byte3 2;
BA_ "UserSigValidity" SG_ 1671 CCP_MDPS_RWA_RESP3_Byte3 0;
BA_ "NetworkRequest" SG_ 1671 CCP_MDPS_RWA_RESP3_Byte3 0;
BA_ "NetworkRequestHoldingTime" SG_ 1671 CCP_MDPS_RWA_RESP3_Byte3 5000;
BA_ "Version" SG_ 1671 CCP_MDPS_RWA_RESP3_Byte3 "23.04.01";
BA_ "UsrSigPurpose" SG_ 1671 CCP_MDPS_RWA_RESP3_Byte4 7;
BA_ "GenSigSendType" SG_ 1671 CCP_MDPS_RWA_RESP3_Byte4 2;
BA_ "UserSigValidity" SG_ 1671 CCP_MDPS_RWA_RESP3_Byte4 0;
BA_ "NetworkRequest" SG_ 1671 CCP_MDPS_RWA_RESP3_Byte4 0;
BA_ "NetworkRequestHoldingTime" SG_ 1671 CCP_MDPS_RWA_RESP3_Byte4 5000;
BA_ "Version" SG_ 1671 CCP_MDPS_RWA_RESP3_Byte4 "23.04.01";
BA_ "UsrSigPurpose" SG_ 1671 CCP_MDPS_RWA_RESP3_Byte5 7;
BA_ "GenSigSendType" SG_ 1671 CCP_MDPS_RWA_RESP3_Byte5 2;
BA_ "UserSigValidity" SG_ 1671 CCP_MDPS_RWA_RESP3_Byte5 0;
BA_ "NetworkRequest" SG_ 1671 CCP_MDPS_RWA_RESP3_Byte5 0;
BA_ "NetworkRequestHoldingTime" SG_ 1671 CCP_MDPS_RWA_RESP3_Byte5 5000;
BA_ "Version" SG_ 1671 CCP_MDPS_RWA_RESP3_Byte5 "23.04.01";
BA_ "UsrSigPurpose" SG_ 1671 CCP_MDPS_RWA_RESP3_Byte6 7;
BA_ "GenSigSendType" SG_ 1671 CCP_MDPS_RWA_RESP3_Byte6 2;
BA_ "UserSigValidity" SG_ 1671 CCP_MDPS_RWA_RESP3_Byte6 0;
BA_ "NetworkRequest" SG_ 1671 CCP_MDPS_RWA_RESP3_Byte6 0;
BA_ "NetworkRequestHoldingTime" SG_ 1671 CCP_MDPS_RWA_RESP3_Byte6 5000;
BA_ "Version" SG_ 1671 CCP_MDPS_RWA_RESP3_Byte6 "23.04.01";
BA_ "UsrSigPurpose" SG_ 1671 CCP_MDPS_RWA_RESP3_Byte7 7;
BA_ "GenSigSendType" SG_ 1671 CCP_MDPS_RWA_RESP3_Byte7 2;
BA_ "UserSigValidity" SG_ 1671 CCP_MDPS_RWA_RESP3_Byte7 0;
BA_ "NetworkRequest" SG_ 1671 CCP_MDPS_RWA_RESP3_Byte7 0;
BA_ "NetworkRequestHoldingTime" SG_ 1671 CCP_MDPS_RWA_RESP3_Byte7 5000;
BA_ "Version" SG_ 1671 CCP_MDPS_RWA_RESP3_Byte7 "23.04.01";
BA_ "UsrSigPurpose" SG_ 1671 CCP_MDPS_RWA_RESP3_Byte1 7;
BA_ "GenSigSendType" SG_ 1671 CCP_MDPS_RWA_RESP3_Byte1 2;
BA_ "UserSigValidity" SG_ 1671 CCP_MDPS_RWA_RESP3_Byte1 0;
BA_ "NetworkRequest" SG_ 1671 CCP_MDPS_RWA_RESP3_Byte1 0;
BA_ "NetworkRequestHoldingTime" SG_ 1671 CCP_MDPS_RWA_RESP3_Byte1 5000;
BA_ "Version" SG_ 1671 CCP_MDPS_RWA_RESP3_Byte1 "23.04.01";
BA_ "Description" SG_ 234 MDPS_Crc1Val "The data area for CRC calculation is based on the data length (DLC) of the message DB.

The CRC shall be calculated over the entire data block (excluding the CRC bytes) including the user data, alive counter and Data ID

 

- CRC Polynomial (0x1021) , In";
BA_ "GenSigStartValue" SG_ 234 MDPS_Crc1Val 65535;
BA_ "UserSigValidity" SG_ 234 MDPS_Crc1Val 3;
BA_ "RoutingFactor" SG_ 234 MDPS_Crc1Val 5;
BA_ "Version" SG_ 234 MDPS_Crc1Val "18.11.08";
BA_ "Description" SG_ 234 MDPS_LoamModSta "The signal represent status of the LOAM(Loss Of Assist Mitigation) Mode";
BA_ "UserSigValidity" SG_ 234 MDPS_LoamModSta 3;
BA_ "RoutingFactor" SG_ 234 MDPS_LoamModSta 5;
BA_ "Version" SG_ 234 MDPS_LoamModSta "21.10.03";
BA_ "Description" SG_ 234 MDPS_HDPSpprtSWVer "This signal indicates HDP-MDPS Control Requirement Spec Version";
BA_ "UserSigValidity" SG_ 234 MDPS_HDPSpprtSWVer 3;
BA_ "RoutingFactor" SG_ 234 MDPS_HDPSpprtSWVer 5;
BA_ "Version" SG_ 234 MDPS_HDPSpprtSWVer "21.11.00";
BA_ "Description" SG_ 234 MDPS_ADASAciActvSta "State for angle control";
BA_ "UserSigValidity" SG_ 234 MDPS_ADASAciActvSta 3;
BA_ "RoutingFactor" SG_ 234 MDPS_ADASAciActvSta 5;
BA_ "Version" SG_ 234 MDPS_ADASAciActvSta "22.01.00";
BA_ "Description" SG_ 234 MDPS_ADASAciPluginSta "This signal indicates whether the ADASAci function of MDPS is plugged in or not.";
BA_ "UserSigValidity" SG_ 234 MDPS_ADASAciPluginSta 3;
BA_ "RoutingFactor" SG_ 234 MDPS_ADASAciPluginSta 5;
BA_ "Version" SG_ 234 MDPS_ADASAciPluginSta "21.10.03";
BA_ "Description" SG_ 234 MDPS_ADAS_AciFltSig "MDPS Fault Status for HDP Function";
BA_ "UserSigValidity" SG_ 234 MDPS_ADAS_AciFltSig 3;
BA_ "RoutingFactor" SG_ 234 MDPS_ADAS_AciFltSig 5;
BA_ "Version" SG_ 234 MDPS_ADAS_AciFltSig "21.03.10";
BA_ "Description" SG_ 234 MDPS_EstStrAnglVal "This value is used to inform of a compensated steering wheel angle by MDPS . The signal is signed 16bits, and made by motor position sensor. 



(PH) = (HEX) × 0.1 (for 0 < HEX ≤ 32767)  or

= (HEX - 65536) × 0.1 (for HEX > 32767) [Deg]



this signal";
BA_ "GenSigStartValue" SG_ 234 MDPS_EstStrAnglVal 32767;
BA_ "UserSigValidity" SG_ 234 MDPS_EstStrAnglVal 3;
BA_ "RoutingFactor" SG_ 234 MDPS_EstStrAnglVal 5;
BA_ "Version" SG_ 234 MDPS_EstStrAnglVal "21.10.03";
BA_ "Description" SG_ 234 MDPS_ADASAciActvSta_Lv2 "States for angle control (LV2)";
BA_ "UserSigValidity" SG_ 234 MDPS_ADASAciActvSta_Lv2 3;
BA_ "RoutingFactor" SG_ 234 MDPS_ADASAciActvSta_Lv2 5;
BA_ "Version" SG_ 234 MDPS_ADASAciActvSta_Lv2 "21.11.00";
BA_ "Description" SG_ 234 MDPS_ADAS_AciFltSig_Lv2 "MDPS Fault Status for LV2 Angle Control Function";
BA_ "UserSigValidity" SG_ 234 MDPS_ADAS_AciFltSig_Lv2 3;
BA_ "RoutingFactor" SG_ 234 MDPS_ADAS_AciFltSig_Lv2 5;
BA_ "Version" SG_ 234 MDPS_ADAS_AciFltSig_Lv2 "21.11.00";
BA_ "Description" SG_ 234 MDPS_TpaPlugInSta "This signal indicates whether the TPA function of MDPS is plugged in or not.";
BA_ "UserSigValidity" SG_ 234 MDPS_TpaPlugInSta 3;
BA_ "RoutingFactor" SG_ 234 MDPS_TpaPlugInSta 5;
BA_ "Version" SG_ 234 MDPS_TpaPlugInSta "22.03.03";
BA_ "Description" SG_ 234 MDPS_TpaCanfltSta "※ This Signal should be used by only TPA

This signal indicates whether the MDPS is defective in TPA cooperation control. 

This signal is set as '1' only when MDPS Detects CAN Failure(TIMEOUT, Signal Error) of TPA CAN Message";
BA_ "UserSigValidity" SG_ 234 MDPS_TpaCanfltSta 3;
BA_ "RoutingFactor" SG_ 234 MDPS_TpaCanfltSta 5;
BA_ "Version" SG_ 234 MDPS_TpaCanfltSta "22.03.03";
BA_ "Description" SG_ 234 MDPS_TpaModeSta "This signal indicates the status of the TPA steering function.";
BA_ "GenSigStartValue" SG_ 234 MDPS_TpaModeSta 1;
BA_ "UserSigValidity" SG_ 234 MDPS_TpaModeSta 3;
BA_ "RoutingFactor" SG_ 234 MDPS_TpaModeSta 5;
BA_ "Version" SG_ 234 MDPS_TpaModeSta "23.04.05";
BA_ "Description" SG_ 234 MDPS_AlvCnt1Val "For the first transmission request for a data element the counter shall be initialized with 0 and shall be incremented by 1 for every subsequent send request. 

When the counter reaches the maximum value(0xFF), then it shall restart with 0 for the next s";
BA_ "UserSigValidity" SG_ 234 MDPS_AlvCnt1Val 3;
BA_ "RoutingFactor" SG_ 234 MDPS_AlvCnt1Val 5;
BA_ "Version" SG_ 234 MDPS_AlvCnt1Val "18.11.08";
BA_ "Description" SG_ 234 MDPS_TpaStrAnglVal "This value is used to inform TPA of a compensated steering wheel angle by MDPS. The signal is signed 16bits.



(PH) = (HEX) × 0.1 (for 0 < HEX ≤ 32767)  or

= (HEX - 65536) × 0.1 (for HEX > 32767) [Deg]";
BA_ "GenSigStartValue" SG_ 234 MDPS_TpaStrAnglVal 32767;
BA_ "UserSigValidity" SG_ 234 MDPS_TpaStrAnglVal 3;
BA_ "RoutingFactor" SG_ 234 MDPS_TpaStrAnglVal 5;
BA_ "Version" SG_ 234 MDPS_TpaStrAnglVal "23.04.05";
BA_ "Description" SG_ 234 MDPS_WrngLmpSta "The signal indicates the ststus of the “MDPS Warning lamp”";
BA_ "UserSigValidity" SG_ 234 MDPS_WrngLmpSta 3;
BA_ "RoutingFactor" SG_ 234 MDPS_WrngLmpSta 5;
BA_ "Version" SG_ 234 MDPS_WrngLmpSta "21.10.03";
BA_ "Description" SG_ 234 MDPS_Typ "Information regarding the type of MDPS. (C-MDPS / R-MDPS / SbW)";
BA_ "UserSigValidity" SG_ 234 MDPS_Typ 3;
BA_ "RoutingFactor" SG_ 234 MDPS_Typ 5;
BA_ "Version" SG_ 234 MDPS_Typ "23.07.04";
BA_ "Description" SG_ 234 MDPS_EngIdleRpmReq "This signal indicates the request status for engine idle rpm up according to MDPS fast rotation.";
BA_ "UserSigValidity" SG_ 234 MDPS_EngIdleRpmReq 3;
BA_ "RoutingFactor" SG_ 234 MDPS_EngIdleRpmReq 5;
BA_ "Version" SG_ 234 MDPS_EngIdleRpmReq "21.10.03";
BA_ "Description" SG_ 234 MDPS_VsmPlgInSta "This signal indicates whether the VSM function of MDPS is plugged in or not.";
BA_ "UserSigValidity" SG_ 234 MDPS_VsmPlgInSta 3;
BA_ "RoutingFactor" SG_ 234 MDPS_VsmPlgInSta 5;
BA_ "Version" SG_ 234 MDPS_VsmPlgInSta "21.10.03";
BA_ "Description" SG_ 234 MDPS_VsmDfctvSta "Information regarding the MDPS “defective” Indication For VSM";
BA_ "UserSigValidity" SG_ 234 MDPS_VsmDfctvSta 3;
BA_ "RoutingFactor" SG_ 234 MDPS_VsmDfctvSta 5;
BA_ "Version" SG_ 234 MDPS_VsmDfctvSta "21.10.03";
BA_ "Description" SG_ 234 MDPS_VsmSigErrSta "Information indicating VSM signal status";
BA_ "UserSigValidity" SG_ 234 MDPS_VsmSigErrSta 3;
BA_ "RoutingFactor" SG_ 234 MDPS_VsmSigErrSta 5;
BA_ "Version" SG_ 234 MDPS_VsmSigErrSta "21.10.03";
BA_ "Description" SG_ 234 MDPS_PaPlugInSta "This signal indicates whether the PA function of MDPS is plugged in or not.";
BA_ "UserSigValidity" SG_ 234 MDPS_PaPlugInSta 3;
BA_ "RoutingFactor" SG_ 234 MDPS_PaPlugInSta 5;
BA_ "Version" SG_ 234 MDPS_PaPlugInSta "21.10.03";
BA_ "Description" SG_ 234 MDPS_PaModeSta "This signal indicates the status of the PA steering function.";
BA_ "GenSigStartValue" SG_ 234 MDPS_PaModeSta 1;
BA_ "UserSigValidity" SG_ 234 MDPS_PaModeSta 3;
BA_ "RoutingFactor" SG_ 234 MDPS_PaModeSta 5;
BA_ "Version" SG_ 234 MDPS_PaModeSta "23.04.05";
BA_ "Description" SG_ 234 MDPS_PaCanfltSta "※ This Signal should be used by only PA

This signal indicates whether the MDPS is defective in PA cooperation control. 

This signal is set as '1' only when MDPS Detects CAN Failure(TIMEOUT, Signal Error) of PA CAN Message";
BA_ "UserSigValidity" SG_ 234 MDPS_PaCanfltSta 3;
BA_ "RoutingFactor" SG_ 234 MDPS_PaCanfltSta 5;
BA_ "Version" SG_ 234 MDPS_PaCanfltSta "21.10.03";
BA_ "Description" SG_ 234 MDPS_LkaPlgInSta "This signal indicates whether the LKA function of MDPS is plugged in or not.";
BA_ "UserSigValidity" SG_ 234 MDPS_LkaPlgInSta 3;
BA_ "RoutingFactor" SG_ 234 MDPS_LkaPlgInSta 5;
BA_ "Version" SG_ 234 MDPS_LkaPlgInSta "21.10.03";
BA_ "Description" SG_ 234 MDPS_LkaToiActvSta "This flag is set to 1 in response to the LKA Controller requesting the activation of the torque interface and set back to 0 in response to the LKA Controller requesting the de-activation of the torque interface.";
BA_ "UserSigValidity" SG_ 234 MDPS_LkaToiActvSta 3;
BA_ "RoutingFactor" SG_ 234 MDPS_LkaToiActvSta 5;
BA_ "Version" SG_ 234 MDPS_LkaToiActvSta "21.10.03";
BA_ "Description" SG_ 234 MDPS_LkaToiUnblSta "This is a flag that is set when the MDPS is not faulty, but is temporarily unable to activate the TOI due to steering torque limiting e.g. when the supply voltage is too low.";
BA_ "UserSigValidity" SG_ 234 MDPS_LkaToiUnblSta 3;
BA_ "RoutingFactor" SG_ 234 MDPS_LkaToiUnblSta 5;
BA_ "Version" SG_ 234 MDPS_LkaToiUnblSta "21.10.03";
BA_ "Description" SG_ 234 MDPS_LkaToiFltSta "This fault flag is set when a fault within the MDPS system has been detected such that the LKA TOI can no longer function. CAN failures, internal MDPS failures, and LKA controller logic failures are all reported by this flag. Failures reported by the LKA";
BA_ "UserSigValidity" SG_ 234 MDPS_LkaToiFltSta 3;
BA_ "RoutingFactor" SG_ 234 MDPS_LkaToiFltSta 5;
BA_ "Version" SG_ 234 MDPS_LkaToiFltSta "21.10.03";
BA_ "Description" SG_ 234 MDPS_LkaFailSta "This fault flag is set whilst the MDPS TOI is in a fail state and has not yet recovered from it. This could either be due to an MDPS detected fault (as communicated by the ‘MDPS_LkaToiFltSta' flag) or an LKA detected fault (as communicated by the ‘LKA_";
BA_ "UserSigValidity" SG_ 234 MDPS_LkaFailSta 3;
BA_ "RoutingFactor" SG_ 234 MDPS_LkaFailSta 5;
BA_ "Version" SG_ 234 MDPS_LkaFailSta "21.10.03";
BA_ "Description" SG_ 234 MDPS_ResetOpSta "Information regarding the state of reset";
BA_ "UserSigValidity" SG_ 234 MDPS_ResetOpSta 0;
BA_ "RoutingFactor" SG_ 234 MDPS_ResetOpSta 5;
BA_ "Version" SG_ 234 MDPS_ResetOpSta "24.04.03";
BA_ "Description" SG_ 234 MDPS_CurrModVal "This signal indicates flex steer parameter value in MDPS.



※ For information about flex steer mode set by user, refer to MDPS_FlxStrSta signal.";
BA_ "UserSigValidity" SG_ 234 MDPS_CurrModVal 3;
BA_ "RoutingFactor" SG_ 234 MDPS_CurrModVal 5;
BA_ "Version" SG_ 234 MDPS_CurrModVal "23.02.01";
BA_ "Description" SG_ 234 MDPS_OutTqVal "MDPS column torque

this signal has direction information.

'+' Value means Counter clock wise rotation.

'-' value means Clock wise rotation.";
BA_ "GenSigStartValue" SG_ 234 MDPS_OutTqVal 2048;
BA_ "UserSigValidity" SG_ 234 MDPS_OutTqVal 3;
BA_ "RoutingFactor" SG_ 234 MDPS_OutTqVal 5;
BA_ "Version" SG_ 234 MDPS_OutTqVal "21.10.03";
BA_ "Description" SG_ 234 MDPS_VsmActResp "Information of VSM Tqrque Intervention Act Response";
BA_ "UserSigValidity" SG_ 234 MDPS_VsmActResp 3;
BA_ "RoutingFactor" SG_ 234 MDPS_VsmActResp 5;
BA_ "Version" SG_ 234 MDPS_VsmActResp "21.10.03";
BA_ "Description" SG_ 234 Reprogram_State_MDPS "Information regarding the reprogram state";
BA_ "GenSigStartValue" SG_ 234 Reprogram_State_MDPS 3;
BA_ "UserSigValidity" SG_ 234 Reprogram_State_MDPS 0;
BA_ "RoutingFactor" SG_ 234 Reprogram_State_MDPS 5;
BA_ "Version" SG_ 234 Reprogram_State_MDPS "24.04.07";
BA_ "Description" SG_ 234 MDPS_StrTqSnsrVal "Steering torque sensor value



Physical Value > 0: Left Direction (CCW)

Physical Value < 0: Right Direction (CW)



this signal has direction information.

'+' Value means Counter clock wise rotation.

'-' value means Clock wise rotation.";
BA_ "GenSigStartValue" SG_ 234 MDPS_StrTqSnsrVal 4096;
BA_ "UserSigValidity" SG_ 234 MDPS_StrTqSnsrVal 3;
BA_ "RoutingFactor" SG_ 234 MDPS_StrTqSnsrVal 5;
BA_ "Version" SG_ 234 MDPS_StrTqSnsrVal "21.10.03";
BA_ "Description" SG_ 234 MDPS_PaStrAnglVal "This value is used to inform PA of a compensated steering wheel angle by MDPS. The signal is signed 16bits.



(PH) = (HEX) × 0.1 (for 0 < HEX ≤ 32767)  or

= (HEX - 65536) × 0.1 (for HEX > 32767) [Deg]



this signal has direction information.

'+' V";
BA_ "GenSigStartValue" SG_ 234 MDPS_PaStrAnglVal 32767;
BA_ "UserSigValidity" SG_ 234 MDPS_PaStrAnglVal 3;
BA_ "RoutingFactor" SG_ 234 MDPS_PaStrAnglVal 5;
BA_ "Version" SG_ 234 MDPS_PaStrAnglVal "23.04.05";
BA_REL_ "GenSigTimeoutTime" BU_SG_REL_ GW_RGW SG_ 0 WakeUp_DoorLock_DrvDrUnLkSta 0;
BA_REL_ "GenSigTimeoutTime" BU_SG_REL_ RWA SG_ 0 WakeUp_DoorLock_DrvDrUnLkSta 0;
BA_REL_ "GenSigTimeoutTime" BU_SG_REL_ SFA SG_ 0 WakeUp_DoorLock_DrvDrUnLkSta 0;
BA_REL_ "GenSigTimeoutTime" BU_SG_REL_ GW_RGW SG_ 0 WakeUp_DoorLock_AsstDrUnLkSta 0;
BA_REL_ "GenSigTimeoutTime" BU_SG_REL_ RWA SG_ 0 WakeUp_DoorLock_AsstDrUnLkSta 0;
BA_REL_ "GenSigTimeoutTime" BU_SG_REL_ SFA SG_ 0 WakeUp_DoorLock_AsstDrUnLkSta 0;
BA_REL_ "GenSigTimeoutTime" BU_SG_REL_ GW_RGW SG_ 0 WakeUp_Warn_AsstDrSwSta 0;
BA_REL_ "GenSigTimeoutTime" BU_SG_REL_ RWA SG_ 0 WakeUp_Warn_AsstDrSwSta 0;
BA_REL_ "GenSigTimeoutTime" BU_SG_REL_ SFA SG_ 0 WakeUp_Warn_AsstDrSwSta 0;
BA_REL_ "GenSigTimeoutTime" BU_SG_REL_ GW_RGW SG_ 0 WakeUp_Warn_DrvDrSwSta 0;
BA_REL_ "GenSigTimeoutTime" BU_SG_REL_ RWA SG_ 0 WakeUp_Warn_DrvDrSwSta 0;
BA_REL_ "GenSigTimeoutTime" BU_SG_REL_ SFA SG_ 0 WakeUp_Warn_DrvDrSwSta 0;
BA_REL_ "GenSigTimeoutTime" BU_SG_REL_ RWA SG_ 548 ALDC_Crc1Val 1500;
BA_REL_ "GenSigTimeoutTime" BU_SG_REL_ SFA SG_ 548 ALDC_Crc1Val 1500;
BA_REL_ "GenSigTimeoutTime" BU_SG_REL_ RWA SG_ 548 ALDC_AlvCnt1Val 1500;
BA_REL_ "GenSigTimeoutTime" BU_SG_REL_ SFA SG_ 548 ALDC_AlvCnt1Val 1500;
BA_REL_ "GenSigTimeoutTime" BU_SG_REL_ RWA SG_ 548 ALDC_SysOpSta 1500;
BA_REL_ "GenSigTimeoutTime" BU_SG_REL_ SFA SG_ 548 ALDC_SysOpSta 1500;
BA_REL_ "GenSigTimeoutTime" BU_SG_REL_ RWA SG_ 548 ALDC_SysFltSta 1500;
BA_REL_ "GenSigTimeoutTime" BU_SG_REL_ SFA SG_ 548 ALDC_SysFltSta 1500;
BA_REL_ "GenSigTimeoutTime" BU_SG_REL_ BDC_C SG_ 549 CLU_Crc2Val 1500;
BA_REL_ "GenSigTimeoutTime" BU_SG_REL_ ESC SG_ 549 CLU_Crc2Val 1500;
BA_REL_ "GenSigTimeoutTime" BU_SG_REL_ GW_RGW SG_ 549 CLU_Crc2Val 1500;
BA_REL_ "GenSigTimeoutTime" BU_SG_REL_ ICSC SG_ 549 CLU_Crc2Val 1500;
BA_REL_ "GenSigTimeoutTime" BU_SG_REL_ MDPS SG_ 549 CLU_Crc2Val 1500;
BA_REL_ "GenSigTimeoutTime" BU_SG_REL_ RCU SG_ 549 CLU_Crc2Val 1500;
BA_REL_ "GenSigTimeoutTime" BU_SG_REL_ SFA SG_ 549 CLU_Crc2Val 1500;
BA_REL_ "GenSigTimeoutTime" BU_SG_REL_ VPC_C SG_ 549 CLU_Crc2Val 1500;
BA_REL_ "GenSigTimeoutTime" BU_SG_REL_ ECS SG_ 549 CLU_DrvngModSwSta 1500;
BA_REL_ "GenSigTimeoutTime" BU_SG_REL_ ESC SG_ 549 CLU_DrvngModSwSta 1500;
BA_REL_ "GenSigTimeoutTime" BU_SG_REL_ GW_RGW SG_ 549 CLU_DrvngModSwSta 1500;
BA_REL_ "GenSigTimeoutTime" BU_SG_REL_ ICSC SG_ 549 CLU_DrvngModSwSta 1500;
BA_REL_ "GenSigTimeoutTime" BU_SG_REL_ MDPS SG_ 549 CLU_DrvngModSwSta 1500;
BA_REL_ "GenSigTimeoutTime" BU_SG_REL_ RCU SG_ 549 CLU_DrvngModSwSta 1500;
BA_REL_ "GenSigTimeoutTime" BU_SG_REL_ SFA SG_ 549 CLU_DrvngModSwSta 1500;
BA_REL_ "GenSigTimeoutTime" BU_SG_REL_ VPC_C SG_ 549 CLU_DrvngModSwSta 1500;
BA_REL_ "GenSigTimeoutTime" BU_SG_REL_ BDC_C SG_ 549 CLU_AlvCnt2Val 1500;
BA_REL_ "GenSigTimeoutTime" BU_SG_REL_ ESC SG_ 549 CLU_AlvCnt2Val 1500;
BA_REL_ "GenSigTimeoutTime" BU_SG_REL_ GW_RGW SG_ 549 CLU_AlvCnt2Val 1500;
BA_REL_ "GenSigTimeoutTime" BU_SG_REL_ ICSC SG_ 549 CLU_AlvCnt2Val 1500;
BA_REL_ "GenSigTimeoutTime" BU_SG_REL_ MDPS SG_ 549 CLU_AlvCnt2Val 1500;
BA_REL_ "GenSigTimeoutTime" BU_SG_REL_ RCU SG_ 549 CLU_AlvCnt2Val 1500;
BA_REL_ "GenSigTimeoutTime" BU_SG_REL_ SFA SG_ 549 CLU_AlvCnt2Val 1500;
BA_REL_ "GenSigTimeoutTime" BU_SG_REL_ VPC_C SG_ 549 CLU_AlvCnt2Val 1500;
BA_REL_ "GenSigTimeoutTime" BU_SG_REL_ CGW_CCU SG_ 517 ICSC_Crc2Val 1500;
BA_REL_ "GenSigTimeoutTime" BU_SG_REL_ ECS SG_ 517 ICSC_Crc2Val 1500;
BA_REL_ "GenSigTimeoutTime" BU_SG_REL_ ESC SG_ 517 ICSC_Crc2Val 1500;
BA_REL_ "GenSigTimeoutTime" BU_SG_REL_ GW_RGW SG_ 517 ICSC_Crc2Val 1500;
BA_REL_ "GenSigTimeoutTime" BU_SG_REL_ RCU SG_ 517 ICSC_Crc2Val 1500;
BA_REL_ "GenSigTimeoutTime" BU_SG_REL_ RWS SG_ 517 ICSC_Crc2Val 1500;
BA_REL_ "GenSigTimeoutTime" BU_SG_REL_ SFA SG_ 517 ICSC_Crc2Val 1500;
BA_REL_ "GenSigTimeoutTime" BU_SG_REL_ VPC_C SG_ 517 ICSC_Crc2Val 1500;
BA_REL_ "GenSigTimeoutTime" BU_SG_REL_ CGW_CCU SG_ 517 ICSC_AlvCnt2Val 1500;
BA_REL_ "GenSigTimeoutTime" BU_SG_REL_ ECS SG_ 517 ICSC_AlvCnt2Val 1500;
BA_REL_ "GenSigTimeoutTime" BU_SG_REL_ ESC SG_ 517 ICSC_AlvCnt2Val 1500;
BA_REL_ "GenSigTimeoutTime" BU_SG_REL_ GW_RGW SG_ 517 ICSC_AlvCnt2Val 1500;
BA_REL_ "GenSigTimeoutTime" BU_SG_REL_ RCU SG_ 517 ICSC_AlvCnt2Val 1500;
BA_REL_ "GenSigTimeoutTime" BU_SG_REL_ RWS SG_ 517 ICSC_AlvCnt2Val 1500;
BA_REL_ "GenSigTimeoutTime" BU_SG_REL_ SFA SG_ 517 ICSC_AlvCnt2Val 1500;
BA_REL_ "GenSigTimeoutTime" BU_SG_REL_ VPC_C SG_ 517 ICSC_AlvCnt2Val 1500;
BA_REL_ "GenSigTimeoutTime" BU_SG_REL_ GW_RGW SG_ 517 DMIC_MdpsModSta 1500;
BA_REL_ "GenSigTimeoutTime" BU_SG_REL_ MDPS SG_ 517 DMIC_MdpsModSta 1500;
BA_REL_ "GenSigTimeoutTime" BU_SG_REL_ SFA SG_ 517 DMIC_MdpsModSta 1500;
BA_REL_ "GenSigTimeoutTime" BU_SG_REL_ GW_RGW SG_ 520 HOD_FD_Crc1Val 1500;
BA_REL_ "GenSigTimeoutTime" BU_SG_REL_ SFA SG_ 520 HOD_FD_Crc1Val 1500;
BA_REL_ "GenSigTimeoutTime" BU_SG_REL_ GW_RGW SG_ 520 HOD_FD_AlvCnt1Val 1500;
BA_REL_ "GenSigTimeoutTime" BU_SG_REL_ SFA SG_ 520 HOD_FD_AlvCnt1Val 1500;
BA_REL_ "GenSigTimeoutTime" BU_SG_REL_ GW_RGW SG_ 520 HOD_Dir_Status 1500;
BA_REL_ "GenSigTimeoutTime" BU_SG_REL_ SFA SG_ 520 HOD_Dir_Status 1500;
BA_REL_ "GenSigTimeoutTime" BU_SG_REL_ GW_RGW SG_ 520 HOD_Option 1500;
BA_REL_ "GenSigTimeoutTime" BU_SG_REL_ SFA SG_ 520 HOD_Option 1500;
BA_REL_ "GenSigTimeoutTime" BU_SG_REL_ RWA SG_ 597 LDC_Crc1Val 1500;
BA_REL_ "GenSigTimeoutTime" BU_SG_REL_ SFA SG_ 597 LDC_Crc1Val 1500;
BA_REL_ "GenSigTimeoutTime" BU_SG_REL_ RWA SG_ 597 LDC_AlvCnt1Val 1500;
BA_REL_ "GenSigTimeoutTime" BU_SG_REL_ SFA SG_ 597 LDC_AlvCnt1Val 1500;
BA_REL_ "GenSigTimeoutTime" BU_SG_REL_ RWA SG_ 597 LDC_SysOpSta 1500;
BA_REL_ "GenSigTimeoutTime" BU_SG_REL_ SFA SG_ 597 LDC_SysOpSta 1500;
BA_REL_ "GenSigTimeoutTime" BU_SG_REL_ RWA SG_ 597 LDC_SysFltSta 1500;
BA_REL_ "GenSigTimeoutTime" BU_SG_REL_ SFA SG_ 597 LDC_SysFltSta 1500;
BA_REL_ "GenSigTimeoutTime" BU_SG_REL_ ESC SG_ 647 CCU_update_enable 1500;
BA_REL_ "GenSigTimeoutTime" BU_SG_REL_ GW_RGW SG_ 647 CCU_update_enable 1500;
BA_REL_ "GenSigTimeoutTime" BU_SG_REL_ MDPS SG_ 647 CCU_update_enable 1500;
BA_REL_ "GenSigTimeoutTime" BU_SG_REL_ RWA SG_ 647 CCU_update_enable 1500;
BA_REL_ "GenSigTimeoutTime" BU_SG_REL_ SFA SG_ 647 CCU_update_enable 1500;
BA_REL_ "GenSigTimeoutTime" BU_SG_REL_ ABS SG_ 745 PDC_FD_Crc15Val 1500;
BA_REL_ "GenSigTimeoutTime" BU_SG_REL_ EBB SG_ 745 PDC_FD_Crc15Val 1500;
BA_REL_ "GenSigTimeoutTime" BU_SG_REL_ ECS SG_ 745 PDC_FD_Crc15Val 1500;
BA_REL_ "GenSigTimeoutTime" BU_SG_REL_ EPB SG_ 745 PDC_FD_Crc15Val 1500;
BA_REL_ "GenSigTimeoutTime" BU_SG_REL_ ESC SG_ 745 PDC_FD_Crc15Val 1500;
BA_REL_ "GenSigTimeoutTime" BU_SG_REL_ GW_RGW SG_ 745 PDC_FD_Crc15Val 1500;
BA_REL_ "GenSigTimeoutTime" BU_SG_REL_ ICSC SG_ 745 PDC_FD_Crc15Val 1500;
BA_REL_ "GenSigTimeoutTime" BU_SG_REL_ MDPS SG_ 745 PDC_FD_Crc15Val 1500;
BA_REL_ "GenSigTimeoutTime" BU_SG_REL_ RCU SG_ 745 PDC_FD_Crc15Val 1500;
BA_REL_ "GenSigTimeoutTime" BU_SG_REL_ RWA SG_ 745 PDC_FD_Crc15Val 1500;
BA_REL_ "GenSigTimeoutTime" BU_SG_REL_ RWS SG_ 745 PDC_FD_Crc15Val 1500;
BA_REL_ "GenSigTimeoutTime" BU_SG_REL_ SAS SG_ 745 PDC_FD_Crc15Val 1500;
BA_REL_ "GenSigTimeoutTime" BU_SG_REL_ SFA SG_ 745 PDC_FD_Crc15Val 1500;
BA_REL_ "GenSigTimeoutTime" BU_SG_REL_ TPMS SG_ 745 PDC_FD_Crc15Val 1500;
BA_REL_ "GenSigTimeoutTime" BU_SG_REL_ ABS SG_ 745 PDC_FD_AlvCnt15Val 1500;
BA_REL_ "GenSigTimeoutTime" BU_SG_REL_ EBB SG_ 745 PDC_FD_AlvCnt15Val 1500;
BA_REL_ "GenSigTimeoutTime" BU_SG_REL_ ECS SG_ 745 PDC_FD_AlvCnt15Val 1500;
BA_REL_ "GenSigTimeoutTime" BU_SG_REL_ EPB SG_ 745 PDC_FD_AlvCnt15Val 1500;
BA_REL_ "GenSigTimeoutTime" BU_SG_REL_ ESC SG_ 745 PDC_FD_AlvCnt15Val 1500;
BA_REL_ "GenSigTimeoutTime" BU_SG_REL_ GW_RGW SG_ 745 PDC_FD_AlvCnt15Val 1500;
BA_REL_ "GenSigTimeoutTime" BU_SG_REL_ ICSC SG_ 745 PDC_FD_AlvCnt15Val 1500;
BA_REL_ "GenSigTimeoutTime" BU_SG_REL_ MDPS SG_ 745 PDC_FD_AlvCnt15Val 1500;
BA_REL_ "GenSigTimeoutTime" BU_SG_REL_ RCU SG_ 745 PDC_FD_AlvCnt15Val 1500;
BA_REL_ "GenSigTimeoutTime" BU_SG_REL_ RWA SG_ 745 PDC_FD_AlvCnt15Val 1500;
BA_REL_ "GenSigTimeoutTime" BU_SG_REL_ RWS SG_ 745 PDC_FD_AlvCnt15Val 1500;
BA_REL_ "GenSigTimeoutTime" BU_SG_REL_ SAS SG_ 745 PDC_FD_AlvCnt15Val 1500;
BA_REL_ "GenSigTimeoutTime" BU_SG_REL_ SFA SG_ 745 PDC_FD_AlvCnt15Val 1500;
BA_REL_ "GenSigTimeoutTime" BU_SG_REL_ TPMS SG_ 745 PDC_FD_AlvCnt15Val 1500;
BA_REL_ "GenSigTimeoutTime" BU_SG_REL_ ABS SG_ 745 PDC_ResetPreWrngForOthers 1500;
BA_REL_ "GenSigTimeoutTime" BU_SG_REL_ EBB SG_ 745 PDC_ResetPreWrngForOthers 1500;
BA_REL_ "GenSigTimeoutTime" BU_SG_REL_ ECS SG_ 745 PDC_ResetPreWrngForOthers 1500;
BA_REL_ "GenSigTimeoutTime" BU_SG_REL_ EPB SG_ 745 PDC_ResetPreWrngForOthers 1500;
BA_REL_ "GenSigTimeoutTime" BU_SG_REL_ ESC SG_ 745 PDC_ResetPreWrngForOthers 1500;
BA_REL_ "GenSigTimeoutTime" BU_SG_REL_ GW_RGW SG_ 745 PDC_ResetPreWrngForOthers 1500;
BA_REL_ "GenSigTimeoutTime" BU_SG_REL_ ICSC SG_ 745 PDC_ResetPreWrngForOthers 1500;
BA_REL_ "GenSigTimeoutTime" BU_SG_REL_ MDPS SG_ 745 PDC_ResetPreWrngForOthers 1500;
BA_REL_ "GenSigTimeoutTime" BU_SG_REL_ RCU SG_ 745 PDC_ResetPreWrngForOthers 1500;
BA_REL_ "GenSigTimeoutTime" BU_SG_REL_ RWA SG_ 745 PDC_ResetPreWrngForOthers 1500;
BA_REL_ "GenSigTimeoutTime" BU_SG_REL_ RWS SG_ 745 PDC_ResetPreWrngForOthers 1500;
BA_REL_ "GenSigTimeoutTime" BU_SG_REL_ SAS SG_ 745 PDC_ResetPreWrngForOthers 1500;
BA_REL_ "GenSigTimeoutTime" BU_SG_REL_ SFA SG_ 745 PDC_ResetPreWrngForOthers 1500;
BA_REL_ "GenSigTimeoutTime" BU_SG_REL_ TPMS SG_ 745 PDC_ResetPreWrngForOthers 1500;
BA_REL_ "GenSigTimeoutTime" BU_SG_REL_ ABS SG_ 745 PDC_ResetReqForOthers 1500;
BA_REL_ "GenSigTimeoutTime" BU_SG_REL_ EBB SG_ 745 PDC_ResetReqForOthers 1500;
BA_REL_ "GenSigTimeoutTime" BU_SG_REL_ ECS SG_ 745 PDC_ResetReqForOthers 1500;
BA_REL_ "GenSigTimeoutTime" BU_SG_REL_ EPB SG_ 745 PDC_ResetReqForOthers 1500;
BA_REL_ "GenSigTimeoutTime" BU_SG_REL_ ESC SG_ 745 PDC_ResetReqForOthers 1500;
BA_REL_ "GenSigTimeoutTime" BU_SG_REL_ GW_RGW SG_ 745 PDC_ResetReqForOthers 1500;
BA_REL_ "GenSigTimeoutTime" BU_SG_REL_ ICSC SG_ 745 PDC_ResetReqForOthers 1500;
BA_REL_ "GenSigTimeoutTime" BU_SG_REL_ MDPS SG_ 745 PDC_ResetReqForOthers 1500;
BA_REL_ "GenSigTimeoutTime" BU_SG_REL_ RCU SG_ 745 PDC_ResetReqForOthers 1500;
BA_REL_ "GenSigTimeoutTime" BU_SG_REL_ RWA SG_ 745 PDC_ResetReqForOthers 1500;
BA_REL_ "GenSigTimeoutTime" BU_SG_REL_ RWS SG_ 745 PDC_ResetReqForOthers 1500;
BA_REL_ "GenSigTimeoutTime" BU_SG_REL_ SAS SG_ 745 PDC_ResetReqForOthers 1500;
BA_REL_ "GenSigTimeoutTime" BU_SG_REL_ SFA SG_ 745 PDC_ResetReqForOthers 1500;
BA_REL_ "GenSigTimeoutTime" BU_SG_REL_ TPMS SG_ 745 PDC_ResetReqForOthers 1500;
BA_REL_ "GenSigTimeoutTime" BU_SG_REL_ CGW_CCU SG_ 1168 SFA_02_Crc2Val 5000;
BA_REL_ "GenSigTimeoutTime" BU_SG_REL_ CGW_CCU SG_ 1168 SFA_02_AlvCnt2Val 5000;
BA_REL_ "GenSigTimeoutTime" BU_SG_REL_ CGW_CCU SG_ 1168 SFA_AlignWarningLamp 5000;
BA_REL_ "GenSigTimeoutTime" BU_SG_REL_ CGW_CCU SG_ 1669 CCP_MDPS_SFA_RESP1_Byte0 0;
BA_REL_ "GenSigTimeoutTime" BU_SG_REL_ CGW_CCU SG_ 1669 CCP_MDPS_SFA_RESP1_Byte2 0;
BA_REL_ "GenSigTimeoutTime" BU_SG_REL_ CGW_CCU SG_ 1669 CCP_MDPS_SFA_RESP1_Byte3 0;
BA_REL_ "GenSigTimeoutTime" BU_SG_REL_ CGW_CCU SG_ 1669 CCP_MDPS_SFA_RESP1_Byte4 0;
BA_REL_ "GenSigTimeoutTime" BU_SG_REL_ CGW_CCU SG_ 1669 CCP_MDPS_SFA_RESP1_Byte5 0;
BA_REL_ "GenSigTimeoutTime" BU_SG_REL_ CGW_CCU SG_ 1669 CCP_MDPS_SFA_RESP1_Byte6 0;
BA_REL_ "GenSigTimeoutTime" BU_SG_REL_ CGW_CCU SG_ 1669 CCP_MDPS_SFA_RESP1_Byte7 0;
BA_REL_ "GenSigTimeoutTime" BU_SG_REL_ CGW_CCU SG_ 1669 CCP_MDPS_SFA_RESP1_Byte1 0;
BA_REL_ "GenSigTimeoutTime" BU_SG_REL_ CGW_CCU SG_ 1671 CCP_MDPS_RWA_RESP3_Byte0 0;
BA_REL_ "GenSigTimeoutTime" BU_SG_REL_ CGW_CCU SG_ 1671 CCP_MDPS_RWA_RESP3_Byte2 0;
BA_REL_ "GenSigTimeoutTime" BU_SG_REL_ CGW_CCU SG_ 1671 CCP_MDPS_RWA_RESP3_Byte3 0;
BA_REL_ "GenSigTimeoutTime" BU_SG_REL_ CGW_CCU SG_ 1671 CCP_MDPS_RWA_RESP3_Byte4 0;
BA_REL_ "GenSigTimeoutTime" BU_SG_REL_ CGW_CCU SG_ 1671 CCP_MDPS_RWA_RESP3_Byte5 0;
BA_REL_ "GenSigTimeoutTime" BU_SG_REL_ CGW_CCU SG_ 1671 CCP_MDPS_RWA_RESP3_Byte6 0;
BA_REL_ "GenSigTimeoutTime" BU_SG_REL_ CGW_CCU SG_ 1671 CCP_MDPS_RWA_RESP3_Byte7 0;
BA_REL_ "GenSigTimeoutTime" BU_SG_REL_ CGW_CCU SG_ 1671 CCP_MDPS_RWA_RESP3_Byte1 0;
VAL_ 2683321087 SFA_DTC_Status 1 "DTC occurs" 0 "no DTC" ;
VAL_ 2683321087 Align_DiffAg 32768 "0x8000~0xFFFF:real value" 32767 "Error Indicator" 0 "0x0000~0x7FFE:real value" ;
VAL_ 2683321087 ECU1_PrvCANSts 1 "Invalid" 0 "Valid" ;
VAL_ 2683321087 SFA_IMCStatus 1 "Invalid" 0 "Valid" ;
VAL_ 2683321087 SFA1_OLPStatus 1 "Actived" 0 "Inactive" ;
VAL_ 2683321087 SFA1_OHPStatus 1 "Actived" 0 "Inactive" ;
VAL_ 2683321087 SFA1_MotorCur 0 "MotOutTq*MotAgSpdFild/BattU" ;
VAL_ 2683321087 SFA1_IGNStatus 1 "OFF" 0 "ON" ;
VAL_ 2683325183 RWA_IMCStatus 1 "Invalid" 0 "Valid" ;
VAL_ 2683325183 RWA_DTC_Status 1 "DTC occurs" 0 "no DTC" ;
VAL_ 2683325183 RWA1_IGNStatus 1 "OFF" 0 "ON" ;
VAL_ 2683325183 RWA1_AbsoulteAng 32768 "0x8000~0xFFFF:real value" 32767 "Error Indicator" 0 "0x0000~0x7FFE:real value" ;
VAL_ 0 WakeUp_DoorLock_DrvDrUnLkSta 0 "Lock" 1 "Unlock" 2 "Default" 3 "Error Indicator" ;
VAL_ 0 WakeUp_DoorLock_AsstDrUnLkSta 0 "Lock" 1 "Unlock" 2 "Default" 3 "Error Indicator" ;
VAL_ 0 WakeUp_Warn_AsstDrSwSta 0 "Close" 1 "Open" 2 "Default" 3 "Error Indicator" ;
VAL_ 0 WakeUp_Warn_DrvDrSwSta 0 "Close" 1 "Open" 2 "Default" 3 "Error Indicator" ;
VAL_ 548 ALDC_Crc1Val 0 "0x0x0~0xFFFF:CRCValue" 65535 "0x0x0~0xFFFF:CRCValue" ;
VAL_ 548 ALDC_AlvCnt1Val 0 "0x0x0~0xFF:AlvCntValue" 255 "0x0x0~0xFF:AlvCntValue" ;
VAL_ 548 ALDC_SysOpSta 0 "PWM off" 1 "PWM on" 2 "Not used" 3 "Error indicator" ;
VAL_ 548 ALDC_SysFltSta 0 "Normal status" 1 "Fault status" 2 "Not used" 3 "Error indicator" ;
VAL_ 549 CLU_Crc2Val 0 "0x0x0~0xFFFF:CRCValue" 65535 "0x0x0~0xFFFF:CRCValue" ;
VAL_ 549 CLU_DrvngModSwSta 0 "Off" 1 "Normal" 2 "Eco" 3 "Sport" 4 "Sport+" 5 "Smart" 6 "Custom(Custom#1_N)" 7 "N-mode" 8 "Reserved" 9 "Custom#2_N" 10 "Reserved" 11 "Reserved" 12 "Reserved" 13 "Reserved" 14 "Reserved" 15 "Invalid" ;
VAL_ 549 CLU_AlvCnt2Val 0 "0x0x0~0xFF:AlvCntValue" 255 "0x0x0~0xFF:AlvCntValue" ;
VAL_ 517 ICSC_Crc2Val 0 "0x0x0~0xFFFF:CRCValue" 65535 "0x0x0~0xFFFF:CRCValue" ;
VAL_ 517 ICSC_AlvCnt2Val 0 "0x0x0~0xFF:AlvCntValue" 255 "0x0x0~0xFF:AlvCntValue" ;
VAL_ 517 DMIC_MdpsModSta 0 "0FF" 1 "ON" 2 "Comfort(Normal)" 3 "Comfort+(Comfort)" 4 "ECO" 5 "Sport" 6 "Sport+" 7 "Smart" 8 "VIP" 9 "Baby" 10 "Snow" 11 "Retro" 12 "RESERVED" 13 "RESERVED" 14 "RESERVED" 15 "Error Indicator" ;
VAL_ 520 HOD_FD_Crc1Val 0 "0x0x0~0xFFFF:CRCValue" 65535 "0x0x0~0xFFFF:CRCValue" ;
VAL_ 520 HOD_FD_AlvCnt1Val 0 "0x0x0~0xFF:AlvCntValue" 255 "0x0x0~0xFF:AlvCntValue" ;
VAL_ 520 HOD_Dir_Status 0 "HANDS OFF" 1 "HAND TOUCH (SOFT)" 2 "HAND TOUCH (STRONG)" 3 "HAND GRIP (SOFT)" 4 "HAND GRIP (STRONG)" 5 "RESERVED" 6 "RESERVED" 7 "INVALID" ;
VAL_ 520 HOD_Option 0 "HOD-Option-OFF" 1 "HOD-Option-On" 2 "RESERVED" 3 "RESERVED" ;
VAL_ 53 VCU_Crc1Val 0 "0x0x0~0xFFFF:CRCValue" 65535 "0x0x0~0xFFFF:CRCValue" ;
VAL_ 53 VCU_AlvCnt1Val 0 "0x0x0~0xFF:AlvCntValue" 255 "0x0x0~0xFF:AlvCntValue" ;
VAL_ 53 VCU_EvDrvRdySta 0 "None" 1 "EV Drivable" 2 "Not used" 3 "Error Indicator" ;
VAL_ 53 VCU_GearPosSta 0 "P" 1 "B" 2 "Not Used" 3 "Not Used" 4 "Not Used" 5 "D" 6 "N" 7 "R" 8 "Not Used" 9 "Not Display at Cluster" 10 "Reserved" 11 "Reserved" 12 "Reserved" 13 "Reserved" 14 "Intermediate Position" 15 "Fault" ;
VAL_ 53 VCU_AccPedDepVal 255 "Error Indicator" ;
VAL_ 64 TCU_CurrGearSta 0 "if N or P are detected (no frictional connection)" 1 "1st speed" 2 "2nd speed" 3 "3rd speed" 4 "4th speed" 5 "5th speed" 6 "6th speed" 7 "7th speed" 8 "8th speed" 14 "Reverse speed" ;
VAL_ 74 IMU_Crc1Val 0 "0x0x0~0xFFFF:CRCValue" 65535 "0x0x0~0xFFFF:CRCValue" ;
VAL_ 74 IMU_AlvCnt1Val 0 "0x0x0~0xFF:AlvCntValue" 255 "0x0x0~0xFF:AlvCntValue" ;
VAL_ 101 IEB_BrkActvSta 0 "ECU does not support this function." 1 "Brake switch is not pressed (OFF)" 2 "Brake switch is pressed (ON)" 3 "Brake switch failure" ;
VAL_ 96 ESC_Crc1Val 0 "0x0x0~0xFFFF:CRCValue" 65535 "0x0x0~0xFFFF:CRCValue" ;
VAL_ 96 ESC_CylPrsrVal 4095 "Error" ;
VAL_ 96 ESC_VsmActvSta 0 "VSM control inactive" 1 "VSM control active" 2 "Not used" 3 "Error Indicator" ;
VAL_ 96 ESC_VsmDfctvSta 0 "VSM is not defective" 1 "VSM is defective" 2 "Not used" 3 "Error Indicator" ;
VAL_ 96 ESC_VsmCtrlModSta 0 "Inactive" 1 "Mode 1 (sensor value overlay mode)" 2 "Mode 2 (output torque overlay mode)" 3 "Mode 3 (Particular control)" ;
VAL_ 96 ESC_AlvCnt1Val 0 "0x0x0~0xFF:AlvCntValue" 255 "0x0x0~0xFF:AlvCntValue" ;
VAL_ 96 ESC_StrTqReq 4095 "Error" ;
VAL_ 96 TCS_Sta 0 "Not Applied" 1 "Off" 2 "Ready" 3 "Activated" 4 "Reserved" 5 "Reserved" 6 "Reserved" 7 "Reserved" 8 "Reserved" 9 "Reserved" 10 "Reserved" 11 "Reserved" 12 "Reserved" 13 "Reserved" 14 "Not Coded" 15 "Defective" ;
VAL_ 96 ESC_Sta 0 "Not Applied" 1 "Off" 2 "Ready" 3 "Activated" 4 "Reserved" 5 "Reserved" 6 "Reserved" 7 "Reserved" 8 "Reserved" 9 "Reserved" 10 "Reserved" 11 "Reserved" 12 "Reserved" 13 "Reserved" 14 "Not Coded" 15 "Defective" ;
VAL_ 111 ABS_ESC_Crc1Val 0 "0x0x0~0xFFFF:CRCValue" 65535 "0x0x0~0xFFFF:CRCValue" ;
VAL_ 111 ABS_ESC_AlvCnt1Val 0 "0x0x0~0xFF:AlvCntValue" 255 "0x0x0~0xFF:AlvCntValue" ;
VAL_ 111 ABS_ActvSta 0 "ABS control inactive" 1 "ABS control active" 2 "Not used" 3 "Error Indicator" ;
VAL_ 111 ABS_DiagSta 0 "ABS&TCS&ESC is not in diagnostic mode" 1 "ABS&TCS&ESC is in diagnostic mode" 2 "Not used" 3 "Error Indicator" ;
VAL_ 597 LDC_SysOpSta 0 "PWM off" 1 "PWM on" 2 "Not used" 3 "Error indicator" ;
VAL_ 597 LDC_SysFltSta 0 "Normal status" 1 "Fault status" 2 "Not used" 3 "Error indicator" ;
VAL_ 647 CCU_update_enable 0 "disable" 1 "enable" 2 "reserved" 3 "invalid (default)" ;
VAL_ 160 WHL_Crc1Val 0 "0x0x0~0xFFFF:CRCValue" 65535 "0x0x0~0xFFFF:CRCValue" ;
VAL_ 160 WHL_SpdRRVal 16383 "Error" ;
VAL_ 160 WHL_AlvCnt1Val 0 "0x0x0~0xFF:AlvCntValue" 255 "0x0x0~0xFF:AlvCntValue" ;
VAL_ 160 WHL_SpdFLVal 16383 "Error" ;
VAL_ 160 WHL_SpdFRVal 16383 "Error" ;
VAL_ 160 WHL_SpdRLVal 16383 "Error" ;
VAL_ 176 ICSC_Crc1Val 0 "0x0x0~0xFFFF:CRCValue" 65535 "0x0x0~0xFFFF:CRCValue" ;
VAL_ 176 ICSC_AlvCnt1Val 0 "0x0x0~0xFF:AlvCntValue" 255 "0x0x0~0xFF:AlvCntValue" ;
VAL_ 176 ESA_MdpsActvSta 0 "ESA inactive" 1 "ESA active" 2 "Not used" 3 "Error Indicator" ;
VAL_ 176 ESA_MdpsDfctvSta 0 "ESA is not defective" 1 "ESA is defective" 2 "Not used" 3 "Error Indicator" ;
VAL_ 176 SFO_ActvSta 0 "SFO Inactive" 1 "SFO Activate" 2 "RESERVED" 3 "RESERVED" 4 "RESERVED" 5 "RESERVED" 6 "Not Used" 7 "Error Indicator" ;
VAL_ 745 PDC_FD_Crc15Val 0 "0x0x0~0xFFFF:CRCValue" 65535 "0x0x0~0xFFFF:CRCValue" ;
VAL_ 745 PDC_FD_AlvCnt15Val 0 "0x0x0~0xFF:AlvCntValue" 255 "0x0x0~0xFF:AlvCntValue" ;
VAL_ 745 PDC_ResetPreWrngForOthers 0 "No Warning" 1 "Warning" 2 "RESERVED" 3 "Invalid" ;
VAL_ 745 PDC_ResetReqForOthers 0 "No Requeset" 1 "Reset Requeset" 2 "RESERVED" 3 "Invalid" ;
VAL_ 203 ADAS_CMD_Crc35Val 0 "0x0x0~0xFFFF:CRCValue" 65535 "0x0x0~0xFFFF:CRCValue" ;
VAL_ 203 ADAS_CMD_AlvCnt35Val 0 "0x0x0~0xFF:AlvCntValue" 255 "0x0x0~0xFF:AlvCntValue" ;
VAL_ 203 ADAS_ActvACISta 0 "INIT" 1 "INACTIVE" 2 "ACTIVE35(ACTIVE)" 3 "ACTIVE33(Redundancy)" 4 "RESERVED" 5 "RESERVED" 6 "RESERVED" 7 "RESERVED" 8 "RESERVED" 9 "RESERVED" 10 "RESERVED" 11 "RESERVED" 12 "RESERVED" 13 "RESERVED" 14 "RESERVED" 15 "RESERVED" ;
VAL_ 203 ADAS_ActvACILvl2Sta 0 "INIT" 1 "INACTIVE" 2 "ACTIVE35(ACTIVE)" 3 "RESERVED" 4 "RESERVED" 5 "RESERVED" 6 "RESERVED" 7 "RESERVED" 8 "RESERVED" 9 "RESERVED" 10 "RESERVED" 11 "RESERVED" 12 "RESERVED" 13 "RESERVED" 14 "RESERVED" 15 "RESERVED" ;
VAL_ 203 ADAS_StrAnglReqVal 0 "0x0x000~0x3FFF:Real Values" 16383 "0x0x000~0x3FFF:Real Values" ;
VAL_ 203 ADAS_ACIAnglTqRedcGainVal 0 "0x0x00~0xFA:Real Values" 250 "0x0x00~0xFA:Real Values" 251 "RESERVED" 252 "RESERVED" 253 "RESERVED" 254 "RESERVED" 255 "RESERVED" ;
VAL_ 203 FCA_ESA_ActvSta 0 "Inactive" 1 "Active" 2 "RESERVED" 3 "RESERVED" ;
VAL_ 203 FCA_ESA_TqBstGainVal 0 "0x0x00~0xFA:Real Values" 250 "0x0x00~0xFA:Real Values" 251 "RESERVED" 252 "RESERVED" 253 "RESERVED" 254 "RESERVED" 255 "RESERVED" ;
VAL_ 1168 SFA_02_Crc2Val 0 "0x0x0~0xFFFF:CRCValue" 65535 "0x0x0~0xFFFF:CRCValue" ;
VAL_ 1168 SFA_02_AlvCnt2Val 0 "0x0x0~0xFF:AlvCntValue" 255 "0x0x0~0xFF:AlvCntValue" ;
VAL_ 1168 SFA_AlignWarningLamp 0 "OFF" 1 "On Aligning" 2 "Aligning Success 2nd" 3 "Aligning Disturb 1st,2nd,3rd" 4 "Aligning Fail" 5 "Alingning Fully Fail" 6 "RESERVED" 7 "RESERVED" 8 "RESERVED" 9 "RESERVED" 10 "RESERVED" 11 "RESERVED" 12 "RESERVED" 13 "RESERVED" 14 "RESERVED" 15 "Error Indicator" ;
VAL_ 221 Rack_Command_Diff 524000 "ZeroAngle" ;
VAL_ 221 SFA1_RelativeAg 32768 "0x8000~0xFFFF:real value" 32767 "Error Indicator" 0 "0x0000~0x7FFE:real value" ;
VAL_ 221 SFA1_MotorTq 4095 "Error Indicator" 4094 "RESERVED" 0 "0x000~0xFFD:real values" ;
VAL_ 221 SFA1_AbsoluteAg 32768 "0x8000~0xFFFF:real value" 32767 "Error Indicator" 0 "0x0000~0x7FFE:real value" ;
VAL_ 221 SFA_Crc1Val 0 "0x0x0~0xFFFF:CRCValue" 65535 "0x0x0~0xFFFF:CRCValue" ;
VAL_ 221 SFA_CenteringStatus 0 "SteeringAligned" 1 "RESERVED" 2 "AlignmentNeeded" 3 "CenteringNeeded" 4 "RESERVED" 5 "RESERVED" 6 "RESERVED" 7 "SNA" ;
VAL_ 221 SbW_CenteringStatus 0 "SteeringAligned" 1 "RESERVED" 2 "AlignmentNeeded" 3 "CenteringNeeded" 4 "RESERVED" 5 "RESERVED" 6 "RESERVED" 7 "SNA" ;
VAL_ 221 SFA_IgnitionStatus 0 "ON" 1 "OFF" ;
VAL_ 221 SFA_OHP_Status 0 "Inactive" 1 "Actived" ;
VAL_ 221 SFA_SFA1EcuStatus 0 "Init_Arbn" 1 "Init_EcuPhaCutTst" 2 "Init_Cmpl" 3 "Passive" 4 "Passive_Fault" 5 "Assist_Active" 6 "Assist_Standby" 7 "RESERVED" 8 "RESERVED" 9 "PowerDown_Ready" 10 "RESEVERD" 11 "RESEVERD" 12 "RESEVERD" 13 "RESEVERD" 14 "RESEVERD" 15 "Invalid" ;
VAL_ 221 SFA_SFA2EcuStatus 0 "Init_Arbn" 1 "Init_EcuPhaCutTst" 2 "Init_Cmpl" 3 "Passive" 4 "Passive_Fault" 5 "Assist_Active" 6 "Assist_Standby" 7 "RESERVED" 8 "RESERVED" 9 "PowerDown_Ready" 10 "RESEVERD" 11 "RESEVERD" 12 "RESEVERD" 13 "RESEVERD" 14 "RESEVERD" 15 "Invalid" ;
VAL_ 221 SFA_RWA1EcuStatus 0 "Init_Arbn" 1 "Init_EcuPhaCutTst" 2 "Init_Cmpl" 3 "Passive" 4 "Passive_Fault" 5 "Assist_Active" 6 "Assist_Standby" 7 "RESERVED" 8 "RESERVED" 9 "PowerDown_Ready" 10 "RESEVERD" 11 "RESEVERD" 12 "RESEVERD" 13 "RESEVERD" 14 "RESEVERD" 15 "Invalid" ;
VAL_ 221 SFA_RWA2EcuStatus 0 "Init_Arbn" 1 "Init_EcuPhaCutTst" 2 "Init_Cmpl" 3 "Passive" 4 "Passive_Fault" 5 "Assist_Active" 6 "Assist_Standby" 7 "RESERVED" 8 "RESERVED" 9 "PowerDown_Ready" 10 "RESEVERD" 11 "RESEVERD" 12 "RESEVERD" 13 "RESEVERD" 14 "RESEVERD" 15 "Invalid" ;
VAL_ 221 SFA_SteerWheelAngSpd 0 "0x0x00~0xFE:real values" 254 "0x0x00~0xFE:real values" 255 "Error Indicator" ;
VAL_ 221 SFA_AlvCnt1Val 0 "0x0x0~0xFF:AlvCntValue" 255 "0x0x0~0xFF:AlvCntValue" ;
VAL_ 221 SFA_SteerWheelTorque 4094 "OutSpec" 4095 "SNA" ;
VAL_ 221 SFA_SteerWheelAngle 65534 "OutSpec" 65535 "SNA" ;
VAL_ 221 Reprogram_State_SFA1 0 "normal operation" 1 "reprogramming" 2 "RESERVED" 3 "Invalid (default)" ;
VAL_ 221 SFA1_ResetOpSta 0 "Normal" 1 "Reset Complete" 2 "Reset Fail" 3 "RESERVED" ;
VAL_ 221 SFA_ControlMode 0 "Standby" 1 "SelfCentering" 2 "SoftlockNotAlign" 3 "SoftlockAlignCmp" 4 "SFAAlignment" 5 "Normal" 6 "EmergencyNormal" 7 "EmergencySFAOnly" ;
VAL_ 221 SFA_EcuRole 0 "Master" 1 "Slave" 2 "RESERVED" 3 "SNA" ;
VAL_ 221 SFA_WarningLamp 0 "Off" 1 "Yellow" 2 "YellowFlashing" 3 "Red" 4 "RESERVED" 5 "RESERVED" 6 "RESERVED" 7 "SNA" ;
VAL_ 221 SFA_RackCommand 524000 "ZeroAngle" ;
VAL_ 221 SFA_FailoverActvSta 0 "Inactive" 1 "Active" 2 "RESERVED" 3 "RESERVED" 4 "RESERVED" 5 "RESERVED" 6 "Not Used" 7 "Error Indicator" ;
VAL_ 221 SFA_BrakeReqActSta 0 "Inactive" 1 "Active" 2 "RESERVED" 3 "RESERVED" 4 "RESERVED" 5 "RESERVED" 6 "Not Used" 7 "Error Indicator" ;
VAL_ 221 SFA_CreepReqActSta 0 "Inactive" 1 "Active High Speed" 2 "Active Low Speed" 3 "Active Stop in Lane" 4 "RESERVED" 5 "RESERVED" 6 "Not Used" 7 "Error Indicator" ;
VAL_ 221 SbW_EvDrvRdyEnb 0 "Inactive" 1 "Active" 2 "Not Used" 3 "Not Used" 4 "Not Used" 5 "Not Used" 6 "Not Used" 7 "Error Indicator" ;
VAL_ 221 SFA_CluWarningLamp 0 "SbW Malfunction Warning lamp OFF" 1 "SbW Malfunction Warning lamp Yellow" 2 "SbW Malfunction Warning lamp Red" 3 "SbW Diagnosis [1Hz]" ;
VAL_ 221 SFA_CluWarningSentence 0 "SbW Malfunction Sentence OFF" 1 "SbW Malfunciton Sentence ①" 2 "SbW Malfunciton Sentence ②" 3 "SbW Malfunciton Sentence ③" 4 "SbW Malfunciton Sentence ④" 5 "SbW Malfunciton Sentence ⑤" 6 "SbW Malfunction Sentence ⑥" 7 "SbW Malfunction Sentence ⑦" 8 "SbW Malfunction Sentence ⑧" 9 "RESERVED" 10 "RESERVED" 11 "RESERVED" 12 "RESERVED" 13 "RESERVED" 14 "RESERVED" 15 "Error Indicator" ;
VAL_ 222 RWA1_RelatIveAg 32768 "0x8000~0xFFFF:real value" 32767 "Error Indicator" 0 "0x0000~0x7FFE:real value" ;
VAL_ 222 RWA1_MotorTorque 4095 "Error Indicator" 4094 "RESERVED" 0 "0x000~0xFFD:real values" ;
VAL_ 222 RWA1_MotorCur 0 "MotOutTq*MotAgSpdFild/BattU" ;
VAL_ 222 RWA1_AOSAg 32768 "0x8000~0xFFFF:real value" 32767 "Error Indicator" 0 "0x0000~0x7FFE:real value" ;
VAL_ 222 RWA_Crc1Val 0 "0x0x0~0xFFFF:CRCValue" 65535 "0x0x0~0xFFFF:CRCValue" ;
VAL_ 222 RWA_IgnitionStatus 0 "ON" 1 "OFF" ;
VAL_ 222 RWA_OHP_Status 0 "Inactive" 1 "Actived" ;
VAL_ 222 RWA_SFA1EcuStatus 0 "Init_Arbn" 1 "Init_EcuPhaCutTst" 2 "Init_Cmpl" 3 "Passive" 4 "Passive_Fault" 5 "Assist_Active" 6 "Assist_Standby" 7 "RESERVED" 8 "RESERVED" 9 "PowerDown_Ready" 10 "RESEVERD" 11 "RESEVERD" 12 "RESEVERD" 13 "RESEVERD" 14 "RESEVERD" 15 "Invalid" ;
VAL_ 222 RWA_SFA2EcuStatus 0 "Init_Arbn" 1 "Init_EcuPhaCutTst" 2 "Init_Cmpl" 3 "Passive" 4 "Passive_Fault" 5 "Assist_Active" 6 "Assist_Standby" 7 "RESERVED" 8 "RESERVED" 9 "PowerDown_Ready" 10 "RESEVERD" 11 "RESEVERD" 12 "RESEVERD" 13 "RESEVERD" 14 "RESEVERD" 15 "Invalid" ;
VAL_ 222 RWA_RWA1EcuStatus 0 "Init_Arbn" 1 "Init_EcuPhaCutTst" 2 "Init_Cmpl" 3 "Passive" 4 "Passive_Fault" 5 "Assist_Active" 6 "Assist_Standby" 7 "RESERVED" 8 "RESERVED" 9 "PowerDown_Ready" 10 "RESEVERD" 11 "RESEVERD" 12 "RESEVERD" 13 "RESEVERD" 14 "RESEVERD" 15 "Invalid" ;
VAL_ 222 RWA_RWA2EcuStatus 0 "Init_Arbn" 1 "Init_EcuPhaCutTst" 2 "Init_Cmpl" 3 "Passive" 4 "Passive_Fault" 5 "Assist_Active" 6 "Assist_Standby" 7 "RESERVED" 8 "RESERVED" 9 "PowerDown_Ready" 10 "RESEVERD" 11 "RESEVERD" 12 "RESEVERD" 13 "RESEVERD" 14 "RESEVERD" 15 "Invalid" ;
VAL_ 222 RWA_CreepReqActSta 0 "Inactive" 1 "Active High Speed" 2 "Active Low Speed" 3 "Active Stop in Lane" 4 "RESERVED" 5 "RESERVED" 6 "Not Used" 7 "Error Indicator" ;
VAL_ 222 RWA_PinionAngSpd 0 "0x0x00~0xFE:real values" 254 "0x0x00~0xFE:real values" 255 "Error Indicator" ;
VAL_ 222 RWA_AlvCnt1Val 0 "0x0x0~0xFF:AlvCntValue" 255 "0x0x0~0xFF:AlvCntValue" ;
VAL_ 222 RWA_RackForce 65534 "OutSpec" 65535 "SNA" ;
VAL_ 222 RWA_RackPosition 1048574 "OutSpec" 1048575 "SNA" ;
VAL_ 222 Reprogram_State_RWA1 0 "normal operation" 1 "reprogramming" 2 "RESERVED" 3 "Invalid (default)" ;
VAL_ 222 RWA1_ResetOpSta 0 "Normal" 1 "Reset Complete" 2 "Reset Fail" 3 "RESERVED" ;
VAL_ 222 RWA_RackSpeed 1048574 "OutSpec" 1048575 "SNA" ;
VAL_ 222 RWA_EcuRole 0 "Master" 1 "Slave" 2 "RESERVED" 3 "SNA" ;
VAL_ 222 RWA_WarningLamp 0 "Off" 1 "Yellow" 2 "YellowFlashing" 3 "Red" 4 "RESERVED" 5 "RESERVED" 6 "RESERVED" 7 "SNA" ;
VAL_ 222 RWA_ControlMode 0 "Standby" 1 "SelfCentering" 2 "SoftlockNotAlign" 3 "SoftlockAlignCmp" 4 "SFAAlignment" 5 "Normal" 6 "EmergencyNormal" 7 "EmergencySFAOnly" ;
VAL_ 222 RWA_CenteringStatus 0 "SteeringAligned" 1 "RESERVED" 2 "AlignmentNeeded" 3 "CenteringNeeded" 4 "RESERVED" 5 "RESERVED" 6 "RESERVED" 7 "SNA" ;
VAL_ 222 RWA_OLP 0 "Inactive" 1 "Actived" ;
VAL_ 222 RWA_PinionAngle 32767 "Error Indicator" ;
VAL_ 238 RWA2_Crc1Val 0 "0x0x0~0xFFFF:CRCValue" 65535 "0x0x0~0xFFFF:CRCValue" ;
VAL_ 238 RWA_R2_IgnitionStatus 0 "ON" 1 "OFF" ;
VAL_ 238 RWA_R2_OHP_Status 0 "Inactive" 1 "Actived" ;
VAL_ 238 RWA_R2_SFA1EcuStatus 0 "Init_Arbn" 1 "Init_EcuPhaCutTst" 2 "Init_Cmpl" 3 "Passive" 4 "Passive_Fault" 5 "Assist_Active" 6 "Assist_Standby" 7 "RESERVED" 8 "RESERVED" 9 "PowerDown_Ready" 10 "RESEVERD" 11 "RESEVERD" 12 "RESEVERD" 13 "RESEVERD" 14 "RESEVERD" 15 "Invalid" ;
VAL_ 238 RWA_R2_SFA2EcuStatus 0 "Init_Arbn" 1 "Init_EcuPhaCutTst" 2 "Init_Cmpl" 3 "Passive" 4 "Passive_Fault" 5 "Assist_Active" 6 "Assist_Standby" 7 "RESERVED" 8 "RESERVED" 9 "PowerDown_Ready" 10 "RESEVERD" 11 "RESEVERD" 12 "RESEVERD" 13 "RESEVERD" 14 "RESEVERD" 15 "Invalid" ;
VAL_ 238 RWA_R2_RWA1EcuStatus 0 "Init_Arbn" 1 "Init_EcuPhaCutTst" 2 "Init_Cmpl" 3 "Passive" 4 "Passive_Fault" 5 "Assist_Active" 6 "Assist_Standby" 7 "RESERVED" 8 "RESERVED" 9 "PowerDown_Ready" 10 "RESEVERD" 11 "RESEVERD" 12 "RESEVERD" 13 "RESEVERD" 14 "RESEVERD" 15 "Invalid" ;
VAL_ 238 RWA_R2_RWA2EcuStatus 0 "Init_Arbn" 1 "Init_EcuPhaCutTst" 2 "Init_Cmpl" 3 "Passive" 4 "Passive_Fault" 5 "Assist_Active" 6 "Assist_Standby" 7 "RESERVED" 8 "RESERVED" 9 "PowerDown_Ready" 10 "RESEVERD" 11 "RESEVERD" 12 "RESEVERD" 13 "RESEVERD" 14 "RESEVERD" 15 "Invalid" ;
VAL_ 238 RWA_R2_CreepReqActSta 0 "Inactive" 1 "Active High Speed" 2 "Active Low Speed" 3 "Active Stop in Lane" 4 "RESERVED" 5 "RESERVED" 6 "Not Used" 7 "Error Indicator" ;
VAL_ 238 RWA_R2_PinionAngSpd 0 "0x0x00~0xFE:real values" 254 "0x0x00~0xFE:real values" 255 "Error Indicator" ;
VAL_ 238 RWA2_AlvCnt1Val 0 "0x0x0~0xFF:AlvCntValue" 255 "0x0x0~0xFF:AlvCntValue" ;
VAL_ 238 RWA_R2_RackForce 65534 "OutSpec" 65535 "SNA" ;
VAL_ 238 RWA_R2_RackPosition 1048574 "OutSpec" 1048575 "SNA" ;
VAL_ 238 RWA_R2_RackSpeed 1048574 "OutSpec" 1048575 "SNA" ;
VAL_ 238 RWA_R2_EcuRole 0 "Master" 1 "Slave" 2 "RESERVED" 3 "SNA" ;
VAL_ 238 RWA_R2_WarningLamp 0 "Off" 1 "Yellow" 2 "YellowFlashing" 3 "Red" 4 "RESERVED" 5 "RESERVED" 6 "RESERVED" 7 "SNA" ;
VAL_ 238 RWA_R2_ControlMode 0 "Standby" 1 "SelfCentering" 2 "SoftlockNotAlign" 3 "SoftlockAlignCmp" 4 "SFAAlignment" 5 "Normal" 6 "EmergencyNormal" 7 "EmergencySFAOnly" ;
VAL_ 238 RWA_R2_CenteringStatus 0 "SteeringAligned" 1 "RESERVED" 2 "AlignmentNeeded" 3 "CenteringNeeded" 4 "RESERVED" 5 "RESERVED" 6 "RESERVED" 7 "SNA" ;
VAL_ 238 RWA_R2_OLP 0 "Inactive" 1 "Actived" ;
VAL_ 238 RWA_R2_PinionAngle 32767 "Error Indicator" ;
VAL_ 237 SFA2_Crc1Val 0 "0x0x0~0xFFFF:CRCValue" 65535 "0x0x0~0xFFFF:CRCValue" ;
VAL_ 237 SFA_R2_CenteringStatus 0 "SteeringAligned" 1 "RESERVED" 2 "AlignmentNeeded" 3 "CenteringNeeded" 4 "RESERVED" 5 "RESERVED" 6 "RESERVED" 7 "SNA" ;
VAL_ 237 SbW_R2_CenteringStatus 0 "SteeringAligned" 1 "RESERVED" 2 "AlignmentNeeded" 3 "CenteringNeeded" 4 "RESERVED" 5 "RESERVED" 6 "RESERVED" 7 "SNA" ;
VAL_ 237 SFA_R2_IgnitionStatus 0 "ON" 1 "OFF" ;
VAL_ 237 SFA_R2_OHP_Status 0 "Inactive" 1 "Actived" ;
VAL_ 237 SFA_R2_SFA1EcuStatus 0 "Init_Arbn" 1 "Init_EcuPhaCutTst" 2 "Init_Cmpl" 3 "Passive" 4 "Passive_Fault" 5 "Assist_Active" 6 "Assist_Standby" 7 "RESERVED" 8 "RESERVED" 9 "PowerDown_Ready" 10 "RESEVERD" 11 "RESEVERD" 12 "RESEVERD" 13 "RESEVERD" 14 "RESEVERD" 15 "Invalid" ;
VAL_ 237 SFA_R2_SFA2EcuStatus 0 "Init_Arbn" 1 "Init_EcuPhaCutTst" 2 "Init_Cmpl" 3 "Passive" 4 "Passive_Fault" 5 "Assist_Active" 6 "Assist_Standby" 7 "RESERVED" 8 "RESERVED" 9 "PowerDown_Ready" 10 "RESEVERD" 11 "RESEVERD" 12 "RESEVERD" 13 "RESEVERD" 14 "RESEVERD" 15 "Invalid" ;
VAL_ 237 SFA_R2_RWA1EcuStatus 0 "Init_Arbn" 1 "Init_EcuPhaCutTst" 2 "Init_Cmpl" 3 "Passive" 4 "Passive_Fault" 5 "Assist_Active" 6 "Assist_Standby" 7 "RESERVED" 8 "RESERVED" 9 "PowerDown_Ready" 10 "RESEVERD" 11 "RESEVERD" 12 "RESEVERD" 13 "RESEVERD" 14 "RESEVERD" 15 "Invalid" ;
VAL_ 237 SFA_R2_RWA2EcuStatus 0 "Init_Arbn" 1 "Init_EcuPhaCutTst" 2 "Init_Cmpl" 3 "Passive" 4 "Passive_Fault" 5 "Assist_Active" 6 "Assist_Standby" 7 "RESERVED" 8 "RESERVED" 9 "PowerDown_Ready" 10 "RESEVERD" 11 "RESEVERD" 12 "RESEVERD" 13 "RESEVERD" 14 "RESEVERD" 15 "Invalid" ;
VAL_ 237 SFA_R2_SteerWheelAngSpd 0 "0x0x00~0xFE:real values" 254 "0x0x00~0xFE:real values" 255 "Error Indicator" ;
VAL_ 237 SFA2_AlvCnt1Val 0 "0x0x0~0xFF:AlvCntValue" 255 "0x0x0~0xFF:AlvCntValue" ;
VAL_ 237 SFA_R2_SteerWheelTorque 4094 "OutSpec" 4095 "SNA" ;
VAL_ 237 SFA_R2_SteerWheelAngle 65534 "OutSpec" 65535 "SNA" ;
VAL_ 237 SFA_R2_ControlMode 0 "Standby" 1 "SelfCentering" 2 "SoftlockNotAlign" 3 "SoftlockAlignCmp" 4 "SFAAlignment" 5 "Normal" 6 "EmergencyNormal" 7 "EmergencySFAOnly" ;
VAL_ 237 SFA_R2_EcuRole 0 "Master" 1 "Slave" 2 "RESERVED" 3 "SNA" ;
VAL_ 237 SFA_R2_WarningLamp 0 "Off" 1 "Yellow" 2 "YellowFlashing" 3 "Red" 4 "RESERVED" 5 "RESERVED" 6 "RESERVED" 7 "SNA" ;
VAL_ 237 SFA_R2_RackCommand 524000 "ZeroAngle" ;
VAL_ 237 SFA_R2_FailoverActvSta 0 "Inactive" 1 "Active" 2 "RESERVED" 3 "RESERVED" 4 "RESERVED" 5 "RESERVED" 6 "Not Used" 7 "Error Indicator" ;
VAL_ 237 SFA_R2_BrakeReqActSta 0 "Inactive" 1 "Active" 2 "RESERVED" 3 "RESERVED" 4 "RESERVED" 5 "RESERVED" 6 "Not Used" 7 "Error Indicator" ;
VAL_ 237 SFA_R2_CreepReqActSta 0 "Inactive" 1 "Active High Speed" 2 "Active Low Speed" 3 "Active Stop in Lane" 4 "RESERVED" 5 "RESERVED" 6 "Not Used" 7 "Error Indicator" ;
VAL_ 237 SbW_R2_EvDrvRdyEnb 0 "Inactive" 1 "Active" 2 "Not Used" 3 "Not Used" 4 "Not Used" 5 "Not Used" 6 "Not Used" 7 "Error Indicator" ;
VAL_ 237 SFA_R2_CluWarningLamp 0 "SbW Malfunction Warning lamp OFF" 1 "SbW Malfunciton Warning lamp Yellow" 2 "SbW Malfunciton Warning lamp Red" 3 "SbW Diagnosis [1Hz]" ;
VAL_ 237 SFA_R2_CluWarningSentence 0 "SbW Malfunction Sentence OFF" 1 "SbW Malfunciton Sentence ①" 2 "SbW Malfunciton Sentence ②" 3 "SbW Malfunciton Sentence ③" 4 "SbW Malfunciton Sentence ④" 5 "SbW Malfunciton Sentence ⑤" 6 "SbW Malfunction Sentence ⑥" 7 "SbW Malfunction Sentence ⑦" 8 "SbW Malfunction Sentence ⑧" 9 "RESERVED" 10 "RESERVED" 11 "RESERVED" 12 "RESERVED" 13 "RESERVED" 14 "RESERVED" 15 "Error Indicator" ;
VAL_ 234 MDPS_LoamModSta 0 "Normal" 1 "Loam Flag Warning Display" 2 "RESERVED" 3 "Error Indicator" ;
VAL_ 234 MDPS_HDPSpprtSWVer 0 "HDP-MDPS Control Requirement Version" 1 "HDP-MDPS Control Requirement Version" 2 "HDP-MDPS Control Requirement Version" 3 "HDP-MDPS Control Requirement Version" 4 "HDP-MDPS Control Requirement Version" 5 "HDP-MDPS Control Requirement Version" 6 "HDP-MDPS Control Requirement Version" 7 "HDP-MDPS Control Requirement Version" 8 "HDP-MDPS Control Requirement Version" 9 "HDP-MDPS Control Requirement Version" 10 "HDP-MDPS Control Requirement Version" 11 "HDP-MDPS Control Requirement Version" 12 "HDP-MDPS Control Requirement Version" 13 "HDP-MDPS Control Requirement Version" 14 "HDP-MDPS Control Requirement Version" 15 "HDP-MDPS Control Requirement Version" 16 "HDP-MDPS Control Requirement Version" 17 "HDP-MDPS Control Requirement Version" 18 "HDP-MDPS Control Requirement Version" 19 "HDP-MDPS Control Requirement Version" 20 "HDP-MDPS Control Requirement Version" 21 "HDP-MDPS Control Requirement Version" 22 "HDP-MDPS Control Requirement Version" 23 "HDP-MDPS Control Requirement Version" 24 "HDP-MDPS Control Requirement Version" 25 "HDP-MDPS Control Requirement Version" 26 "HDP-MDPS Control Requirement Version" 27 "HDP-MDPS Control Requirement Version" 28 "HDP-MDPS Control Requirement Version" 29 "HDP-MDPS Control Requirement Version" 30 "HDP-MDPS Control Requirement Version" 31 "HDP-MDPS Control Requirement Version" ;
VAL_ 234 MDPS_ADASAciActvSta 0 "INIT" 1 "INACTIVE" 2 "ACTIVE35(ACTIVE)" 3 "ACTIVE33(Redundancy)" 4 "RESERVED" 5 "RESERVED" 6 "RESERVED" 7 "RESERVED" 8 "RESERVED" 9 "RESERVED" 10 "RESERVED" 11 "RESERVED" 12 "RESERVED" 13 "RESERVED" 14 "RESERVED" 15 "RESERVED" ;
VAL_ 234 MDPS_ADASAciPluginSta 0 "ADASAciNotPlugged-in" 1 "ADASAciPlugged-in" 2 "RESERVED" 3 "ErrorIndicator" ;
VAL_ 234 MDPS_ADAS_AciFltSig 0 "No Fault" 1 "MDPS Fault" 2 "Fault Except MDPS" 3 "Both Fault" ;
VAL_ 234 MDPS_EstStrAnglVal 0 "0x0x000~0x7FFD:real values" 32765 "0x0x000~0x7FFD:real values" 32766 "Not Initialized" 32767 "Error Indicator" 32768 "0x8000~0xFFFF:real values" 65535 "0x8000~0xFFFF:real values" ;
VAL_ 234 MDPS_ADASAciActvSta_Lv2 0 "Not USED" 1 "INACTIVE" 2 "ACTIVE35(Active)" 3 "Reserved" 4 "Reserved" 5 "Reserved" 6 "Reserved" 7 "Reserved" 8 "Reserved" 9 "Reserved" 10 "Reserved" 11 "Reserved" 12 "Reserved" 13 "Reserved" 14 "Reserved" 15 "Reserved" ;
VAL_ 234 MDPS_ADAS_AciFltSig_Lv2 0 "No Fault" 1 "MDPS Fault" 2 "Fault Except MDPS" 3 "Both Fault" 4 "Temporarily Unavailable" 5 "Temporarily Unavailable and MDPS Fault" 6 "Temporarily Unavailable and Fault Except MDPS" 7 "Temporarily Unavailable and Both Fault" ;
VAL_ 234 MDPS_TpaPlugInSta 0 "The TPA function of MDPS is not plugged in (unplugged)" 1 "The TPA function of MDPS is plugged in" 2 "RESERVED" 3 "Error Indicator" ;
VAL_ 234 MDPS_TpaCanfltSta 0 "No Failure" 1 "Failure about Tpa can message" 2 "RESERVED" 3 "Error Indicator" ;
VAL_ 234 MDPS_TpaModeSta 0 "RESERVED" 1 "Steering still in initialization phase" 2 "Steering ready, waits for TPA command" 3 "Steering set in standby by TPA" 4 "Steering requested to go to first activation step activation step" 5 "Steering requested to go to final activation step" 6 "Steering went to error internally" 7 "Steering aborted the automatic function" 14 "RESERVED" 15 "Error Indicator" ;
VAL_ 234 MDPS_TpaStrAnglVal 0 "0x0x000~0x7FFD:real values" 32765 "0x0x000~0x7FFD:real values" 32766 "Not Initialized" 32767 "Error Indicator" 32768 "0x8000~0xFFFF:real values" 65535 "0x8000~0xFFFF:real values" ;
VAL_ 234 MDPS_WrngLmpSta 0 "MDPS Malfunction Warning lamp OFF" 1 "MDPS Malfunciton Warning lamp BLANKING(2Hz)" 2 "MDPS Malfunction Warning lamp ON" 3 "MDPS Malfunction Warning lamp BLANKING(1Hz)" 4 "RESERVED" 5 "RESERVED" 6 "RESERVED" 7 "Error Indicator" ;
VAL_ 234 MDPS_Typ 0 "C-MDPS" 1 "R-MDPS(Dual Pinion)" 2 "R-MDPS(Belt)" 3 "SbW" 4 "RESERVED" 5 "RESERVED" 6 "RESERVED" 7 "Error Indicator" ;
VAL_ 234 MDPS_EngIdleRpmReq 0 "Current Consumption is Low" 1 "Current Consumption is High" 2 ":RESERVED" 3 "Error Indicator" ;
VAL_ 234 MDPS_VsmPlgInSta 0 "The VSM function of MDPS is not plugged in (unplugged)." 1 "The VSM function of MDPS is plugged in." 2 "RESERVED" 3 "Error Indicator" ;
VAL_ 234 MDPS_VsmDfctvSta 0 "MDPS is not defective" 1 "MDPS is defective" 2 "RESERVED" 3 "Error Indicator" ;
VAL_ 234 MDPS_VsmSigErrSta 0 "VSM1 signal is not error" 1 "VSM signal is error" 2 "RESERVED" 3 "Error Indicator" ;
VAL_ 234 MDPS_PaPlugInSta 0 "The PA function of MDPS is not plugged in (unplugged)." 1 "The PA function of MDPS is plugged in." 2 "RESERVED" 3 "Error Indicator" ;
VAL_ 234 MDPS_PaModeSta 0 "RESERVED" 1 "Steering still in initialization phase" 2 "Steering ready, waits for PA command" 3 "Steering set in standby by PA" 4 "Steering requested to go to first activation step" 5 "Steering requested to go to final activation step" 6 "Steering went to error internally" 7 "Steering aborted the automatic function" 8 "RESERVED" 9 "RESERVED" 10 "RESERVED" 11 "RESERVED" 12 "RESERVED" 13 "RESERVED" 14 "RESERVED" 15 "Error Indicator" ;
VAL_ 234 MDPS_PaCanfltSta 0 "No Failure" 1 "Failure about Pa can message" 2 "RESERVED" 3 "Error Indicator" ;
VAL_ 234 MDPS_LkaPlgInSta 0 "The LKA function of MDPS is not plugged in (unplugged)." 1 "The LKA function of MDPS is plugged in." 2 "RESERVED" 3 "Error Indicator" ;
VAL_ 234 MDPS_LkaToiActvSta 0 "Deactivated" 1 "Activated" 2 "RESERVED" 3 "Error Indicator" ;
VAL_ 234 MDPS_LkaToiUnblSta 0 "Available" 1 "Unavailable" 2 "RESERVED" 3 "Error Indicator" ;
VAL_ 234 MDPS_LkaToiFltSta 0 "No fault" 1 "Faulty" 2 "RESERVED" 3 "Error Indicator" ;
VAL_ 234 MDPS_LkaFailSta 0 "Not in fail state" 1 "In fail state" 2 "RESERVED" 3 "Error Indicator" ;
VAL_ 234 MDPS_ResetOpSta 0 "Normal" 1 "Reset Complete" 2 "Reset Fail" 3 "RESERVED" ;
VAL_ 234 MDPS_CurrModVal 0 "Comfort Mode" 1 "Sport Mode" 2 "Sport+ Mode" 3 "Chauffeur Mode" 4 "Mild Mode" 5 "Drift Mode" 6 "RESERVED" 7 "Error Indicator" ;
VAL_ 234 MDPS_OutTqVal 0 "0x0x000~0xFFD:real values" 4093 "0x0x000~0xFFD:real values" 4094 "RESERVED" 4095 "Error Indicator" ;
VAL_ 234 MDPS_VsmActResp 0 "VSM Control inactivated" 1 "VSM Control Activated" 2 "RESERVED" 3 "Invalid" ;
VAL_ 234 Reprogram_State_MDPS 0 "normal operation" 1 "reprogramming" 2 "RESERVED" 3 "Error Indicator" ;
VAL_ 234 MDPS_StrTqSnsrVal 0 "0x0x000~0x1FFD:real values" 8189 "0x0x000~0x1FFD:real values" 8190 "RESERVED" 8191 "Error Indicator" ;
VAL_ 234 MDPS_PaStrAnglVal 0 "0x0x000~0x7FFD:real values" 32765 "0x0x000~0x7FFD:real values" 32766 "Not Initialized" 32767 "Error Indicator" 32768 "0x8000~0xFFFF:real values" 65535 "0x8000~0xFFFF:real values" ;
